VERSION ""

NS_ :

BS_:

BU_: T_Box HUT DMS DVR GW Tester

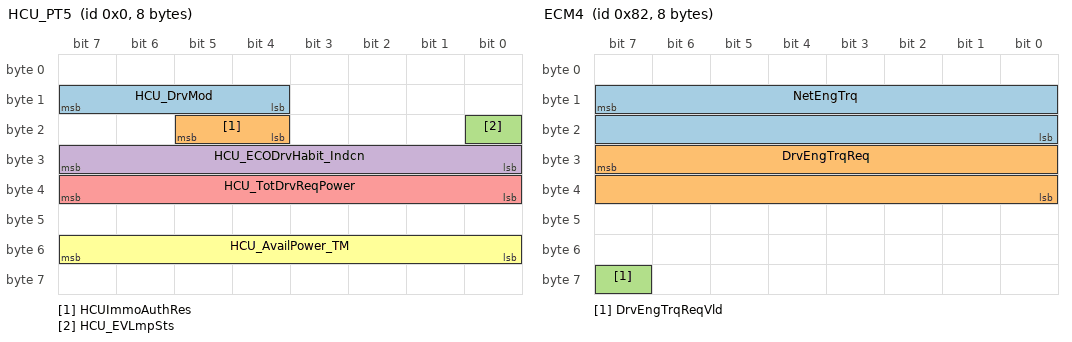
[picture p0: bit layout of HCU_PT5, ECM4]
BO_ 0 HCU_PT5: 8 GW
 SG_ HCU_DrvMod : 15|4@0+ (1,0) [0|15] ""  HUT
 SG_ HCUImmoAuthRes : 21|2@0+ (1,0) [0|3] ""  HUT
 SG_ HCU_EVLmpSts : 16|1@0+ (1,0) [0|1] ""  HUT
 SG_ HCU_ECODrvHabit_Indcn : 31|8@0+ (0.1,-10) [-10|10] ""  HUT
 SG_ HCU_TotDrvReqPower : 39|8@0+ (1,-100) [-100|100] "%"  HUT
 SG_ HCU_AvailPower_TM : 55|8@0+ (0.5,0) [0|50] "%"  HUT

BO_ 51 T_Box_FD1: 16 T_Box
 SG_ T_Box_RemtWinCtrl : 2|3@0+ (1,0) [0|7] ""  GW
 SG_ T_Box_RemtTrunkCtrl : 4|2@0+ (1,0) [0|3] ""  GW
 SG_ T_Box_RemtDoorLockCtrl : 7|3@0+ (1,0) [0|7] ""  GW,HUT
 SG_ T_Box_AudioMuteReq : 9|2@0+ (1,0) [0|3] ""  HUT
 SG_ T_Box_RemtDrvTempSet : 15|6@0+ (0.5,16) [16.5|31.5] "°C"  GW
 SG_ T_Box_RemtAutoCtrl : 17|2@0+ (1,0) [0|3] ""  GW
 SG_ T_Box_RemtPassTempSet : 23|6@0+ (0.5,16) [16.5|31.5] "°C"  GW
 SG_ T_Box_RemtSsCtrl : 27|4@0+ (1,0) [0|15] ""  GW
 SG_ T_Box_RemtSrCtrl : 31|4@0+ (1,0) [0|15] ""  GW
 SG_ T_Box_RemtDrvSeatVentnLvlSet : 34|3@0+ (1,0) [0|7] ""  GW
 SG_ T_Box_RemtPassSeatVentnLvlSet : 37|3@0+ (1,0) [0|7] ""  GW
 SG_ T_Box_RemtAIUReq : 39|2@0+ (1,0) [0|3] ""  GW
 SG_ T_Box_PM25AirQLvl : 43|4@0+ (1,0) [0|15] ""  HUT
 SG_ T_Box_RemtCarSearch : 45|2@0+ (1,0) [0|3] ""  GW
 SG_ T_Box_RemtEngCtrl : 47|2@0+ (1,0) [0|3] ""  GW
 SG_ T_Box_RemtDrvSeatHeatgLvlSet : 52|3@0+ (1,0) [0|7] ""  GW
 SG_ T_Box_RemtPassSeatHeatgLvlSet : 55|3@0+ (1,0) [0|7] ""  GW
 SG_ T_Box_PM25Dens : 49|10@0+ (1,0) [0|1023] "ug/m^3"  HUT
 SG_ FreshnessValue_T_Box_FD1 : 71|16@0+ (1,0) [0|65535] ""  GW,HUT
 SG_ MAC_Check_T_Box_FD1 : 87|48@0+ (1,0) [0|281474976710655] ""  GW,HUT

BO_ 53 PEPS5: 8 GW
 SG_ PEPS_T_BoxAuth1 : 7|64@0+ (1,0) [0|1.84467440737095E+019] ""  T_Box

BO_ 54 T_Box_FD2: 16 T_Box
 SG_ T_Box_PEPSAuth1 : 7|64@0+ (1,0) [0|1.84467440737096E+019] ""  GW

BO_ 70 PEPS11: 8 GW
 SG_ PEPS_T_BoxAuth2 : 7|64@0+ (1,0) [0|1.84467440737096E+019] ""  T_Box

BO_ 72 T_Box7: 16 T_Box
 SG_ T_Box_PEPSAuth2 : 7|64@0+ (1,0) [0|1.84467440737096E+019] ""  GW

BO_ 74 HUT6: 8 HUT
 SG_ AUTODefrost_TC : 6|2@0+ (1,0) [0|3] ""  GW
 SG_ AUTODefrost_VR : 4|2@0+ (1,0) [0|3] ""  GW
 SG_ LaneCalActvtCmd : 42|1@0+ (1,0) [0|1] ""  GW
 SG_ MODChgReq : 62|1@0+ (1,0) [0|1] ""  GW
 SG_ Radar_DispCmd : 40|1@0+ (1,0) [0|1] ""  GW
 SG_ Guid_Ovl_Display_Cmd : 7|1@0+ (1,0) [0|1] ""  GW
 SG_ Sgl_View_Sel : 36|4@0+ (1,0) [0|15] ""  GW
 SG_ SwToFieldCalRstCmd : 58|1@0+ (1,0) [0|1] ""  GW
 SG_ AutoViewChgCmd : 55|1@0+ (1,0) [0|1] ""  GW
 SG_ MdlColrChgCmd : 53|1@0+ (1,0) [0|1] ""  GW
 SG_ CarMdlTrsprcySwtCmd : 49|1@0+ (1,0) [0|1] ""  GW
 SG_ CarMdlDispCmd : 63|1@0+ (1,0) [0|1] ""  GW
 SG_ AutoAVMSwSet_Cmd : 57|1@0+ (1,0) [0|1] ""  GW
 SG_ FPAS_AutoModSwt : 60|1@0+ (1,0) [0|1] ""  GW
 SG_ MEBSwtSet : 61|1@0+ (1,0) [0|1] ""  GW
 SG_ WshSoftSwt : 56|1@0+ (1,0) [0|1] ""  GW
 SG_ View_SoftswitchCmd : 59|1@0+ (1,0) [0|1] ""  GW

BO_ 86 GLO_NASS1: 8 GW
 SG_ E_CALLSts : 2|3@0+ (1,0) [0|5] ""  HUT
 SG_ QuietVoiceReq : 7|1@0+ (1,0) [0|1] ""  HUT

BO_ 96 HCU_FD1: 64 GW
 SG_ HCU_AccelPedalPosn_Diag : 79|8@0+ (0.3937,0) [0|100.395] "%"  HUT
 SG_ HCU_AccelPedalPosn_DiagValid : 85|1@0+ (1,0) [0|1] ""  HUT
 SG_ HCU_RaceLaunchSts : 367|3@0+ (1,0) [0|7] ""  HUT
 SG_ HCU_RaceLaunchAvail : 364|2@0+ (1,0) [0|3] ""  HUT

BO_ 130 ECM4: 8 GW
 SG_ NetEngTrq : 15|16@0+ (0.0030518,-100) [-100|99.9966612] "%"  HUT
 SG_ DrvEngTrqReq : 31|16@0+ (0.0030518,-100) [-100|99.999713] "%"  HUT
 SG_ DrvEngTrqReqVld : 63|1@0+ (1,0) [0|1] ""  HUT

BO_ 132 ECM7: 8 GW
 SG_ EngTrqEstimdActGear : 31|16@0+ (0.0030518,-100) [-100|99.999713] "%"  HUT
 SG_ EngTrqEstimdActGear_Qf : 62|1@0+ (1,0) [0|1] ""  HUT

BO_ 134 ECM8: 8 GW
 SG_ TrqLoss : 47|16@0+ (0.0030518,-100) [-100|99.999713] "%"  HUT

BO_ 147 TMCU6: 8 GW
 SG_ TMCU_ActPosRotSpd : 15|16@0+ (1,0) [0|65534] "rpm"  HUT,T_Box,DMS,DVR

BO_ 161 CSA2: 8 GW
 SG_ SteerWheelAng : 15|15@0+ (0.1,0) [0|780] "deg"  HUT,DMS
 SG_ SteerWheelAngSign : 16|1@0+ (1,0) [0|1] ""  HUT,DMS

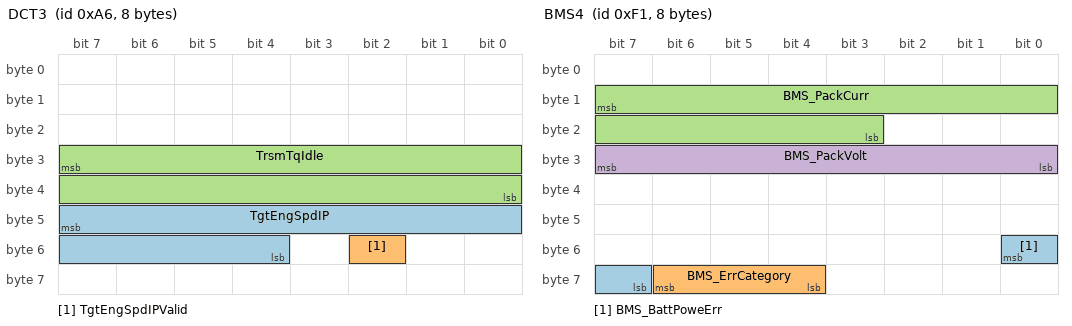
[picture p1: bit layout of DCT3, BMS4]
BO_ 166 DCT3: 8 GW
 SG_ TgtEngSpdIP : 47|12@0+ (2,0) [0|8190] "RPM"  HUT
 SG_ TgtEngSpdIPValid : 50|1@0+ (1,0) [0|1] ""  HUT
 SG_ TrsmTqIdle : 31|16@0+ (0.0030518,-100) [-100|99.9966612] "%"  HUT

BO_ 193 DHT_FD1: 64 GW
 SG_ TCU_ErrCategory : 103|8@0+ (1,0) [0|255] ""  HUT
 SG_ TCU_ParkErrCategory : 111|3@0+ (1,0) [0|7] "" Vector__XXX
 SG_ TCU_ClutchHotWarning : 233|2@0+ (1,0) [0|3] ""  HUT

BO_ 200 ESP11: 8 GW
 SG_ ESP_HMI_WarningOn : 41|2@0+ (1,0) [0|3] ""  HUT

BO_ 216 ESP10: 8 GW
 SG_ TgtRcprtnTrqSts : 47|2@0+ (1,0) [0|3] ""  HUT

BO_ 241 BMS4: 8 GW
 SG_ BMS_BattPoweErr : 48|2@0+ (1,0) [0|3] ""  HUT
 SG_ BMS_ErrCategory : 62|3@0+ (1,0) [0|7] ""  HUT
 SG_ BMS_PackCurr : 15|13@0+ (0.2,-500) [-500|500] "A"  HUT
 SG_ BMS_PackVolt : 31|8@0+ (2,0) [0|490] " V"  HUT

BO_ 258 ECM9: 8 GW
 SG_ AccelPedlPosnDiagc : 39|8@0+ (0.3937,0) [0|100.3935] "%"  HUT

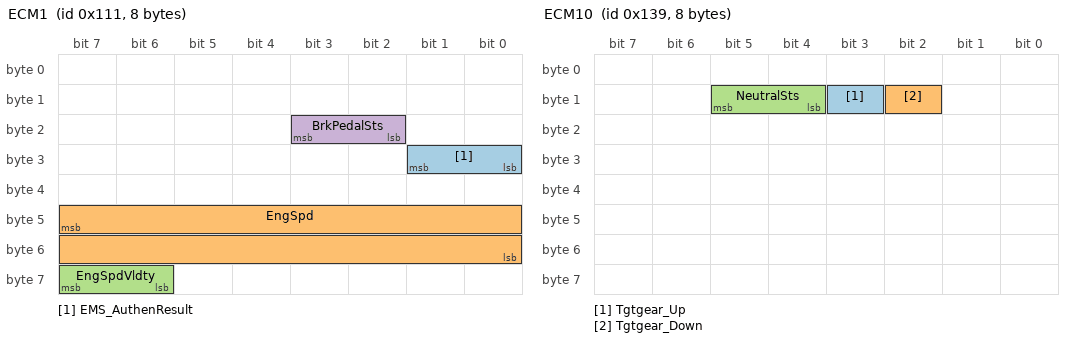
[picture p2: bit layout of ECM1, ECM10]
BO_ 273 ECM1: 8 GW
 SG_ EMS_AuthenResult : 25|2@0+ (1,0) [0|3] ""  HUT
 SG_ EngSpd : 47|16@0+ (0.125,0) [0|8191.875] "rpm"  HUT,T_Box,DMS,DVR
 SG_ EngSpdVldty : 63|2@0+ (1,0) [0|2] ""  HUT,T_Box,DMS,DVR
 SG_ BrkPedalSts : 19|2@0+ (1,0) [0|3] ""  HUT

BO_ 279 ECM_PT7: 8 GW
 SG_ EngState_PHEV : 31|3@0+ (1,0) [0|7] ""  HUT,DMS
 SG_ CruiseCtrlSts_PHEV : 55|4@0+ (1,0) [0|15] ""  HUT

BO_ 282 HCU_HP6: 8 GW
 SG_ HCU_GearSts : 36|4@0+ (1,0) [0|15] ""  T_Box,DMS

BO_ 288 Ibooster_FD2: 64 GW
 SG_ IB_Warn : 46|1@0+ (1,0) [0|1] ""  HUT

BO_ 311 ESP_FD2: 64 GW
 SG_ CheckSum_ESP2 : 71|8@0+ (1,0) [0|255] ""  HUT
 SG_ BrkDskOvrheatd : 75|1@0+ (1,0) [0|1] "" Vector__XXX
 SG_ NoBrkForce : 76|1@0+ (1,0) [0|1] "" Vector__XXX
 SG_ VehStandstill : 78|2@0+ (1,0) [0|3] "" Vector__XXX
 SG_ AEBIBActv : 81|1@0+ (1,0) [0|1] "" Vector__XXX
 SG_ AEBBAActv : 82|1@0+ (1,0) [0|1] "" Vector__XXX
 SG_ AEBAvailable : 83|1@0+ (1,0) [0|1] "" Vector__XXX
 SG_ ABPAvailable : 84|1@0+ (1,0) [0|1] "" Vector__XXX
 SG_ ABPActv : 85|1@0+ (1,0) [0|1] "" Vector__XXX
 SG_ ABAavailable : 86|1@0+ (1,0) [0|1] "" Vector__XXX
 SG_ ABAActv : 87|1@0+ (1,0) [0|1] "" Vector__XXX
 SG_ HDCFault : 89|2@0+ (1,0) [0|3] ""  HUT
 SG_ HDCCtrl : 91|2@0+ (1,0) [0|2] ""  HUT
 SG_ CDDActv : 92|1@0+ (1,0) [0|1] "" Vector__XXX
 SG_ CDDAvailable : 93|1@0+ (1,0) [0|1] "" Vector__XXX
 SG_ AWBAvailable : 94|1@0+ (1,0) [0|1] "" Vector__XXX
 SG_ AWBActv : 95|1@0+ (1,0) [0|1] "" Vector__XXX
 SG_ AVHErrSts : 99|2@0+ (1,0) [0|3] ""  HUT
 SG_ AVHSts : 101|2@0+ (1,0) [0|2] ""  HUT
 SG_ CDPActv : 103|1@0+ (1,0) [0|1] ""  HUT
 SG_ RollingCounter_ESP2 : 123|4@0+ (1,0) [0|15] ""  HUT
 SG_ CheckSum_ESP1 : 135|8@0+ (1,0) [0|255] ""  HUT
 SG_ ESPFuncOffSts : 140|1@0+ (1,0) [0|1] ""  HUT
 SG_ ESPActvInfoLmp : 141|1@0+ (1,0) [0|1] ""  HUT
 SG_ ESPBrkLmpCtrl : 142|1@0+ (1,0) [0|1] "" Vector__XXX
 SG_ ESPFailSts : 143|1@0+ (1,0) [0|1] ""  HUT
 SG_ ESP_MasterCylBrkPressVld : 144|1@0+ (1,0) [0|1] "" Vector__XXX
 SG_ MSRActv : 149|1@0+ (1,0) [0|1] "" Vector__XXX
 SG_ VDCActv : 148|1@0+ (1,0) [0|1] "" Vector__XXX
 SG_ PTCActv : 150|1@0+ (1,0) [0|1] "" Vector__XXX
 SG_ BTCActv : 151|1@0+ (1,0) [0|1] "" Vector__XXX
 SG_ ESP_MasterCylBrkPress : 159|16@0+ (0.03125,-42.5) [-42.5|425] "bar" Vector__XXX
 SG_ RollingCounter_ESP1 : 187|4@0+ (1,0) [0|15] ""  HUT
 SG_ CheckSum_ABS3 : 327|8@0+ (1,0) [0|255] ""  HUT
 SG_ ABSFailSts : 335|1@0+ (1,0) [0|1] ""  HUT
 SG_ EBDFailSts : 334|1@0+ (1,0) [0|1] ""  HUT
 SG_ VehSpdVld : 333|1@0+ (1,0) [0|1] ""  HUT,T_Box,DMS,DVR
 SG_ VehSpd : 332|13@0+ (0.05625,0) [0|299.98125] "kph"  HUT,T_Box,DMS,DVR
 SG_ EBDActv : 351|1@0+ (1,0) [0|1] "" Vector__XXX
 SG_ ABSActv : 347|1@0+ (1,0) [0|1] "" Vector__XXX
 SG_ VehOdoInfoSts : 346|1@0+ (1,0) [0|1] ""  HUT,T_Box
 SG_ VehOdoInfo : 345|10@0+ (1,0) [0|999] "m"  HUT,T_Box
 SG_ RollingCounter_ABS3 : 379|4@0+ (1,0) [0|15] ""  HUT
 SG_ FreshnessValue_ESP_FD2 : 455|16@0+ (1,0) [0|65535] "" Vector__XXX
 SG_ MAC_Check_ESP_FD2 : 471|48@0+ (1,0) [0|281474976710655] "" Vector__XXX

BO_ 313 ECM10: 8 GW
 SG_ Tgtgear_Up : 11|1@0+ (1,0) [0|1] ""  HUT
 SG_ Tgtgear_Down : 10|1@0+ (1,0) [0|1] ""  HUT
 SG_ NeutralSts : 13|2@0+ (1,0) [0|3] ""  T_Box

BO_ 325 ESP2: 16 GW
 SG_ CheckSum_ESP2_ : 7|8@0+ (1,0) [0|255] ""  HUT
 SG_ HDCFault_ : 25|2@0+ (1,0) [0|3] ""  HUT
 SG_ HDCCtrl_ : 27|2@0+ (1,0) [0|2] ""  HUT
 SG_ AVHErrSts_ : 35|2@0+ (1,0) [0|3] ""  HUT
 SG_ AVHSts_ : 37|2@0+ (1,0) [0|2] ""  HUT
 SG_ CDPActv_ : 39|1@0+ (1,0) [0|1] ""  HUT
 SG_ DrivingModDis : 55|5@0+ (1,0) [0|31] ""  HUT
 SG_ DrivingModReq_ESP : 32|5@0+ (1,0) [0|31] ""  HUT
 SG_ TAB_Available : 40|1@0+ (1,0) [0|1] ""  HUT
 SG_ TAB_Sts : 49|2@0+ (1,0) [0|3] ""  HUT
 SG_ RollingCounter_ESP2_ : 59|4@0+ (1,0) [0|15] ""  HUT
 SG_ FreshnessValue_ESP2 : 71|16@0+ (1,0) [0|65535] ""  HUT
 SG_ MAC_Check_ESP2 : 87|48@0+ (1,0) [0|281474976710655] ""  HUT

BO_ 327 EPS_FD1: 64 GW
 SG_ CheckSum_EPS1 : 7|8@0+ (1,0) [0|255] ""  HUT
 SG_ EPS_FailSts : 13|2@0+ (1,0) [0|3] ""  HUT
 SG_ EPS_TrqSnsrSts : 14|1@0+ (1,0) [0|1] "" Vector__XXX
 SG_ EPS_SteerMod : 55|3@0+ (1,0) [0|7] ""  HUT
 SG_ RollingCounter_EPS1 : 59|4@0+ (1,0) [0|15] ""  HUT
 SG_ EPS_LKATorqOvrlDlvd : 111|16@0+ (0.01,-15) [-15|15] "Nm" Vector__XXX
 SG_ EPS_LKATorqOvrlDlvdVld : 127|1@0+ (1,0) [0|1] "" Vector__XXX
 SG_ EPS_LKATrqOvlDlvdSts : 125|2@0+ (1,0) [0|3] "" Vector__XXX

BO_ 329 ESP1: 16 GW
 SG_ CheckSum_ESP1_ : 7|8@0+ (1,0) [0|255] ""  HUT
 SG_ ESPFuncOffSts_ : 12|1@0+ (1,0) [0|1] ""  HUT
 SG_ ESPActvInfoLmp_ : 13|1@0+ (1,0) [0|1] ""  HUT
 SG_ ESPFailSts_ : 15|1@0+ (1,0) [0|1] ""  HUT
 SG_ RollingCounter_ESP1_ : 59|4@0+ (1,0) [0|15] ""  HUT
 SG_ FreshnessValue_ESP1 : 71|16@0+ (1,0) [0|65535] ""  HUT
 SG_ MAC_Check_ESP1 : 87|48@0+ (1,0) [0|281474976710655] ""  HUT

BO_ 338 ELD1: 8 GW
 SG_ RearELDLckSts : 39|4@0+ (1,0) [0|15] ""  HUT

BO_ 347 HAP_FD1: 64 GW
 SG_ APS_PrkgMod : 117|2@0+ (1,0) [0|3] ""  HUT
 SG_ APS_ProcBar : 111|7@0+ (1,0) [0|127] "%"  HUT
 SG_ APS_SwtSts : 104|1@0+ (1,0) [0|1] ""  HUT
 SG_ APS_SlotDisp : 76|3@0+ (1,0) [0|7] ""  HUT
 SG_ APS_SysSoundIndcn : 79|3@0+ (1,0) [0|7] ""  HUT
 SG_ APS_PrkgTyp : 119|2@0+ (1,0) [0|3] ""  HUT
 SG_ APS_TextDisp : 103|8@0+ (1,0) [0|63] ""  HUT
 SG_ APS_WorkSts : 146|3@0+ (1,0) [0|7] ""  HUT,DVR
 SG_ MEB_AVHReq : 168|1@0+ (1,0) [0|1] ""  DVR
 SG_ LParaPrkgOutVald : 283|1@0+ (1,0) [0|1] ""  HUT
 SG_ RParaPrkgOutVald : 282|1@0+ (1,0) [0|1] ""  HUT
 SG_ HeadVertPrkgOutVald : 281|1@0+ (1,0) [0|1] ""  HUT
 SG_ TailVertPrkgOutVald : 280|1@0+ (1,0) [0|1] ""  HUT
 SG_ HAP_SwtDispCtrlCmd : 279|3@0+ (1,0) [0|7] ""  HUT
 SG_ P2P_PahDelSts : 265|2@0+ (1,0) [0|3] ""  HUT
 SG_ P2P_SelfDetErrCode : 276|4@0+ (1,0) [0|15] ""  HUT
 SG_ P2P_SelfDetSts : 287|2@0+ (1,0) [0|3] ""  HUT
 SG_ P2P_Pah1Avail : 272|1@0+ (1,0) [0|1] ""  HUT
 SG_ P2P_Pah2Avail : 285|1@0+ (1,0) [0|1] ""  HUT
 SG_ HAP_PrkgModCurrSts : 269|4@0+ (1,0) [0|15] ""  HUT
 SG_ APS_MovgDirc : 295|2@0+ (1,0) [0|3] ""  HUT

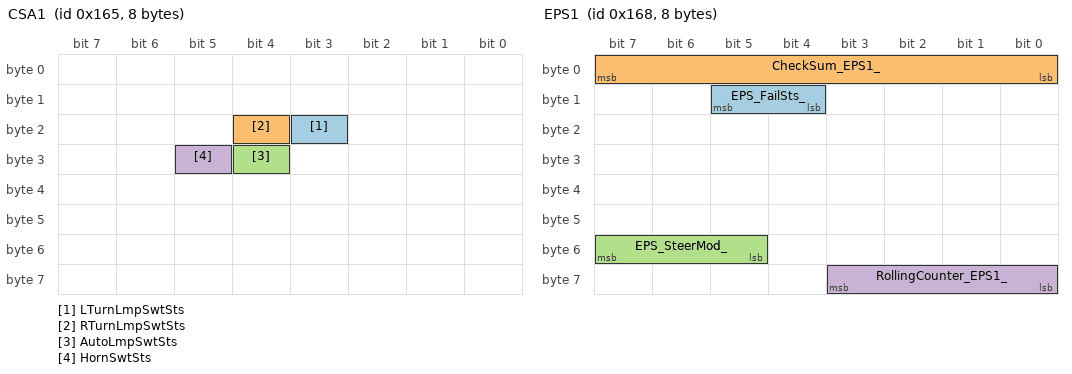
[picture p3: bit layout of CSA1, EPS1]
BO_ 357 CSA1: 8 GW
 SG_ LTurnLmpSwtSts : 19|1@0+ (1,0) [0|1] ""  DMS
 SG_ RTurnLmpSwtSts : 20|1@0+ (1,0) [0|1] ""  DMS
 SG_ AutoLmpSwtSts : 28|1@0+ (1,0) [0|1] ""  HUT
 SG_ HornSwtSts : 29|1@0+ (1,0) [0|1] ""  DVR

BO_ 360 EPS1: 8 GW
 SG_ EPS_FailSts_ : 13|2@0+ (1,0) [0|3] ""  HUT
 SG_ CheckSum_EPS1_ : 7|8@0+ (1,0) [0|255] ""  HUT
 SG_ EPS_SteerMod_ : 55|3@0+ (1,0) [0|7] ""  HUT
 SG_ RollingCounter_EPS1_ : 59|4@0+ (1,0) [0|15] ""  HUT

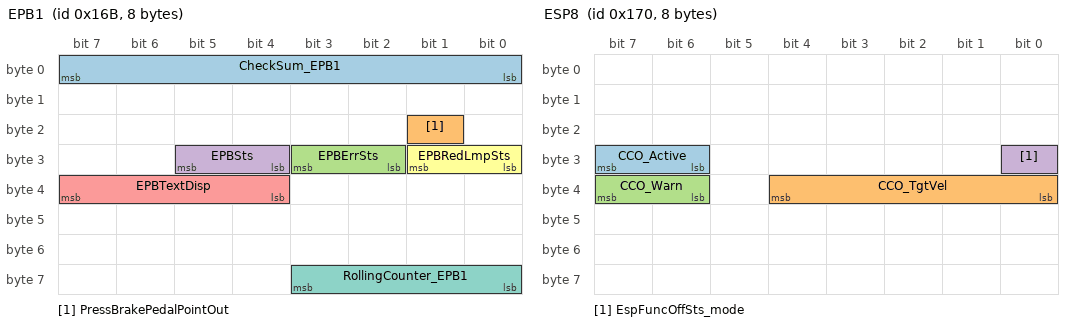
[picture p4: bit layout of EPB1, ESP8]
BO_ 363 EPB1: 8 GW
 SG_ CheckSum_EPB1 : 7|8@0+ (1,0) [0|255] ""  HUT
 SG_ PressBrakePedalPointOut : 17|1@0+ (1,0) [0|1] ""  HUT
 SG_ EPBErrSts : 27|2@0+ (1,0) [0|3] ""  HUT
 SG_ EPBSts : 29|2@0+ (1,0) [0|3] ""  HUT
 SG_ EPBTextDisp : 39|4@0+ (1,0) [0|15] ""  HUT
 SG_ EPBRedLmpSts : 25|2@0+ (1,0) [0|3] ""  HUT
 SG_ RollingCounter_EPB1 : 59|4@0+ (1,0) [0|15] ""  HUT

BO_ 367 RSDS_FD1: 64 GW
 SG_ RSDS_IPSoundReq : 81|2@0+ (1,0) [0|3] ""  HUT
 SG_ RSDS_ErrSts : 119|1@0+ (1,0) [0|1] ""  HUT
 SG_ RSDS_BrkgTrig : 118|1@0+ (1,0) [0|1] ""  HUT
 SG_ RSDS_BliSts : 117|1@0+ (1,0) [0|1] ""  HUT
 SG_ RSDS_TrailerSts : 116|1@0+ (1,0) [0|1] ""  HUT
 SG_ RSDS_LCAResp : 115|1@0+ (1,0) [0|1] ""  HUT
 SG_ RSDS_DOWResp : 114|1@0+ (1,0) [0|1] ""  HUT
 SG_ RSDS_RCWResp : 113|1@0+ (1,0) [0|1] ""  HUT
 SG_ RSDS_RCTAResp : 112|1@0+ (1,0) [0|1] ""  HUT
 SG_ RSDS_RCTABrkResp : 127|1@0+ (1,0) [0|1] ""  HUT
 SG_ RSDS_RCW_Trigger : 105|2@0+ (1,0) [0|3] ""  HUT
 SG_ RSDS_CTA_Actv : 126|1@0+ (1,0) [0|1] ""  HUT

BO_ 368 ESP8: 8 GW
 SG_ CCO_Active : 31|2@0+ (1,0) [0|3] ""  HUT
 SG_ CCO_TgtVel : 36|5@0+ (1,2.6) [2.6|33.6] "kph"  HUT
 SG_ CCO_Warn : 39|2@0+ (1,0) [0|3] ""  HUT
 SG_ EspFuncOffSts_mode : 24|1@0+ (1,0) [0|1] ""  HUT

BO_ 395 AEB_FD1: 64 GW
 SG_ AEB_ObjSty : 111|3@0+ (1,0) [0|7] ""  HUT

BO_ 407 HCU_FD7: 64 GW
 SG_ HCU_IntelEngIdlChrgnSts : 74|3@0+ (1,0) [0|7] ""  T_Box

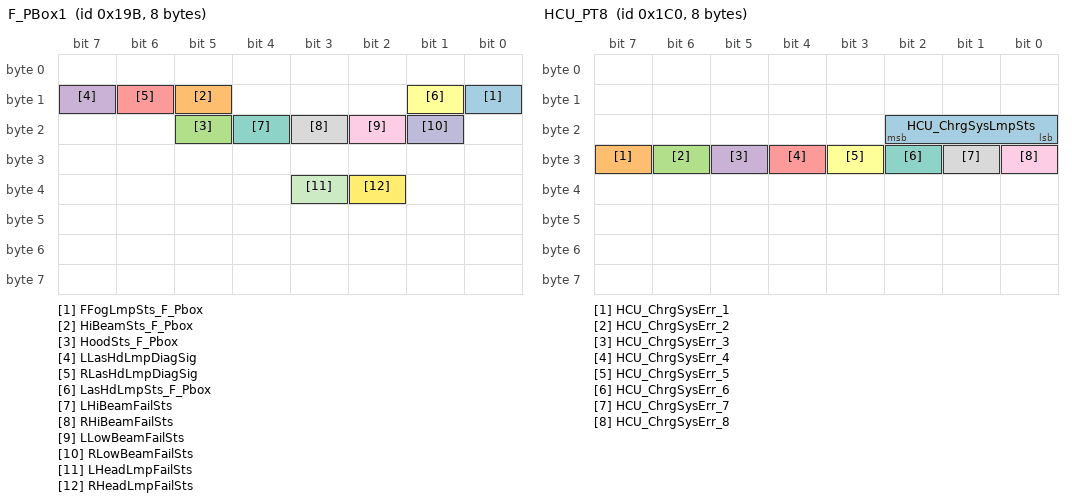
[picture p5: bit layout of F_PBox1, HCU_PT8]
BO_ 411 F_PBox1: 8 GW
 SG_ FFogLmpSts_F_Pbox : 8|1@0+ (1,0) [0|1] ""  HUT
 SG_ HiBeamSts_F_Pbox : 13|1@0+ (1,0) [0|1] ""  HUT
 SG_ HoodSts_F_Pbox : 21|1@0+ (1,0) [0|1] ""  HUT,T_Box
 SG_ LLasHdLmpDiagSig : 15|1@0+ (1,0) [0|1] ""  HUT
 SG_ RLasHdLmpDiagSig : 14|1@0+ (1,0) [0|1] ""  HUT
 SG_ LasHdLmpSts_F_Pbox : 9|1@0+ (1,0) [0|1] ""  HUT
 SG_ LHiBeamFailSts : 20|1@0+ (1,0) [0|1] ""  HUT
 SG_ RHiBeamFailSts : 19|1@0+ (1,0) [0|1] ""  HUT
 SG_ LLowBeamFailSts : 18|1@0+ (1,0) [0|1] ""  HUT
 SG_ RLowBeamFailSts : 17|1@0+ (1,0) [0|1] ""  HUT
 SG_ LHeadLmpFailSts : 35|1@0+ (1,0) [0|1] ""  HUT
 SG_ RHeadLmpFailSts : 34|1@0+ (1,0) [0|1] ""  HUT

BO_ 412 R_PBox1: 16 GW
 SG_ HiPosnBrkLmpFailSts : 15|1@0+ (1,0) [0|1] ""  HUT
 SG_ LicPlateLmpFailSts : 14|1@0+ (1,0) [0|1] ""  HUT
 SG_ LBrkLmpFailSts : 13|1@0+ (1,0) [0|1] ""  HUT
 SG_ RFogLmpFailSts_R_Pbox : 29|1@0+ (1,0) [0|1] ""  HUT
 SG_ RFogLmpSts_R_Pbox : 28|1@0+ (1,0) [0|1] ""  HUT
 SG_ ParkLmpSts_R_Pbox : 26|1@0+ (1,0) [0|1] ""  HUT
 SG_ RBrkLmpFailSts : 12|1@0+ (1,0) [0|1] ""  HUT
 SG_ PosnLmpOutpSts_R_Pbox : 11|1@0+ (1,0) [0|1] ""  HUT
 SG_ RRPosnLmpFailSts : 10|1@0+ (1,0) [0|1] ""  HUT
 SG_ RvsLmpFailSts : 9|1@0+ (1,0) [0|1] ""  HUT
 SG_ LRPosnLmpFailSts : 8|1@0+ (1,0) [0|1] ""  HUT
 SG_ RTurnLmpFailSts : 19|2@0+ (1,0) [0|3] ""  HUT
 SG_ LTurnLmpFailSts : 17|2@0+ (1,0) [0|3] ""  HUT
 SG_ LTurnLmpSts_R_Pbox : 31|1@0+ (1,0) [0|1] ""  HUT,T_Box
 SG_ RTurnLmpSts_R_Pbox : 30|1@0+ (1,0) [0|1] ""  HUT,T_Box
 SG_ RWinHeatgIconRlyCmd : 21|1@0+ (1,0) [0|1] ""  HUT,T_Box
 SG_ RWinHeatgFailSts : 20|1@0+ (1,0) [0|1] ""  HUT
 SG_ FreshnessValue_R_PBox1 : 71|16@0+ (1,0) [0|65535] ""  HUT,T_Box
 SG_ MAC_Check_R_PBox1 : 87|48@0+ (1,0) [0|281474976710655] ""  HUT,T_Box

BO_ 448 HCU_PT8: 8 GW
 SG_ HCU_ChrgSysLmpSts : 18|3@0+ (1,0) [0|7] ""  HUT
 SG_ HCU_ChrgSysErr_1 : 31|1@0+ (1,0) [0|1] ""  HUT
 SG_ HCU_ChrgSysErr_2 : 30|1@0+ (1,0) [0|1] ""  HUT
 SG_ HCU_ChrgSysErr_3 : 29|1@0+ (1,0) [0|1] ""  HUT
 SG_ HCU_ChrgSysErr_4 : 28|1@0+ (1,0) [0|1] ""  HUT
 SG_ HCU_ChrgSysErr_5 : 27|1@0+ (1,0) [0|1] ""  HUT
 SG_ HCU_ChrgSysErr_6 : 26|1@0+ (1,0) [0|1] ""  HUT
 SG_ HCU_ChrgSysErr_7 : 25|1@0+ (1,0) [0|1] ""  HUT
 SG_ HCU_ChrgSysErr_8 : 24|1@0+ (1,0) [0|1] ""  HUT

BO_ 481 T_Box_FD4: 16 T_Box
 SG_ T_Box_BMSReMtPreHeatT : 7|11@0+ (1,0) [0|1440] ""  GW
 SG_ Phone_ChrgnMode : 10|2@0+ (1,0) [0|3] ""  GW
 SG_ T_Box_IntelEngIdlChrgnSwt : 21|2@0+ (1,0) [0|3] ""  GW
 SG_ T_Box_BattKeepTemp : 17|2@0+ (1,0) [0|3] ""  GW
 SG_ T_Box_RemtFrntDefrostCtrl : 19|2@0+ (1,0) [0|3] ""  GW
 SG_ T_Box_RemtRearDefrostCtrl : 39|2@0+ (1,0) [0|3] ""  GW
 SG_ TBOX_RemtVideoMonrEnaReq_APP : 41|2@0+ (1,0) [0|3] ""  DVR
 SG_ T_Box_RemtCockpitClnReq : 53|2@0+ (1,0) [0|3] ""  GW
 SG_ T_Box_RemtSdlMod : 55|2@0+ (1,0) [0|3] ""  GW

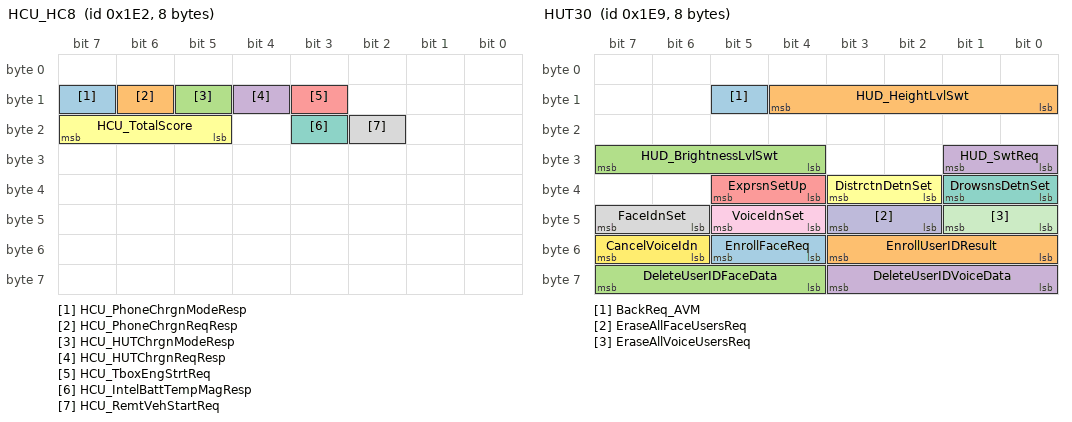
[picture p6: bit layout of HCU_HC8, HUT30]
BO_ 482 HCU_HC8: 8 GW
 SG_ HCU_PhoneChrgnModeResp : 15|1@0+ (1,0) [0|1] ""  T_Box
 SG_ HCU_PhoneChrgnReqResp : 14|1@0+ (1,0) [0|1] ""  T_Box
 SG_ HCU_HUTChrgnModeResp : 13|1@0+ (1,0) [0|1] ""  T_Box
 SG_ HCU_HUTChrgnReqResp : 12|1@0+ (1,0) [0|1] ""  T_Box
 SG_ HCU_TboxEngStrtReq : 11|1@0+ (1,0) [0|1] ""  T_Box
 SG_ HCU_TotalScore : 23|3@0+ (1,0) [0|5] ""  HUT
 SG_ HCU_IntelBattTempMagResp : 19|1@0+ (1,0) [0|1] ""  T_Box
 SG_ HCU_RemtVehStartReq : 18|1@0+ (1,0) [0|1] ""  T_Box

BO_ 483 BMS_FD14: 8 GW
 SG_ BMS_BattKeepTempResp_PHEV : 11|2@0+ (1,0) [0|3] ""  T_Box

BO_ 489 HUT30: 8 HUT
 SG_ BackReq_AVM : 13|1@0+ (1,0) [0|1] ""  GW
 SG_ HUD_HeightLvlSwt : 12|5@0+ (1,0) [0|31] ""  GW
 SG_ HUD_BrightnessLvlSwt : 31|4@0+ (1,0) [0|15] ""  GW
 SG_ HUD_SwtReq : 25|2@0+ (1,0) [0|3] ""  GW
 SG_ ExprsnSetUp : 37|2@0+ (1,0) [0|3] ""  DMS
 SG_ DistrctnDetnSet : 35|2@0+ (1,0) [0|3] ""  DMS
 SG_ DrowsnsDetnSet : 33|2@0+ (1,0) [0|3] ""  DMS
 SG_ FaceIdnSet : 47|2@0+ (1,0) [0|3] ""  DMS
 SG_ VoiceIdnSet : 45|2@0+ (1,0) [0|3] ""  DMS
 SG_ EraseAllFaceUsersReq : 43|2@0+ (1,0) [0|3] ""  DMS
 SG_ EraseAllVoiceUsersReq : 41|2@0+ (1,0) [0|3] ""  DMS
 SG_ CancelVoiceIdn : 55|2@0+ (1,0) [0|3] ""  DMS
 SG_ EnrollFaceReq : 53|2@0+ (1,0) [0|3] ""  DMS
 SG_ EnrollUserIDResult : 51|4@0+ (1,0) [0|15] ""  DMS
 SG_ DeleteUserIDFaceData : 63|4@0+ (1,0) [0|15] ""  DMS
 SG_ DeleteUserIDVoiceData : 59|4@0+ (1,0) [0|15] ""  DMS

BO_ 493 HUT33: 8 HUT
 SG_ MbrMonrEnReq_TC : 1|2@0+ (1,0) [0|3] ""  GW
 SG_ ApproachLampSet : 7|2@0+ (1,0) [0|3] ""  GW
 SG_ FlaoutUnlockSet : 5|2@0+ (1,0) [0|3] ""  GW
 SG_ SuperLockSet : 3|2@0+ (1,0) [0|3] ""  GW
 SG_ PrkInDirChoice : 12|2@0+ (1,0) [0|3] ""  GW
 SG_ PathLrngFinshCmd : 17|1@0+ (1,0) [0|1] ""  GW
 SG_ PathLrngStartCmd : 18|1@0+ (1,0) [0|1] ""  GW
 SG_ SelPrkOutDirReq : 23|3@0+ (1,0) [0|7] ""  GW
 SG_ ParkMdlCmd : 19|1@0+ (1,0) [0|1] ""  GW
 SG_ BackReq_APS : 20|1@0+ (1,0) [0|1] ""  GW
 SG_ StartPrkgPath2Cmd : 25|1@0+ (1,0) [0|1] ""  GW
 SG_ DeletePath2Cmd : 26|1@0+ (1,0) [0|1] ""  GW
 SG_ StartPrkgPath1Cmd : 27|1@0+ (1,0) [0|1] ""  GW
 SG_ DeletePath1Cmd : 28|1@0+ (1,0) [0|1] ""  GW
 SG_ SelPrkgFctnCmd : 31|3@0+ (1,0) [0|7] ""  GW
 SG_ RLWinSwtReq_VR : 34|3@0+ (1,0) [0|7] ""  GW
 SG_ RRWinSwtReq_VR : 55|3@0+ (1,0) [0|7] ""  GW
 SG_ DrvWinSwtReq_VR : 15|3@0+ (1,0) [0|7] ""  GW
 SG_ PassWinSwtReq_VR : 37|3@0+ (1,0) [0|7] ""  GW

BO_ 494 HUT15: 16 HUT
 SG_ ACOperMod_TC : 7|2@0+ (1,0) [0|3] ""  GW
 SG_ ACOperMod_VR : 5|2@0+ (1,0) [0|3] ""  GW
 SG_ SteerWheelHeatSwtReq : 3|2@0+ (1,0) [0|3] ""  GW
 SG_ ACDrvSetTempSteplsReq_TC : 23|6@0+ (0.5,15.5) [16|32] ""  GW
 SG_ ACPassSetTempSteplsReq_TC : 31|6@0+ (0.5,15.5) [16|32] ""  GW
 SG_ SDWSwtSet : 39|1@0+ (1,0) [0|1] ""  GW
 SG_ APSSwtReq_VR : 55|2@0+ (1,0) [0|3] ""  GW
 SG_ PASExitSpdSwt : 53|2@0+ (1,0) [0|3] ""  GW
 SG_ APSPrkgTypSeln : 34|2@0+ (1,0) [0|3] ""  GW
 SG_ SunShadeSwtReq_VR : 43|4@0+ (1,0) [0|15] ""  GW
 SG_ SunRoofSwtReq_VR : 47|4@0+ (1,0) [0|15] ""  GW
 SG_ SportModLightSet : 1|2@0+ (1,0) [0|3] ""  GW
 SG_ ABSLmpSet : 14|1@0+ (1,0) [0|1] ""  GW
 SG_ AutoWshWipSet : 12|2@0+ (1,0) [0|3] ""  GW
 SG_ SeekVehSet : 10|2@0+ (1,0) [0|3] ""  GW
 SG_ SpdAutoLockModSet : 25|2@0+ (1,0) [0|3] ""  GW
 SG_ ParkLmpSet : 8|1@0+ (1,0) [0|1] ""  GW
 SG_ DoorUnlockModSet : 15|1@0+ (1,0) [0|1] ""  GW
 SG_ ACEAHReq_TC : 32|1@0+ (1,0) [0|1] "" Vector__XXX
 SG_ ACEAHReq_VR : 38|2@0+ (1,0) [0|3] "" Vector__XXX
 SG_ FreshnessValue_HUT15 : 71|16@0+ (1,0) [0|65535] ""  GW
 SG_ MAC_Check_HUT15 : 87|48@0+ (1,0) [0|281474976710655] ""  GW

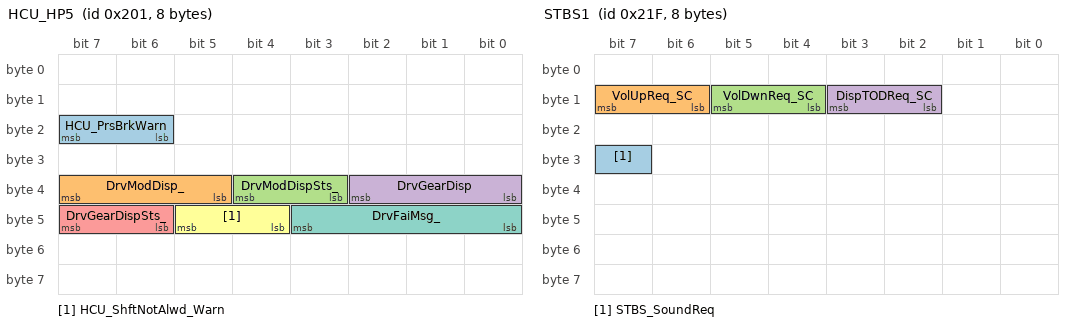
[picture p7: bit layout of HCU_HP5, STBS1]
BO_ 513 HCU_HP5: 8 GW
 SG_ HCU_PrsBrkWarn : 23|2@0+ (1,0) [0|3] ""  HUT
 SG_ DrvModDisp_ : 39|3@0+ (1,0) [0|7] ""  HUT
 SG_ DrvModDispSts_ : 36|2@0+ (1,0) [0|3] ""  HUT
 SG_ DrvGearDisp : 34|3@0+ (1,0) [0|7] ""  HUT
 SG_ DrvGearDispSts_ : 47|2@0+ (1,0) [0|3] ""  HUT
 SG_ HCU_ShftNotAlwd_Warn : 45|2@0+ (1,0) [0|3] ""  HUT
 SG_ DrvFaiMsg_ : 43|4@0+ (1,0) [0|15] ""  HUT

BO_ 543 STBS1: 8 GW
 SG_ STBS_SoundReq : 31|1@0+ (1,0) [0|1] ""  HUT
 SG_ VolUpReq_SC : 15|2@0+ (1,0) [0|3] ""  HUT
 SG_ VolDwnReq_SC : 13|2@0+ (1,0) [0|3] ""  HUT
 SG_ DispTODReq_SC : 11|2@0+ (1,0) [0|3] ""  HUT

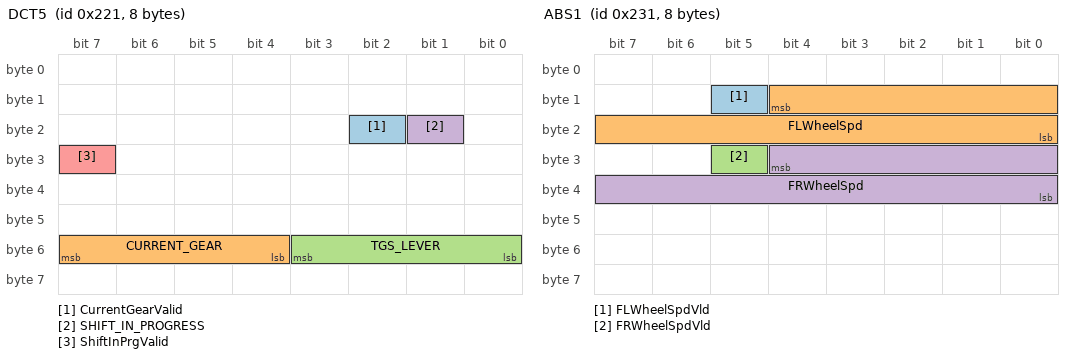
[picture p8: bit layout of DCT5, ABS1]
BO_ 545 DCT5: 8 GW
 SG_ CurrentGearValid : 18|1@0+ (1,0) [0|1] ""  HUT,DMS
 SG_ CURRENT_GEAR : 55|4@0+ (1,0) [0|15] ""  HUT,T_Box,DMS
 SG_ TGS_LEVER : 51|4@0+ (1,0) [0|15] ""  HUT,T_Box
 SG_ SHIFT_IN_PROGRESS : 17|1@0+ (1,0) [0|1] ""  HUT
 SG_ ShiftInPrgValid : 31|1@0+ (1,0) [0|1] ""  HUT

BO_ 551 AEB_FD2: 64 GW
 SG_ Checksum_AEB2 : 71|8@0+ (1,0) [0|255] ""  HUT
 SG_ AEB_PedResp : 79|1@0+ (1,0) [0|1] ""  HUT
 SG_ AEB_VehResp : 78|1@0+ (1,0) [0|1] ""  HUT
 SG_ FCW_Snvty : 77|2@0+ (1,0) [0|3] ""  HUT
 SG_ AEB_JA_Resp : 75|1@0+ (1,0) [0|1] ""  HUT
 SG_ RollingCounter_AEB2 : 123|4@0+ (1,0) [0|15] ""  HUT
 SG_ Checksum_AEB3 : 135|8@0+ (1,0) [0|255] ""  HUT
 SG_ AEB_VehTrig : 143|1@0+ (1,0) [0|1] ""  HUT
 SG_ AEB_PedTrig : 142|1@0+ (1,0) [0|1] ""  HUT
 SG_ FCW_AEB_VehFctSts : 138|2@0+ (1,0) [0|3] ""  HUT
 SG_ FCW_AEB_PedFctSts : 151|2@0+ (1,0) [0|3] ""  HUT
 SG_ FCW_Warn : 149|2@0+ (1,0) [0|3] ""  HUT
 SG_ AEB_JAFuncSts : 147|2@0+ (1,0) [0|3] ""  HUT
 SG_ AEB_JA_Warn : 145|2@0+ (1,0) [0|3] ""  HUT
 SG_ AEB_JABrkTrig : 159|2@0+ (1,0) [0|3] ""  HUT
 SG_ RollingCounter_AEB3 : 187|4@0+ (1,0) [0|15] ""  HUT
 SG_ FreshnessValue_AEB_FD2 : 455|16@0+ (1,0) [0|65535] ""  HUT
 SG_ MAC_Check_AEB_FD2 : 471|48@0+ (1,0) [0|281474976710655] ""  HUT

BO_ 561 ABS1: 8 GW
 SG_ FLWheelSpdVld : 13|1@0+ (1,0) [0|1] ""  HUT
 SG_ FLWheelSpd : 12|13@0+ (0.05625,0) [0|299.98125] "km/h"  HUT
 SG_ FRWheelSpdVld : 29|1@0+ (1,0) [0|1] ""  HUT
 SG_ FRWheelSpd : 28|13@0+ (0.05625,0) [0|299.98125] "km/h"  HUT

BO_ 565 DCT7: 16 GW
 SG_ CheckSum_DCT7 : 7|8@0+ (1,0) [0|255] ""  HUT
 SG_ DCT_RaceModeSts : 10|3@0+ (1,0) [0|7] ""  HUT
 SG_ DCT_PrsBrk_Warn : 31|2@0+ (1,0) [0|3] ""  HUT
 SG_ DCT_ShftNotAlwd_Warn : 29|2@0+ (1,0) [0|3] ""  HUT
 SG_ DCT_ShftRecom_M : 27|2@0+ (1,0) [0|3] ""  HUT
 SG_ DrvWarnMsg : 39|3@0+ (1,0) [0|7] ""  HUT
 SG_ DrvFaiMsg : 36|4@0+ (1,0) [0|15] ""  HUT
 SG_ DrvModDisp : 47|3@0+ (1,0) [0|7] ""  HUT
 SG_ DrvModDispSts : 44|2@0+ (1,0) [0|3] ""  HUT
 SG_ DrvAutoGearDisp : 63|4@0+ (1,0) [0|15] ""  HUT
 SG_ DrvGearDispSts : 55|2@0+ (1,0) [0|3] ""  HUT
 SG_ RollingCounter_DCT7 : 59|4@0+ (1,0) [0|15] ""  HUT
 SG_ FreshnessValue_DCT7 : 71|16@0+ (1,0) [0|65535] ""  HUT
 SG_ MAC_Check_DCT7 : 87|48@0+ (1,0) [0|281474976710655] ""  HUT

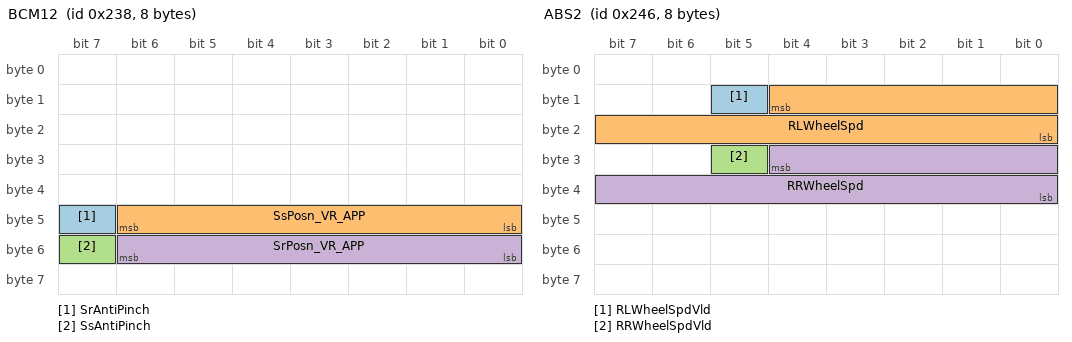
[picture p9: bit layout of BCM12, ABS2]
BO_ 568 BCM12: 8 GW
 SG_ SrAntiPinch : 47|1@0+ (1,0) [0|1] ""  HUT,T_Box
 SG_ SsPosn_VR_APP : 46|7@0+ (1,0) [0|127] ""  HUT,T_Box
 SG_ SsAntiPinch : 55|1@0+ (1,0) [0|1] ""  HUT,T_Box
 SG_ SrPosn_VR_APP : 54|7@0+ (1,0) [0|127] ""  HUT,T_Box

BO_ 573 IFC_FD2: 64 GW
 SG_ Checksum_IFC3 : 71|8@0+ (1,0) [0|255] ""  HUT
 SG_ LDWResp : 79|1@0+ (1,0) [0|1] ""  HUT
 SG_ LKAResp : 78|1@0+ (1,0) [0|1] ""  HUT
 SG_ LCKResp : 77|1@0+ (1,0) [0|1] ""  HUT
 SG_ ELKResp : 76|1@0+ (1,0) [0|1] ""  HUT
 SG_ LDW_LKA_Snvty : 74|2@0+ (1,0) [0|3] ""  HUT
 SG_ IFCHUTInterface : 72|1@0+ (1,0) [0|1] ""  HUT
 SG_ LSSWarnFormResp : 85|2@0+ (1,0) [0|3] ""  HUT
 SG_ LSSResp : 83|1@0+ (1,0) [0|1] ""  HUT
 SG_ IntelligentEvaResp : 82|1@0+ (1,0) [0|1] ""  HUT
 SG_ ESS_Pedresp : 87|1@0+ (1,0) [0|1] ""  HUT
 SG_ ESS_Vehresp : 86|1@0+ (1,0) [0|1] ""  HUT
 SG_ RollingCounter_IFC3 : 123|4@0+ (1,0) [0|15] ""  HUT
 SG_ Checksum_IFC4 : 135|8@0+ (1,0) [0|255] ""  HUT
 SG_ IFCCalibrationSts : 154|2@0+ (1,0) [0|3] ""  HUT
 SG_ CameraBlockageSts : 152|1@0+ (1,0) [0|1] ""  HUT
 SG_ LDW_LKAWarn : 143|2@0+ (1,0) [0|3] ""  HUT
 SG_ LSSIntervention : 141|3@0+ (1,0) [0|7] ""  HUT
 SG_ LSSFuncSts : 138|3@0+ (1,0) [0|7] ""  HUT
 SG_ ELKMainState : 151|3@0+ (1,0) [0|7] ""  HUT
 SG_ LaneAvailability : 148|2@0+ (1,0) [0|3] ""  HUT
 SG_ TJA_FollowSts : 146|2@0+ (1,0) [0|3] ""  HUT
 SG_ LSSErrSts : 144|3@0+ (1,0) [0|7] ""  HUT
 SG_ IFC_Handsoffwarn : 157|3@0+ (1,0) [0|7] ""  HUT
 SG_ RollingCounter_IFC4 : 187|4@0+ (1,0) [0|15] ""  HUT
 SG_ Checksum_IFC5 : 199|8@0+ (1,0) [0|255] ""  HUT
 SG_ IFC_LaneCurve : 207|12@0+ (1.5E-005,-0.030705) [-0.030705|0.030705] ""  HUT
 SG_ IFC_LeLaneTyp : 211|3@0+ (1,0) [0|7] ""  HUT
 SG_ IFC_RiLaneTyp : 208|3@0+ (1,0) [0|7] ""  HUT
 SG_ IFC_NextLeLaneTyp : 221|3@0+ (1,0) [0|7] ""  HUT
 SG_ IFC_NextRiLaneTyp : 218|3@0+ (1,0) [0|7] ""  HUT
 SG_ IFC_LeLane_dy : 231|12@0+ (0.00390625,-8) [-8|7.9921875] ""  HUT
 SG_ IFC_RiLane_dy : 235|12@0+ (0.00390625,-8) [-8|7.9921875] ""  HUT
 SG_ RollingCounter_IFC5 : 251|4@0+ (1,0) [0|15] ""  HUT
 SG_ Checksum_IFC6 : 263|8@0+ (1,0) [0|255] ""  HUT
 SG_ IFC_NextLeLane_dy : 271|12@0+ (0.00390625,-8) [-8|7.9921875] ""  HUT
 SG_ IFC_NextRiLane_dy : 275|12@0+ (0.00390625,-8) [-8|7.9921875] ""  HUT
 SG_ RollingCounter_IFC6 : 315|4@0+ (1,0) [0|15] ""  HUT
 SG_ FreshnessValue_IFC_FD2 : 455|16@0+ (1,0) [0|65535] ""  HUT
 SG_ MAC_Check_IFC_FD2 : 471|48@0+ (1,0) [0|281474976710655] ""  HUT

BO_ 580 CSA3: 8 GW
 SG_ MenuReturnSwtSts : 49|2@0+ (1,0) [0|3] ""  HUT
 SG_ HomeSwtSts : 51|2@0+ (1,0) [0|3] ""  HUT
 SG_ MuteSwtSts : 53|2@0+ (1,0) [0|3] ""  HUT
 SG_ CustomSwtSts : 55|2@0+ (1,0) [0|3] ""  HUT
 SG_ SteerWheelHeatdSts : 40|1@0+ (1,0) [0|1] ""  HUT
 SG_ PageUpSwtSts : 15|2@0+ (1,0) [0|3] ""  HUT
 SG_ PageDwnSwtSts : 13|2@0+ (1,0) [0|3] ""  HUT
 SG_ PageLSwtSts : 11|2@0+ (1,0) [0|3] ""  HUT
 SG_ PageRSwtSts : 9|2@0+ (1,0) [0|3] ""  HUT
 SG_ SeekUpSwtSts : 63|2@0+ (1,0) [0|3] ""  HUT
 SG_ SeekDwnSwtSts : 61|2@0+ (1,0) [0|3] ""  HUT
 SG_ AdjVolUpSwtSts : 23|2@0+ (1,0) [0|3] ""  HUT
 SG_ AdjVolDwnSwtSts : 21|2@0+ (1,0) [0|3] ""  HUT
 SG_ VRSwtSts : 19|2@0+ (1,0) [0|3] ""  HUT
 SG_ PhoneSwtSts : 29|2@0+ (1,0) [0|3] ""  HUT
 SG_ SoundSourceModSwtSts : 17|2@0+ (1,0) [0|3] ""  HUT
 SG_ EnterSwtSts : 31|2@0+ (1,0) [0|3] ""  HUT
 SG_ EnterSwtSts_Mmed : 27|2@0+ (1,0) [0|3] ""  HUT
 SG_ CustomSwtSts_Mmed : 39|2@0+ (1,0) [0|3] ""  HUT

BO_ 581 ABM2: 8 GW
 SG_ VehLgtAccel : 15|16@0+ (0.00098,-21.592) [-21.592|21.592] "m/s^2"  HUT

BO_ 582 ABS2: 8 GW
 SG_ RLWheelSpdVld : 13|1@0+ (1,0) [0|1] ""  HUT
 SG_ RLWheelSpd : 12|13@0+ (0.05625,0) [0|299.98125] "km/h"  HUT
 SG_ RRWheelSpdVld : 29|1@0+ (1,0) [0|1] ""  HUT
 SG_ RRWheelSpd : 28|13@0+ (0.05625,0) [0|299.98125] "km/h"  HUT

BO_ 584 HCU_PT7: 8 GW
 SG_ HCU_HybSysErr_1 : 15|1@0+ (1,0) [0|1] ""  HUT
 SG_ HCU_HybSysErr_2 : 14|1@0+ (1,0) [0|1] ""  HUT
 SG_ HCU_HybSysErr_3 : 13|1@0+ (1,0) [0|1] ""  HUT
 SG_ HCU_HybSysErr_4 : 12|1@0+ (1,0) [0|1] ""  HUT
 SG_ HCU_HybSysErr_5 : 11|1@0+ (1,0) [0|1] ""  HUT
 SG_ HCU_HybSysErr_6 : 10|1@0+ (1,0) [0|1] ""  HUT
 SG_ HCU_HybSysErr_7 : 9|1@0+ (1,0) [0|1] ""  HUT
 SG_ HCU_12VSysErrLmpSts : 8|1@0+ (1,0) [0|1] ""  HUT
 SG_ HCU_HybSysErrLmpSts : 27|2@0+ (1,0) [0|3] ""  HUT
 SG_ HCU_PowerRedWarnLmpCmd : 25|1@0+ (1,0) [0|1] ""  HUT
 SG_ HCU_12VSysErr_1 : 24|1@0+ (1,0) [0|1] ""  HUT
 SG_ HCU_12VSysErr_2 : 39|1@0+ (1,0) [0|1] ""  HUT
 SG_ HCU_RdyLmpSts : 37|1@0+ (1,0) [0|1] ""  HUT
 SG_ HCU_ModSwtFail : 63|4@0+ (1,0) [0|15] ""  HUT
 SG_ HCU_EnrgFlowInd : 55|5@0+ (1,0) [0|31] ""  HUT
 SG_ HCU_OPDSts : 43|3@0+ (1,0) [0|7] ""  HUT
 SG_ HCU_OPDLmpSts : 36|1@0+ (1,0) [0|1] ""  HUT

BO_ 589 DMS_FD1: 64 DMS
 SG_ DrowsnsLvl : 13|3@0+ (1,0) [0|7] ""  HUT
 SG_ DrowsnsLvlQlty : 10|7@0+ (1,0) [0|100] "%"  HUT
 SG_ DMSProc : 19|3@0+ (1,0) [0|7] ""  HUT
 SG_ DMSProcResult : 16|4@0+ (1,0) [0|15] ""  HUT
 SG_ DMSProcSts : 28|4@0+ (1,0) [0|15] ""  HUT
 SG_ DMSIdnResult : 24|4@0+ (1,0) [0|15] ""  HUT
 SG_ GenderSts : 36|2@0+ (1,0) [0|3] ""  HUT
 SG_ ExprsnSts : 34|3@0+ (1,0) [0|7] ""  HUT
 SG_ GenderStsQlty : 47|7@0+ (1,0) [0|100] "%"  HUT
 SG_ ExprsnStsQlty : 55|7@0+ (1,0) [0|100] "%"  HUT
 SG_ DistrctnLvl_ACC : 95|3@0+ (1,0) [0|7] ""  GW
 SG_ DistrctnLvlQlty_ACC : 79|7@0+ (1,0) [0|100] "%"  GW
 SG_ DrowsnsLvl_ACC : 92|3@0+ (1,0) [0|7] ""  GW
 SG_ DrowsnsLvlQlty_ACC : 87|7@0+ (1,0) [0|100] "%"  GW
 SG_ DistrctnLvl : 103|3@0+ (1,0) [0|7] ""  HUT
 SG_ DistrctnLvlQlty : 111|7@0+ (1,0) [0|100] "%"  HUT
 SG_ HeadPosnX : 143|11@0+ (1,-500) [-500|1000] "mm"  GW
 SG_ HeadPosnY : 148|11@0+ (1,-500) [-500|500] "mm"  GW
 SG_ HeadPosnZ : 153|11@0+ (1,-500) [-500|500] "mm"  GW
 SG_ HeadPosQlty : 174|7@0+ (1,0) [0|100] "%"  GW
 SG_ GazePosnX : 207|11@0+ (1,-500) [-500|1000] "mm"  GW
 SG_ GazePosnY : 212|11@0+ (1,-500) [-500|500] "mm"  GW
 SG_ GazePosnZ : 217|11@0+ (1,-500) [-500|500] "mm"  GW
 SG_ DMSSts : 303|3@0+ (1,0) [0|7] ""  GW
 SG_ HeadDetn : 288|1@0+ (1,0) [0|1] ""  GW
 SG_ HeadYawAng : 271|8@0+ (1,-75) [-75|75] "degree"  GW
 SG_ HeadPitchAng : 279|8@0+ (1,-25) [-25|45] "degree"  GW
 SG_ HeadRollAng : 287|8@0+ (1,-45) [-45|45] "degree"  GW
 SG_ HeadRotAngQlty : 295|7@0+ (1,0) [0|100] "%"  GW
 SG_ LEyeOpenSts : 375|2@0+ (1,0) [0|3] ""  GW
 SG_ LEyeOpenStsQlty : 351|7@0+ (1,0) [0|100] "%"  GW
 SG_ REyeOpenSts : 373|2@0+ (1,0) [0|3] ""  GW
 SG_ REyeOpenStsQlty : 359|7@0+ (1,0) [0|100] "%"  GW
 SG_ RobustGazeYawAng : 335|8@0+ (1,-90) [-90|90] "degree"  GW
 SG_ RobustGazePitchAng : 343|8@0+ (1,-90) [-90|90] "degree"  GW
 SG_ RobustGazeAngQlty : 367|7@0+ (1,0) [0|100] "%"  GW

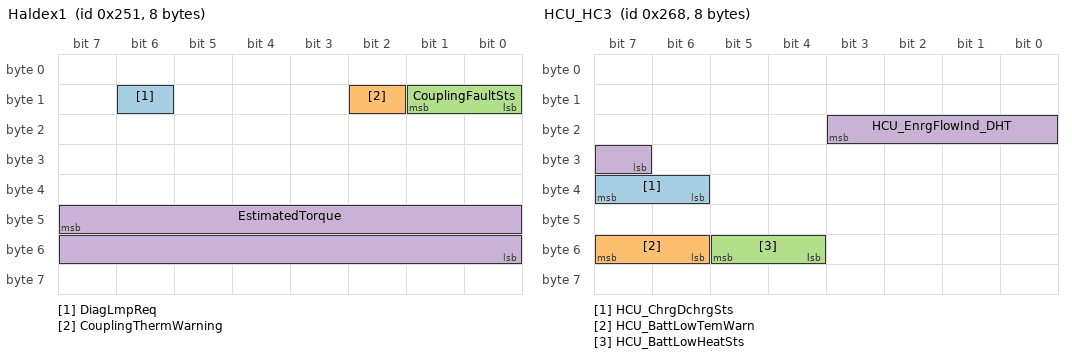
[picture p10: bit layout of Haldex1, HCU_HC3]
BO_ 593 Haldex1: 8 GW
 SG_ DiagLmpReq : 14|1@0+ (1,0) [0|1] ""  HUT
 SG_ CouplingThermWarning : 10|1@0+ (1,0) [0|1] ""  HUT
 SG_ CouplingFaultSts : 9|2@0+ (1,0) [0|3] ""  HUT
 SG_ EstimatedTorque : 47|16@0+ (0.25,0) [0|3000] "Nm"  HUT

BO_ 613 ABS3: 16 GW
 SG_ CheckSum_ABS3_ : 7|8@0+ (1,0) [0|255] ""  HUT
 SG_ ABSFailSts_ : 15|1@0+ (1,0) [0|1] ""  HUT
 SG_ EBDFailSts_ : 14|1@0+ (1,0) [0|1] ""  HUT
 SG_ VehSpdVld_ : 13|1@0+ (1,0) [0|1] ""  HUT,T_Box,DMS,DVR
 SG_ VehSpd_ : 12|13@0+ (0.05625,0) [0|299.98125] "kph"  HUT,T_Box,DMS,DVR
 SG_ VehOdoInfoSts_ : 26|1@0+ (1,0) [0|1] ""  HUT,T_Box
 SG_ VehOdoInfo_ : 25|10@0+ (1,0) [0|999] "m"  HUT
 SG_ ABSActv_ : 27|1@0+ (1,0) [0|1] ""  DVR
 SG_ RollingCounter_ABS3_ : 59|4@0+ (1,0) [0|15] ""  HUT

BO_ 616 HCU_HC3: 8 GW
 SG_ HCU_ChrgDchrgSts : 39|2@0+ (1,0) [0|3] ""  T_Box
 SG_ HCU_BattLowTemWarn : 55|2@0+ (1,0) [0|2] ""  HUT
 SG_ HCU_BattLowHeatSts : 53|2@0+ (1,0) [0|2] ""  HUT
 SG_ HCU_EnrgFlowInd_DHT : 19|5@0+ (1,0) [0|31] ""  HUT

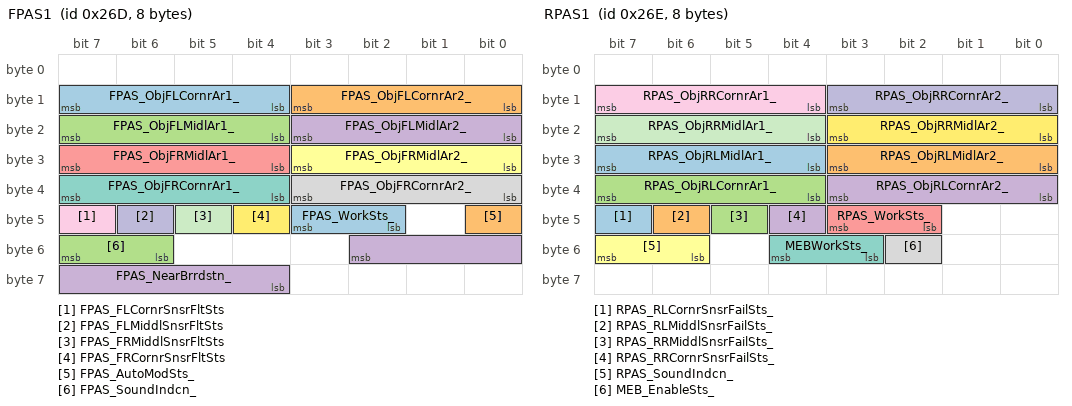
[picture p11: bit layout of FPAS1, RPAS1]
BO_ 621 FPAS1: 8 GW
 SG_ FPAS_ObjFLCornrAr1_ : 15|4@0+ (1,0) [0|15] ""  HUT
 SG_ FPAS_ObjFLCornrAr2_ : 11|4@0+ (1,0) [0|15] ""  HUT
 SG_ FPAS_ObjFLMidlAr1_ : 23|4@0+ (1,0) [0|15] ""  HUT
 SG_ FPAS_ObjFLMidlAr2_ : 19|4@0+ (1,0) [0|15] ""  HUT
 SG_ FPAS_ObjFRMidlAr1_ : 31|4@0+ (1,0) [0|15] ""  HUT
 SG_ FPAS_ObjFRMidlAr2_ : 27|4@0+ (1,0) [0|15] ""  HUT
 SG_ FPAS_ObjFRCornrAr1_ : 39|4@0+ (1,0) [0|15] ""  HUT
 SG_ FPAS_ObjFRCornrAr2_ : 35|4@0+ (1,0) [0|15] ""  HUT
 SG_ FPAS_FLCornrSnsrFltSts : 47|1@0+ (1,0) [0|1] ""  HUT
 SG_ FPAS_FLMiddlSnsrFltSts : 46|1@0+ (1,0) [0|1] ""  HUT
 SG_ FPAS_FRMiddlSnsrFltSts : 45|1@0+ (1,0) [0|1] ""  HUT
 SG_ FPAS_FRCornrSnsrFltSts : 44|1@0+ (1,0) [0|1] ""  HUT
 SG_ FPAS_WorkSts_ : 43|2@0+ (1,0) [0|3] ""  HUT
 SG_ FPAS_AutoModSts_ : 40|1@0+ (1,0) [0|1] ""  HUT
 SG_ FPAS_SoundIndcn_ : 55|2@0+ (1,0) [0|3] ""  HUT
 SG_ FPAS_NearBrrdstn_ : 50|7@0+ (1,0) [0|100] ""  HUT

BO_ 622 RPAS1: 8 GW
 SG_ RPAS_RLCornrSnsrFailSts_ : 47|1@0+ (1,0) [0|1] ""  HUT
 SG_ RPAS_RLMiddlSnsrFailSts_ : 46|1@0+ (1,0) [0|1] ""  HUT
 SG_ RPAS_RRMiddlSnsrFailSts_ : 45|1@0+ (1,0) [0|1] ""  HUT
 SG_ RPAS_RRCornrSnsrFailSts_ : 44|1@0+ (1,0) [0|1] ""  HUT
 SG_ RPAS_WorkSts_ : 43|2@0+ (1,0) [0|3] ""  HUT
 SG_ RPAS_SoundIndcn_ : 55|2@0+ (1,0) [0|3] ""  HUT
 SG_ MEBWorkSts_ : 52|2@0+ (1,0) [0|3] ""  HUT
 SG_ MEB_EnableSts_ : 50|1@0+ (1,0) [0|1] ""  HUT
 SG_ RPAS_ObjRRCornrAr1_ : 15|4@0+ (1,0) [0|15] ""  HUT
 SG_ RPAS_ObjRRCornrAr2_ : 11|4@0+ (1,0) [0|15] ""  HUT
 SG_ RPAS_ObjRRMidlAr1_ : 23|4@0+ (1,0) [0|15] ""  HUT
 SG_ RPAS_ObjRRMidlAr2_ : 19|4@0+ (1,0) [0|15] ""  HUT
 SG_ RPAS_ObjRLMidlAr1_ : 31|4@0+ (1,0) [0|15] ""  HUT
 SG_ RPAS_ObjRLMidlAr2_ : 27|4@0+ (1,0) [0|15] ""  HUT
 SG_ RPAS_ObjRLCornrAr1_ : 39|4@0+ (1,0) [0|15] ""  HUT
 SG_ RPAS_ObjRLCornrAr2_ : 35|4@0+ (1,0) [0|15] ""  HUT

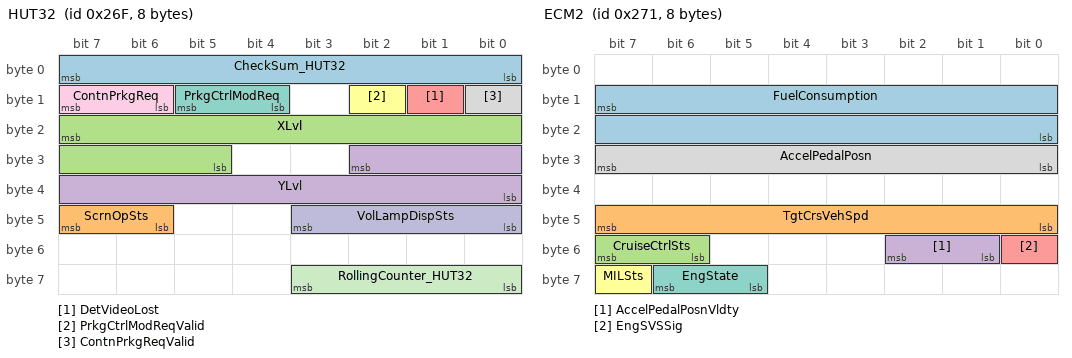
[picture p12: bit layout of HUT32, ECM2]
BO_ 623 HUT32: 8 HUT
 SG_ CheckSum_HUT32 : 7|8@0+ (1,0) [0|255] ""  GW
 SG_ ScrnOpSts : 47|2@0+ (1,0) [0|3] ""  GW
 SG_ XLvl : 23|11@0+ (1,0) [0|2047] ""  GW
 SG_ YLvl : 26|11@0+ (1,0) [0|2047] ""  GW
 SG_ DetVideoLost : 9|1@0+ (1,0) [0|1] ""  GW
 SG_ PrkgCtrlModReqValid : 10|1@0+ (1,0) [0|1] ""  GW
 SG_ PrkgCtrlModReq : 13|2@0+ (1,0) [0|3] ""  GW
 SG_ ContnPrkgReqValid : 8|1@0+ (1,0) [0|1] ""  GW
 SG_ ContnPrkgReq : 15|2@0+ (1,0) [0|3] ""  GW
 SG_ VolLampDispSts : 43|4@0+ (1,0) [0|15] ""  GW
 SG_ RollingCounter_HUT32 : 59|4@0+ (1,0) [0|15] ""  GW

BO_ 625 ECM2: 8 GW
 SG_ FuelConsumption : 15|16@0+ (2,0) [0|131070] "μl"  HUT
 SG_ TgtCrsVehSpd : 47|8@0+ (1,0) [0|255] "kph/mph"  HUT
 SG_ CruiseCtrlSts : 55|2@0+ (1,0) [0|2] ""  HUT
 SG_ AccelPedalPosnVldty : 50|2@0+ (1,0) [0|2] ""  HUT
 SG_ EngSVSSig : 48|1@0+ (1,0) [0|1] ""  HUT
 SG_ MILSts : 63|1@0+ (1,0) [0|1] ""  HUT
 SG_ EngState : 62|2@0+ (1,0) [0|3] ""  HUT,T_Box
 SG_ AccelPedalPosn : 31|8@0+ (0.3937,0) [0|100.3935] "%"  HUT

BO_ 627 Trailer1: 8 GW
 SG_ TrailerSts : 7|1@0+ (1,0) [0|1] ""  HUT

BO_ 628 HAP_FD2: 64 GW
 SG_ AutoAVMSwtSet_Sts : 83|1@0+ (1,0) [0|1] ""  HUT
 SG_ AVM_CurrSts : 79|2@0+ (1,0) [0|3] ""  HUT
 SG_ GuidOvlSts : 95|2@0+ (1,0) [0|3] ""  HUT
 SG_ FrntCamInpFailSts : 108|1@0+ (1,0) [0|1] ""  HUT
 SG_ RearCamInpFailSts : 109|1@0+ (1,0) [0|1] ""  HUT
 SG_ LeCamInpFailSts : 110|1@0+ (1,0) [0|1] ""  HUT
 SG_ RiCamInpFailSts : 111|1@0+ (1,0) [0|1] ""  HUT
 SG_ EolNotCmpltd : 107|1@0+ (1,0) [0|1] ""  HUT
 SG_ OvlOpFailSts : 105|1@0+ (1,0) [0|1] ""  HUT
 SG_ LaneCalSts : 101|2@0+ (1,0) [0|3] ""  HUT
 SG_ RadarDispSts : 93|2@0+ (1,0) [0|3] ""  HUT
 SG_ LaneCalFltSts : 99|3@0+ (1,0) [0|7] ""  HUT
 SG_ AutoViewChgFuncSts : 84|1@0+ (1,0) [0|1] ""  HUT
 SG_ CarMdlTrsprcySts : 103|2@0+ (1,0) [0|3] ""  HUT
 SG_ CarMdlDispSts : 85|1@0+ (1,0) [0|1] ""  HUT
 SG_ CurrCalResultSts : 96|1@0+ (1,0) [0|1] ""  HUT
 SG_ MdlColrSts : 91|4@0+ (1,0) [0|15] ""  HUT
 SG_ SigViewIndcn : 77|6@0+ (1,0) [0|63] ""  HUT
 SG_ HAP_DispCmd : 127|1@0+ (1,0) [0|1] ""  HUT
 SG_ AVM_3DAngSts : 104|9@0+ (1,0) [0|360] "deg"  HUT
 SG_ MOD_WorkSts : 87|1@0+ (1,0) [0|1] ""  HUT
 SG_ HAP_Hmi_Index : 82|3@0+ (1,0) [0|7] ""  HUT
 SG_ DVRWorkSts : 126|2@0+ (1,0) [0|3] ""  DVR
 SG_ MOD_AlarmSts : 86|1@0+ (1,0) [0|1] ""  HUT

BO_ 639 HUT_IP2: 16 HUT
 SG_ CheckSum_IP2 : 7|8@0+ (1,0) [0|255] ""  GW
 SG_ IP_DrvSeatBeltWarnLmpFailSts : 51|2@0+ (1,0) [0|3] ""  GW
 SG_ IP_PassSeatBeltWarnLmpFailSts : 49|2@0+ (1,0) [0|3] ""  GW
 SG_ IP_VehTotDistance : 15|24@0+ (0.1,0) [0|999999.9] "Km"  GW,T_Box,DMS,DVR
 SG_ IP_FuelLvlInfo : 39|8@0+ (1,0) [0|200] "L"  GW,T_Box
 SG_ IP_FuelLvlLowLmpSts : 45|2@0+ (1,0) [0|3] ""  T_Box
 SG_ IP_BattChrgLmpSts : 43|2@0+ (1,0) [0|3] "" Vector__XXX
 SG_ IP_EngOilPressLowLmpSts : 41|2@0+ (1,0) [0|3] "" Vector__XXX
 SG_ IP_ABMWarnLmpFailrSts : 55|2@0+ (1,0) [0|3] ""  GW
 SG_ IP_Err : 52|1@0+ (1,0) [0|1] ""  GW
 SG_ IP_ACCErr : 47|1@0+ (1,0) [0|1] ""  GW
 SG_ IP_VehTotDistanceValid : 46|1@0+ (1,0) [0|1] ""  GW,T_Box,DMS,DVR
 SG_ IP_VehSpdUnit : 53|1@0+ (1,0) [0|1] ""  GW
 SG_ IP_VINcompr : 63|1@0+ (1,0) [0|1] ""  GW
 SG_ RollingCounter_IP2 : 59|4@0+ (1,0) [0|15] ""  GW
 SG_ FreshnessValue_HUT_IP2 : 71|16@0+ (1,0) [0|65535] ""  GW
 SG_ MAC_Check_HUT_IP2 : 87|48@0+ (1,0) [0|281474976710655] ""  GW

BO_ 645 BMS8: 8 GW
 SG_ BMS_BattHeatRunaway : 61|2@0+ (1,0) [0|3] ""  HUT,T_Box

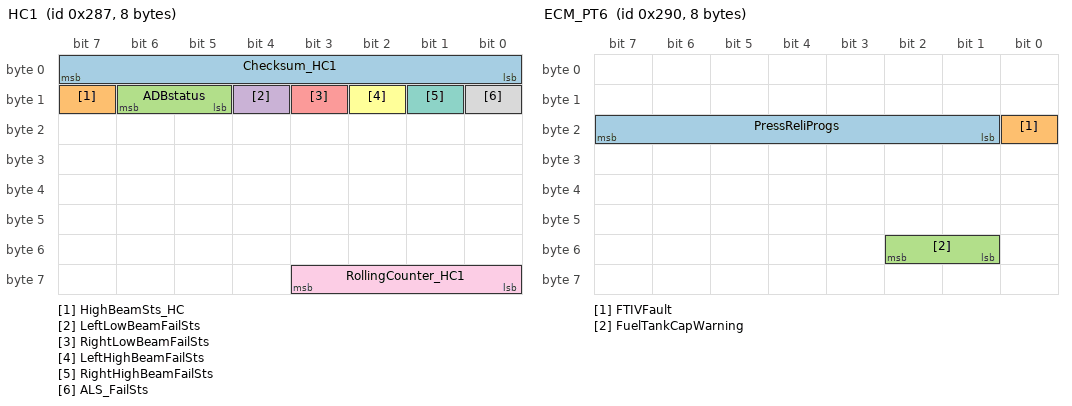
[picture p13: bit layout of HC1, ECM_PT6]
BO_ 647 HC1: 8 GW
 SG_ Checksum_HC1 : 7|8@0+ (1,0) [0|255] ""  HUT
 SG_ HighBeamSts_HC : 15|1@0+ (1,0) [0|1] ""  HUT,T_Box
 SG_ ADBstatus : 14|2@0+ (1,0) [0|3] ""  HUT
 SG_ LeftLowBeamFailSts : 12|1@0+ (1,0) [0|1] ""  HUT
 SG_ RightLowBeamFailSts : 11|1@0+ (1,0) [0|1] ""  HUT
 SG_ LeftHighBeamFailSts : 10|1@0+ (1,0) [0|1] ""  HUT
 SG_ RightHighBeamFailSts : 9|1@0+ (1,0) [0|1] ""  HUT
 SG_ ALS_FailSts : 8|1@0+ (1,0) [0|1] ""  HUT
 SG_ RollingCounter_HC1 : 59|4@0+ (1,0) [0|15] ""  HUT

BO_ 652 BCM6: 8 GW
 SG_ VolSwtReq : 16|1@0+ (1,0) [0|1] ""  HUT
 SG_ VolSwtErrSts : 46|1@0+ (1,0) [0|1] ""  HUT

BO_ 656 ECM_PT6: 8 GW
 SG_ PressReliProgs : 23|7@0+ (1,0) [0|100] "%"  HUT
 SG_ FTIVFault : 16|1@0+ (1,0) [0|1] ""  HUT
 SG_ FuelTankCapWarning : 50|2@0+ (1,0) [0|3] ""  HUT

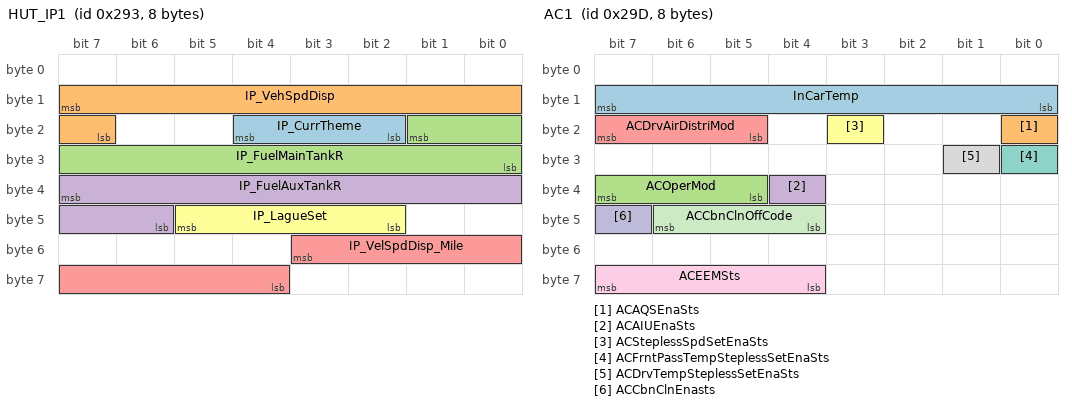
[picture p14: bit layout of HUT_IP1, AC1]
BO_ 659 HUT_IP1: 8 HUT
 SG_ IP_CurrTheme : 20|3@0+ (1,0) [0|7] ""  T_Box
 SG_ IP_VehSpdDisp : 15|9@0+ (0.5,0) [0|255] "km/h" Vector__XXX
 SG_ IP_FuelMainTankR : 17|10@0+ (1,0) [10|1000] "Ohm"  GW
 SG_ IP_FuelAuxTankR : 39|10@0+ (1,0) [10|1000] "Ohm"  GW
 SG_ IP_VelSpdDisp_Mile : 51|8@0+ (1,0) [0|255] "Mile per hour" Vector__XXX
 SG_ IP_LagueSet : 45|4@0+ (1,0) [0|15] "" Vector__XXX

BO_ 661 PEPS2: 8 GW
 SG_ SysPowerMod : 15|2@0+ (1,0) [0|3] ""  HUT,T_Box,DMS,DVR
 SG_ SysPowerModVld : 13|1@0+ (1,0) [0|1] ""  HUT,T_Box,DMS,DVR

BO_ 664 HAP_FD3: 64 GW
 SG_ RPAS_NearBrrdstn_ : 15|8@0+ (1,0) [0|150] ""  HUT,DVR
 SG_ APS_ObjRiSideAr1 : 79|4@0+ (1,0) [0|15] ""  HUT
 SG_ APS_ObjRiSideAr2 : 75|4@0+ (1,0) [0|15] ""  HUT
 SG_ APS_ObjRiSideAr3 : 87|4@0+ (1,0) [0|15] ""  HUT
 SG_ APS_ObjRiSideAr4 : 83|4@0+ (1,0) [0|15] ""  HUT
 SG_ APS_ObjRiSideAr5 : 95|4@0+ (1,0) [0|15] ""  HUT
 SG_ APS_ObjLeSideAr1 : 91|4@0+ (1,0) [0|15] ""  HUT
 SG_ APS_ObjLeSideAr2 : 103|4@0+ (1,0) [0|15] ""  HUT
 SG_ APS_ObjLeSideAr3 : 99|4@0+ (1,0) [0|15] ""  HUT
 SG_ APS_ObjLeSideAr4 : 111|4@0+ (1,0) [0|15] ""  HUT
 SG_ APS_ObjLeSideAr5 : 107|4@0+ (1,0) [0|15] ""  HUT
 SG_ APS_FRSideSnsrFailSts : 119|1@0+ (1,0) [0|1] ""  HUT
 SG_ APS_FLSideSnsrFailSts : 118|1@0+ (1,0) [0|1] ""  HUT
 SG_ APS_RRSideSnsrFailSts : 117|1@0+ (1,0) [0|1] ""  HUT
 SG_ APS_RLSideSnsrFailSts : 116|1@0+ (1,0) [0|1] ""  HUT
 SG_ SDW_SoundIndcn : 115|2@0+ (1,0) [0|3] ""  HUT
 SG_ SDWActiveSts : 112|1@0+ (1,0) [0|1] ""  HUT
 SG_ RPAS_ObjRRCornrAr1 : 143|4@0+ (1,0) [0|15] ""  HUT
 SG_ RPAS_ObjRRCornrAr2 : 139|4@0+ (1,0) [0|15] ""  HUT
 SG_ RPAS_ObjRRMidlAr1 : 151|4@0+ (1,0) [0|15] ""  HUT
 SG_ RPAS_ObjRRMidlAr2 : 147|4@0+ (1,0) [0|15] ""  HUT
 SG_ RPAS_ObjRLMidlAr1 : 159|4@0+ (1,0) [0|15] ""  HUT
 SG_ RPAS_ObjRLMidlAr2 : 155|4@0+ (1,0) [0|15] ""  HUT
 SG_ RPAS_ObjRLCornrAr1 : 167|4@0+ (1,0) [0|15] ""  HUT
 SG_ RPAS_ObjRLCornrAr2 : 163|4@0+ (1,0) [0|15] ""  HUT
 SG_ RPAS_RLCornrSnsrFailSts : 175|1@0+ (1,0) [0|1] ""  HUT
 SG_ RPAS_RLMiddlSnsrFailSts : 174|1@0+ (1,0) [0|1] ""  HUT
 SG_ RPAS_RRMiddlSnsrFailSts : 173|1@0+ (1,0) [0|1] ""  HUT
 SG_ RPAS_RRCornrSnsrFailSts : 172|1@0+ (1,0) [0|1] ""  HUT
 SG_ RPAS_WorkSts : 171|2@0+ (1,0) [0|3] ""  HUT
 SG_ RPAS_SoundIndcn : 183|2@0+ (1,0) [0|3] ""  HUT
 SG_ MEBWorkSts : 180|2@0+ (1,0) [0|3] ""  HUT
 SG_ MEB_EnableSts : 178|1@0+ (1,0) [0|1] ""  HUT
 SG_ FPAS_ObjFLCornrAr1 : 207|4@0+ (1,0) [0|15] ""  HUT
 SG_ FPAS_ObjFLCornrAr2 : 203|4@0+ (1,0) [0|15] ""  HUT
 SG_ FPAS_ObjFLMidlAr1 : 215|4@0+ (1,0) [0|15] ""  HUT
 SG_ FPAS_ObjFLMidlAr2 : 211|4@0+ (1,0) [0|15] ""  HUT
 SG_ FPAS_ObjFRMidlAr1 : 223|4@0+ (1,0) [0|15] ""  HUT
 SG_ FPAS_ObjFRMidlAr2 : 219|4@0+ (1,0) [0|15] ""  HUT
 SG_ FPAS_ObjFRCornrAr1 : 231|4@0+ (1,0) [0|15] ""  HUT
 SG_ FPAS_ObjFRCornrAr2 : 227|4@0+ (1,0) [0|15] ""  HUT
 SG_ FPAS_FLCornrSnsrFailSts : 239|1@0+ (1,0) [0|1] ""  HUT
 SG_ FPAS_FLMiddlSnsrFailSts : 238|1@0+ (1,0) [0|1] ""  HUT
 SG_ FPAS_FRMiddlSnsrFailSts : 237|1@0+ (1,0) [0|1] ""  HUT
 SG_ FPAS_FRCornrSnsrFailSts : 236|1@0+ (1,0) [0|1] ""  HUT
 SG_ FPAS_WorkSts : 235|2@0+ (1,0) [0|3] ""  HUT
 SG_ FPAS_AutoModSts : 232|1@0+ (1,0) [0|1] ""  HUT
 SG_ FPAS_SoundIndcn : 247|2@0+ (1,0) [0|3] ""  HUT
 SG_ FPAS_NearBrrdstn : 242|7@0+ (1,0) [0|100] ""  HUT,DVR
 SG_ APA_MenuDispCtrlCmd : 279|4@0+ (1,0) [0|15] ""  HUT
 SG_ APA_FuncSts : 271|2@0+ (1,0) [0|3] ""  HUT
 SG_ P2P_FuncSts : 269|2@0+ (1,0) [0|3] ""  HUT
 SG_ RADS_FuncSts : 267|2@0+ (1,0) [0|3] ""  HUT
 SG_ FADS_FuncSts : 265|2@0+ (1,0) [0|3] ""  HUT
 SG_ HAP_TextIconDispCtrl : 275|2@0+ (1,0) [0|3] ""  HUT

BO_ 669 AC1: 8 GW
 SG_ InCarTemp : 15|8@0+ (0.5,-40) [-40|86.5] "°C"  T_Box
 SG_ ACAQSEnaSts : 16|1@0+ (1,0) [0|1] ""  HUT
 SG_ ACOperMod : 39|3@0+ (1,0) [0|7] ""  HUT
 SG_ ACAIUEnaSts : 36|1@0+ (1,0) [0|1] ""  HUT,T_Box
 SG_ ACDrvAirDistriMod : 23|3@0+ (1,0) [0|7] ""  HUT
 SG_ ACSteplessSpdSetEnaSts : 19|1@0+ (1,0) [0|1] ""  HUT
 SG_ ACFrntPassTempSteplessSetEnaSts : 24|1@0+ (1,0) [0|1] ""  HUT
 SG_ ACDrvTempSteplessSetEnaSts : 25|1@0+ (1,0) [0|1] ""  HUT
 SG_ ACEEMSts : 63|4@0+ (1,0) [0|15] ""  HUT
 SG_ ACCbnClnEnasts : 47|1@0+ (1,0) [0|1] ""  T_Box
 SG_ ACCbnClnOffCode : 46|3@0+ (1,0) [0|7] ""  T_Box

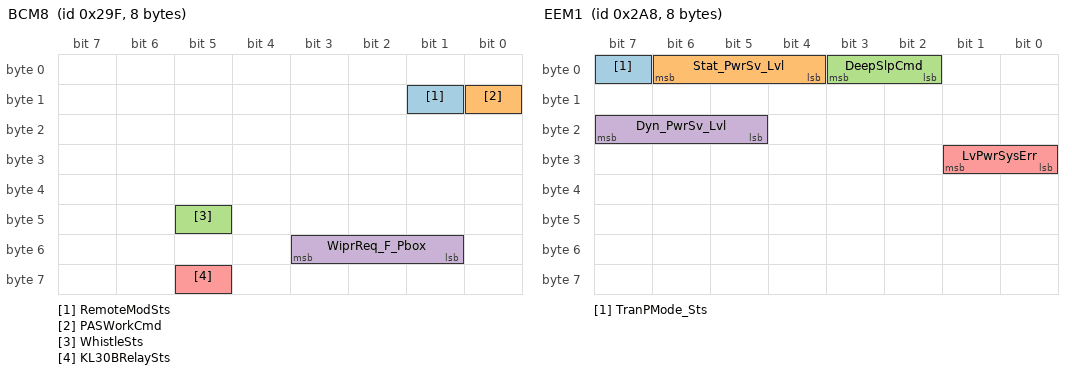
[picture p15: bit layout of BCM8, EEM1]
BO_ 671 BCM8: 8 GW
 SG_ RemoteModSts : 9|1@0+ (1,0) [0|1] "1"  HUT,T_Box
 SG_ PASWorkCmd : 8|1@0+ (1,0) [0|1] ""  HUT
 SG_ WhistleSts : 45|1@0+ (1,0) [0|1] ""  T_Box
 SG_ WiprReq_F_Pbox : 51|3@0+ (1,0) [0|7] ""  HUT
 SG_ KL30BRelaySts : 61|1@0+ (1,0) [0|1] ""  HUT

BO_ 680 EEM1: 8 GW
 SG_ TranPMode_Sts : 7|1@0+ (1,0) [0|1] ""  HUT,T_Box,DMS,DVR
 SG_ Stat_PwrSv_Lvl : 6|3@0+ (1,0) [0|7] ""  HUT
 SG_ DeepSlpCmd : 3|2@0+ (1,0) [0|3] ""  T_Box
 SG_ Dyn_PwrSv_Lvl : 23|3@0+ (1,0) [0|7] ""  HUT
 SG_ LvPwrSysErr : 25|2@0+ (1,0) [0|3] ""  HUT

BO_ 683 ACC_FD2: 64 GW
 SG_ Checksum_ACC3 : 71|8@0+ (1,0) [0|255] ""  HUT
 SG_ ISL_Resp : 79|1@0+ (1,0) [0|1] ""  HUT
 SG_ ICA_HandsOffResp : 78|1@0+ (1,0) [0|1] ""  HUT
 SG_ RollingCounter_ACC3 : 123|4@0+ (1,0) [0|15] ""  HUT
 SG_ Checksum_ACC4 : 135|8@0+ (1,0) [0|255] ""  HUT
 SG_ ACC_ObjDetecte : 143|1@0+ (1,0) [0|1] ""  HUT
 SG_ ACC_TakeOverReq : 142|1@0+ (1,0) [0|1] ""  HUT
 SG_ ACC_InterSysInfoDisp : 141|5@0+ (1,0) [0|31] ""  HUT
 SG_ ACC_ModDisp : 151|5@0+ (1,0) [0|31] ""  HUT
 SG_ ACC_FctSts : 146|2@0+ (1,0) [0|3] ""  HUT
 SG_ ACC_TgtObjBarDisp : 159|3@0+ (1,0) [0|7] ""  HUT
 SG_ ACC_TimeGapSet : 170|3@0+ (1,0) [0|7] ""  HUT
 SG_ ACC_SpdSetValue : 183|8@0+ (1,0) [0|254] "kph/mph"  HUT
 SG_ TJA_ACC_SelSts : 154|3@0+ (1,0) [0|7] ""  HUT
 SG_ ISL_InterSysInfoDisp : 172|2@0+ (1,0) [0|3] ""  HUT
 SG_ TJA_ICA_ModDisp : 175|3@0+ (1,0) [0|7] ""  HUT
 SG_ TJA_ICA_InterSysInfoDisp : 163|3@0+ (1,0) [0|7] ""  HUT
 SG_ RollingCounter_ACC4 : 187|4@0+ (1,0) [0|15] ""  HUT
 SG_ Checksum_ACC6 : 263|8@0+ (1,0) [0|255] ""  HUT
 SG_ ACC_PotentialTgtDy : 271|8@0+ (0.1,-8) [-8|8] "m"  HUT
 SG_ ACC_PotentialTgtDx : 279|9@0+ (0.5,0) [0|150] "m"  HUT
 SG_ ACC_RlvTgtDetn : 286|2@0+ (1,0) [0|3] ""  HUT
 SG_ ACC_EgoStatus : 284|2@0+ (1,0) [0|3] ""  HUT
 SG_ ACC_RlvTgtDy : 295|8@0+ (0.1,-8) [-8|8] "m"  HUT
 SG_ ACC_RlvTgtDx : 303|9@0+ (0.5,0) [0|150] "m"  HUT
 SG_ ACC_PotentialTgtDetn : 309|2@0+ (1,0) [0|3] ""  HUT
 SG_ ACC_PotentialTgtTyp : 307|3@0+ (1,0) [0|7] ""  HUT
 SG_ ACC_RlvTgtTyp : 282|3@0+ (1,0) [0|7] ""  HUT
 SG_ Request_driveoff : 318|1@0+ (1,0) [0|1] ""  HUT
 SG_ RollingCounter_ACC6 : 315|4@0+ (1,0) [0|15] ""  HUT
 SG_ Checksum_ACC7 : 327|8@0+ (1,0) [0|255] ""  HUT
 SG_ ACC_LeTgtDy : 335|8@0+ (0.1,-8) [-8|8] "m"  HUT
 SG_ ACC_LeTgtDx : 343|9@0+ (0.5,0) [0|150] "m"  HUT
 SG_ ACC_LeTgtTyp : 350|3@0+ (1,0) [0|7] ""  HUT
 SG_ ACC_LeTargrtDection : 347|2@0+ (1,0) [0|3] ""  HUT
 SG_ ACC_RiTargrtDetn : 345|2@0+ (1,0) [0|3] ""  HUT
 SG_ ACC_RiTgtDy : 359|8@0+ (0.1,-8) [-8|8] "m"  HUT
 SG_ ACC_RiTgtDx : 367|9@0+ (0.5,0) [0|150] "m"  HUT
 SG_ ACC_RiTgtTyp : 374|3@0+ (1,0) [0|7] ""  HUT
 SG_ RollingCounter_ACC7 : 379|4@0+ (1,0) [0|15] ""  HUT
 SG_ FreshnessValue_ACC_FD2 : 455|16@0+ (1,0) [0|65535] ""  HUT
 SG_ MAC_Check_ACC_FD2 : 471|48@0+ (1,0) [0|281474976710655] ""  HUT

CM_ SG_ 616 HCU_BattLowTemWarn " ";
BA_DEF_  "Manufacturer" STRING ;
BA_DEF_  "DBName" STRING ;
BA_DEF_  "BusType" STRING ;
BA_DEF_  "GenEnvVarEndingDsp" STRING ;
BA_DEF_  "GenEnvVarEndingSnd" STRING ;
BA_DEF_  "GenEnvVarPrefix" STRING ;
BA_DEF_  "GenNWMApBusSleep" STRING ;
BA_DEF_  "GenNWMApCanNormal" STRING ;
BA_DEF_  "GenNWMApCanOff" STRING ;
BA_DEF_  "GenNWMApCanOn" STRING ;
BA_DEF_  "GenNWMApCanSleep" STRING ;
BA_DEF_  "GenNWMApCanWakeUp" STRING ;
BA_DEF_  "GenNWMGotoMode_Awake" STRING ;
BA_DEF_  "GenNWMGotoMode_BusSleep" STRING ;
BA_DEF_  "GenNWMTalkNM" STRING ;
BA_DEF_  "NmBaseAddress" HEX 1152 1279;
BA_DEF_ BU_  "NodeLayerModules" STRING ;
BA_DEF_ BU_  "NmCAN" INT 0 2;
BA_DEF_ BU_  "ILUsed" ENUM  "No","Yes";
BA_DEF_ BO_  "DiagState" ENUM  "No","Yes";
BA_DEF_ BO_  "NmMessage" ENUM  "no","yes";
BA_DEF_ BO_  "GenMsgILSupport" ENUM  "No","Yes";
BA_DEF_ BO_  "GenMsgCycleTime" INT 0 65535;
BA_DEF_ BO_  "GenMsgMinAcceptLength" INT 0 8;
BA_DEF_ BO_  "GenMsgSendType" ENUM  "Cyclic","CyclicAndSpontanX","Event";
BA_DEF_ BO_  "CANFD_BRS" ENUM  "0","1";
BA_DEF_ BO_  "VFrameFormat" ENUM  "StandardCAN","ExtendedCAN","reserved","reserved","reserved","reserved","reserved","reserved","reserved","reserved","reserved","reserved","reserved","reserved","StandardCAN_FD","ExtendedCAN_FD";
BA_DEF_ SG_  "GenSigEnvVarType" ENUM  "undef","int","float";
BA_DEF_ SG_  "GenSigSendType" ENUM  "Cyclic","OnWrite","OnWriteWithRepetition","OnChange","OnChangeWithRepetition","IfActive","IfActiveWithRepetition","NoSigSendType","NotUsed","NotUsed","NotUsed","NotUsed","NotUsed";
BA_DEF_ SG_  "GenSigStartValue" FLOAT 0 1215752192;
BA_DEF_DEF_  "Manufacturer" "GWM";
BA_DEF_DEF_  "DBName" "B30_for_SC_CAN_V3_2";
BA_DEF_DEF_  "BusType" "";
BA_DEF_DEF_  "GenEnvVarEndingDsp" "_d";
BA_DEF_DEF_  "GenEnvVarEndingSnd" "_s";
BA_DEF_DEF_  "GenEnvVarPrefix" "c";
BA_DEF_DEF_  "GenNWMApBusSleep" "apBusSleep()";
BA_DEF_DEF_  "GenNWMApCanNormal" "apCanNormal()";
BA_DEF_DEF_  "GenNWMApCanOff" "apCanOff()";
BA_DEF_DEF_  "GenNWMApCanOn" "apCanOn()";
BA_DEF_DEF_  "GenNWMApCanSleep" "apCanSleep()";
BA_DEF_DEF_  "GenNWMApCanWakeUp" "apCanWakeUp()";
BA_DEF_DEF_  "GenNWMGotoMode_Awake" "GotoMode_Awake()";
BA_DEF_DEF_  "GenNWMGotoMode_BusSleep" "GotoMode_BusSleep()";
BA_DEF_DEF_  "GenNWMTalkNM" "TalkNM()";
BA_DEF_DEF_  "NmBaseAddress" 1152;
BA_DEF_DEF_  "NodeLayerModules" "CANoeILNLVector.dll";
BA_DEF_DEF_  "NmCAN" 1;
BA_DEF_DEF_  "ILUsed" "Yes";
BA_DEF_DEF_  "DiagState" "No";
BA_DEF_DEF_  "NmMessage" "no";
BA_DEF_DEF_  "GenMsgILSupport" "Yes";
BA_DEF_DEF_  "GenMsgCycleTime" 10;
BA_DEF_DEF_  "GenMsgMinAcceptLength" 8;
BA_DEF_DEF_  "GenMsgSendType" "Cyclic";
BA_DEF_DEF_  "CANFD_BRS" "1";
BA_DEF_DEF_  "VFrameFormat" "StandardCAN";
BA_DEF_DEF_  "GenSigEnvVarType" "undef";
BA_DEF_DEF_  "GenSigSendType" "Cyclic";
BA_DEF_DEF_  "GenSigStartValue" 0;
BA_ "BusType" "CANFD";
BA_ "GenMsgSendType" BO_ 51 2;
BA_ "GenMsgCycleTime" BO_ 51 0;
BA_ "VFrameFormat" BO_ 51 14;
BA_ "GenMsgSendType" BO_ 53 2;
BA_ "GenMsgCycleTime" BO_ 53 0;
BA_ "VFrameFormat" BO_ 53 14;
BA_ "GenMsgSendType" BO_ 54 2;
BA_ "GenMsgCycleTime" BO_ 54 0;
BA_ "VFrameFormat" BO_ 54 14;
BA_ "GenMsgSendType" BO_ 70 2;
BA_ "GenMsgCycleTime" BO_ 70 0;
BA_ "VFrameFormat" BO_ 70 14;
BA_ "GenMsgSendType" BO_ 72 2;
BA_ "GenMsgCycleTime" BO_ 72 0;
BA_ "VFrameFormat" BO_ 72 14;
BA_ "GenMsgSendType" BO_ 74 2;
BA_ "GenMsgCycleTime" BO_ 74 0;
BA_ "VFrameFormat" BO_ 74 14;
BA_ "GenMsgSendType" BO_ 86 2;
BA_ "GenMsgCycleTime" BO_ 86 0;
BA_ "VFrameFormat" BO_ 86 14;
BA_ "VFrameFormat" BO_ 96 14;
BA_ "VFrameFormat" BO_ 130 14;
BA_ "VFrameFormat" BO_ 132 14;
BA_ "VFrameFormat" BO_ 134 14;
BA_ "VFrameFormat" BO_ 147 14;
BA_ "VFrameFormat" BO_ 161 14;
BA_ "VFrameFormat" BO_ 166 14;
BA_ "VFrameFormat" BO_ 193 14;
BA_ "VFrameFormat" BO_ 200 14;
BA_ "VFrameFormat" BO_ 216 14;
BA_ "VFrameFormat" BO_ 241 14;
BA_ "GenMsgCycleTime" BO_ 258 20;
BA_ "VFrameFormat" BO_ 258 14;
BA_ "VFrameFormat" BO_ 273 14;
BA_ "GenMsgCycleTime" BO_ 279 20;
BA_ "VFrameFormat" BO_ 279 14;
BA_ "GenMsgCycleTime" BO_ 282 20;
BA_ "VFrameFormat" BO_ 282 14;
BA_ "GenMsgCycleTime" BO_ 288 20;
BA_ "VFrameFormat" BO_ 288 14;
BA_ "GenMsgCycleTime" BO_ 311 20;
BA_ "VFrameFormat" BO_ 311 14;
BA_ "GenMsgCycleTime" BO_ 313 20;
BA_ "VFrameFormat" BO_ 313 14;
BA_ "GenMsgCycleTime" BO_ 325 20;
BA_ "VFrameFormat" BO_ 325 14;
BA_ "GenMsgCycleTime" BO_ 327 20;
BA_ "VFrameFormat" BO_ 327 14;
BA_ "GenMsgCycleTime" BO_ 329 20;
BA_ "VFrameFormat" BO_ 329 14;
BA_ "GenMsgCycleTime" BO_ 338 20;
BA_ "VFrameFormat" BO_ 338 14;
BA_ "GenMsgCycleTime" BO_ 347 20;
BA_ "VFrameFormat" BO_ 347 14;
BA_ "GenMsgCycleTime" BO_ 357 20;
BA_ "VFrameFormat" BO_ 357 14;
BA_ "GenMsgCycleTime" BO_ 360 20;
BA_ "VFrameFormat" BO_ 360 14;
BA_ "GenMsgCycleTime" BO_ 363 20;
BA_ "VFrameFormat" BO_ 363 14;
BA_ "GenMsgCycleTime" BO_ 367 20;
BA_ "VFrameFormat" BO_ 367 14;
BA_ "GenMsgCycleTime" BO_ 368 20;
BA_ "VFrameFormat" BO_ 368 14;
BA_ "GenMsgCycleTime" BO_ 395 20;
BA_ "VFrameFormat" BO_ 395 14;
BA_ "GenMsgCycleTime" BO_ 407 50;
BA_ "VFrameFormat" BO_ 407 14;
BA_ "GenMsgCycleTime" BO_ 411 50;
BA_ "VFrameFormat" BO_ 411 14;
BA_ "GenMsgCycleTime" BO_ 412 50;
BA_ "VFrameFormat" BO_ 412 14;
BA_ "GenMsgCycleTime" BO_ 448 50;
BA_ "VFrameFormat" BO_ 448 14;
BA_ "GenMsgSendType" BO_ 481 2;
BA_ "GenMsgCycleTime" BO_ 481 0;
BA_ "VFrameFormat" BO_ 481 14;
BA_ "GenMsgSendType" BO_ 482 2;
BA_ "GenMsgCycleTime" BO_ 482 0;
BA_ "VFrameFormat" BO_ 482 14;
BA_ "GenMsgSendType" BO_ 483 2;
BA_ "GenMsgCycleTime" BO_ 483 0;
BA_ "VFrameFormat" BO_ 483 14;
BA_ "GenMsgSendType" BO_ 489 2;
BA_ "GenMsgCycleTime" BO_ 489 0;
BA_ "VFrameFormat" BO_ 489 14;
BA_ "GenMsgSendType" BO_ 493 2;
BA_ "GenMsgCycleTime" BO_ 493 0;
BA_ "VFrameFormat" BO_ 493 14;
BA_ "GenMsgSendType" BO_ 494 2;
BA_ "GenMsgCycleTime" BO_ 494 0;
BA_ "VFrameFormat" BO_ 494 14;
BA_ "GenMsgCycleTime" BO_ 513 50;
BA_ "VFrameFormat" BO_ 513 14;
BA_ "GenMsgCycleTime" BO_ 543 50;
BA_ "VFrameFormat" BO_ 543 14;
BA_ "GenMsgCycleTime" BO_ 545 20;
BA_ "VFrameFormat" BO_ 545 14;
BA_ "GenMsgCycleTime" BO_ 551 50;
BA_ "VFrameFormat" BO_ 551 14;
BA_ "GenMsgCycleTime" BO_ 561 20;
BA_ "VFrameFormat" BO_ 561 14;
BA_ "GenMsgCycleTime" BO_ 565 50;
BA_ "VFrameFormat" BO_ 565 14;
BA_ "GenMsgCycleTime" BO_ 568 50;
BA_ "VFrameFormat" BO_ 568 14;
BA_ "GenMsgCycleTime" BO_ 573 50;
BA_ "VFrameFormat" BO_ 573 14;
BA_ "GenMsgCycleTime" BO_ 580 50;
BA_ "VFrameFormat" BO_ 580 14;
BA_ "GenMsgCycleTime" BO_ 581 20;
BA_ "VFrameFormat" BO_ 581 14;
BA_ "GenMsgCycleTime" BO_ 582 20;
BA_ "VFrameFormat" BO_ 582 14;
BA_ "GenMsgCycleTime" BO_ 584 50;
BA_ "VFrameFormat" BO_ 584 14;
BA_ "GenMsgCycleTime" BO_ 589 50;
BA_ "VFrameFormat" BO_ 589 14;
BA_ "GenMsgCycleTime" BO_ 593 20;
BA_ "VFrameFormat" BO_ 593 14;
BA_ "GenMsgCycleTime" BO_ 613 20;
BA_ "VFrameFormat" BO_ 613 14;
BA_ "GenMsgCycleTime" BO_ 616 50;
BA_ "VFrameFormat" BO_ 616 14;
BA_ "GenMsgCycleTime" BO_ 621 100;
BA_ "VFrameFormat" BO_ 621 14;
BA_ "GenMsgCycleTime" BO_ 622 100;
BA_ "VFrameFormat" BO_ 622 14;
BA_ "GenMsgCycleTime" BO_ 623 50;
BA_ "VFrameFormat" BO_ 623 14;
BA_ "GenMsgCycleTime" BO_ 625 20;
BA_ "VFrameFormat" BO_ 625 14;
BA_ "GenMsgCycleTime" BO_ 627 50;
BA_ "VFrameFormat" BO_ 627 14;
BA_ "GenMsgCycleTime" BO_ 628 50;
BA_ "VFrameFormat" BO_ 628 14;
BA_ "GenMsgCycleTime" BO_ 639 50;
BA_ "VFrameFormat" BO_ 639 14;
BA_ "GenMsgCycleTime" BO_ 645 100;
BA_ "VFrameFormat" BO_ 645 14;
BA_ "GenMsgCycleTime" BO_ 647 100;
BA_ "VFrameFormat" BO_ 647 14;
BA_ "GenMsgCycleTime" BO_ 652 100;
BA_ "VFrameFormat" BO_ 652 14;
BA_ "GenMsgCycleTime" BO_ 656 100;
BA_ "VFrameFormat" BO_ 656 14;
BA_ "GenMsgCycleTime" BO_ 659 100;
BA_ "VFrameFormat" BO_ 659 14;
BA_ "GenMsgCycleTime" BO_ 661 50;
BA_ "VFrameFormat" BO_ 661 14;
BA_ "GenMsgCycleTime" BO_ 664 100;
BA_ "VFrameFormat" BO_ 664 14;
BA_ "GenMsgCycleTime" BO_ 669 100;
BA_ "VFrameFormat" BO_ 669 14;
BA_ "GenMsgCycleTime" BO_ 671 100;
BA_ "VFrameFormat" BO_ 671 14;
BA_ "GenMsgCycleTime" BO_ 680 100;
BA_ "VFrameFormat" BO_ 680 14;
BA_ "GenMsgCycleTime" BO_ 683 100;
BA_ "VFrameFormat" BO_ 683 14;
BA_ "GenSigStartValue" SG_ 0 HCU_ECODrvHabit_Indcn 100;
BA_ "GenSigStartValue" SG_ 0 HCU_TotDrvReqPower 100;
BA_ "GenSigSendType" SG_ 51 T_Box_RemtWinCtrl 10;
BA_ "GenSigSendType" SG_ 51 T_Box_RemtTrunkCtrl 10;
BA_ "GenSigSendType" SG_ 51 T_Box_RemtDoorLockCtrl 10;
BA_ "GenSigSendType" SG_ 51 T_Box_AudioMuteReq 10;
BA_ "GenSigSendType" SG_ 51 T_Box_RemtDrvTempSet 10;
BA_ "GenSigSendType" SG_ 51 T_Box_RemtAutoCtrl 10;
BA_ "GenSigSendType" SG_ 51 T_Box_RemtPassTempSet 10;
BA_ "GenSigSendType" SG_ 51 T_Box_RemtSsCtrl 10;
BA_ "GenSigSendType" SG_ 51 T_Box_RemtSrCtrl 10;
BA_ "GenSigSendType" SG_ 51 T_Box_RemtDrvSeatVentnLvlSet 10;
BA_ "GenSigSendType" SG_ 51 T_Box_RemtPassSeatVentnLvlSet 10;
BA_ "GenSigSendType" SG_ 51 T_Box_RemtAIUReq 10;
BA_ "GenSigSendType" SG_ 51 T_Box_PM25AirQLvl 10;
BA_ "GenSigStartValue" SG_ 51 T_Box_PM25AirQLvl 7;
BA_ "GenSigSendType" SG_ 51 T_Box_RemtCarSearch 10;
BA_ "GenSigSendType" SG_ 51 T_Box_RemtEngCtrl 10;
BA_ "GenSigSendType" SG_ 51 T_Box_RemtDrvSeatHeatgLvlSet 10;
BA_ "GenSigSendType" SG_ 51 T_Box_RemtPassSeatHeatgLvlSet 10;
BA_ "GenSigSendType" SG_ 51 T_Box_PM25Dens 10;
BA_ "GenSigStartValue" SG_ 51 T_Box_PM25Dens 1023;
BA_ "GenSigSendType" SG_ 51 FreshnessValue_T_Box_FD1 10;
BA_ "GenSigSendType" SG_ 51 MAC_Check_T_Box_FD1 10;
BA_ "GenSigSendType" SG_ 53 PEPS_T_BoxAuth1 10;
BA_ "GenSigSendType" SG_ 54 T_Box_PEPSAuth1 10;
BA_ "GenSigSendType" SG_ 70 PEPS_T_BoxAuth2 10;
BA_ "GenSigSendType" SG_ 72 T_Box_PEPSAuth2 10;
BA_ "GenSigSendType" SG_ 74 AUTODefrost_TC 10;
BA_ "GenSigSendType" SG_ 74 AUTODefrost_VR 10;
BA_ "GenSigSendType" SG_ 74 LaneCalActvtCmd 10;
BA_ "GenSigSendType" SG_ 74 MODChgReq 10;
BA_ "GenSigSendType" SG_ 74 Radar_DispCmd 10;
BA_ "GenSigSendType" SG_ 74 Guid_Ovl_Display_Cmd 10;
BA_ "GenSigSendType" SG_ 74 Sgl_View_Sel 10;
BA_ "GenSigSendType" SG_ 74 SwToFieldCalRstCmd 10;
BA_ "GenSigSendType" SG_ 74 AutoViewChgCmd 10;
BA_ "GenSigSendType" SG_ 74 MdlColrChgCmd 10;
BA_ "GenSigSendType" SG_ 74 CarMdlTrsprcySwtCmd 10;
BA_ "GenSigSendType" SG_ 74 CarMdlDispCmd 10;
BA_ "GenSigSendType" SG_ 74 AutoAVMSwSet_Cmd 10;
BA_ "GenSigSendType" SG_ 74 FPAS_AutoModSwt 10;
BA_ "GenSigSendType" SG_ 74 MEBSwtSet 10;
BA_ "GenSigSendType" SG_ 74 WshSoftSwt 10;
BA_ "GenSigSendType" SG_ 74 View_SoftswitchCmd 10;
BA_ "GenSigSendType" SG_ 86 E_CALLSts 10;
BA_ "GenSigSendType" SG_ 86 QuietVoiceReq 10;
BA_ "GenSigStartValue" SG_ 96 HCU_AccelPedalPosn_DiagValid 1;
BA_ "GenSigStartValue" SG_ 130 NetEngTrq 32767;
BA_ "GenSigStartValue" SG_ 130 DrvEngTrqReq 32767;
BA_ "GenSigStartValue" SG_ 130 DrvEngTrqReqVld 1;
BA_ "GenSigStartValue" SG_ 132 EngTrqEstimdActGear 32767;
BA_ "GenSigStartValue" SG_ 132 EngTrqEstimdActGear_Qf 1;
BA_ "GenSigStartValue" SG_ 134 TrqLoss 32767;
BA_ "GenSigStartValue" SG_ 241 BMS_PackVolt 178;
BA_ "GenSigStartValue" SG_ 273 EngSpdVldty 2;
BA_ "GenSigStartValue" SG_ 282 HCU_GearSts 14;
BA_ "GenSigStartValue" SG_ 311 ESP_MasterCylBrkPressVld 1;
BA_ "GenSigStartValue" SG_ 311 ABSFailSts 1;
BA_ "GenSigStartValue" SG_ 311 VehOdoInfoSts 1;
BA_ "GenSigStartValue" SG_ 325 DrivingModReq_ESP 1;
BA_ "GenSigStartValue" SG_ 327 EPS_TrqSnsrSts 1;
BA_ "GenSigStartValue" SG_ 347 APS_ProcBar 127;
BA_ "GenSigSendType" SG_ 481 T_Box_BMSReMtPreHeatT 10;
BA_ "GenSigSendType" SG_ 481 Phone_ChrgnMode 10;
BA_ "GenSigSendType" SG_ 481 T_Box_IntelEngIdlChrgnSwt 10;
BA_ "GenSigSendType" SG_ 481 T_Box_BattKeepTemp 10;
BA_ "GenSigSendType" SG_ 481 T_Box_RemtFrntDefrostCtrl 10;
BA_ "GenSigSendType" SG_ 481 T_Box_RemtRearDefrostCtrl 10;
BA_ "GenSigSendType" SG_ 481 TBOX_RemtVideoMonrEnaReq_APP 10;
BA_ "GenSigSendType" SG_ 481 T_Box_RemtCockpitClnReq 10;
BA_ "GenSigSendType" SG_ 481 T_Box_RemtSdlMod 10;
BA_ "GenSigStartValue" SG_ 481 T_Box_RemtSdlMod 3;
BA_ "GenSigSendType" SG_ 482 HCU_PhoneChrgnModeResp 10;
BA_ "GenSigSendType" SG_ 482 HCU_PhoneChrgnReqResp 10;
BA_ "GenSigSendType" SG_ 482 HCU_HUTChrgnModeResp 10;
BA_ "GenSigSendType" SG_ 482 HCU_HUTChrgnReqResp 10;
BA_ "GenSigSendType" SG_ 482 HCU_TboxEngStrtReq 10;
BA_ "GenSigSendType" SG_ 482 HCU_TotalScore 10;
BA_ "GenSigSendType" SG_ 482 HCU_IntelBattTempMagResp 10;
BA_ "GenSigSendType" SG_ 482 HCU_RemtVehStartReq 10;
BA_ "GenSigSendType" SG_ 483 BMS_BattKeepTempResp_PHEV 10;
BA_ "GenSigSendType" SG_ 489 BackReq_AVM 10;
BA_ "GenSigSendType" SG_ 489 HUD_HeightLvlSwt 10;
BA_ "GenSigSendType" SG_ 489 HUD_BrightnessLvlSwt 10;
BA_ "GenSigSendType" SG_ 489 HUD_SwtReq 10;
BA_ "GenSigSendType" SG_ 489 ExprsnSetUp 10;
BA_ "GenSigStartValue" SG_ 489 ExprsnSetUp 1;
BA_ "GenSigSendType" SG_ 489 DistrctnDetnSet 10;
BA_ "GenSigStartValue" SG_ 489 DistrctnDetnSet 1;
BA_ "GenSigSendType" SG_ 489 DrowsnsDetnSet 10;
BA_ "GenSigStartValue" SG_ 489 DrowsnsDetnSet 1;
BA_ "GenSigSendType" SG_ 489 FaceIdnSet 10;
BA_ "GenSigStartValue" SG_ 489 FaceIdnSet 1;
BA_ "GenSigSendType" SG_ 489 VoiceIdnSet 10;
BA_ "GenSigStartValue" SG_ 489 VoiceIdnSet 1;
BA_ "GenSigSendType" SG_ 489 EraseAllFaceUsersReq 10;
BA_ "GenSigStartValue" SG_ 489 EraseAllFaceUsersReq 1;
BA_ "GenSigSendType" SG_ 489 EraseAllVoiceUsersReq 10;
BA_ "GenSigStartValue" SG_ 489 EraseAllVoiceUsersReq 1;
BA_ "GenSigSendType" SG_ 489 CancelVoiceIdn 10;
BA_ "GenSigStartValue" SG_ 489 CancelVoiceIdn 1;
BA_ "GenSigSendType" SG_ 489 EnrollFaceReq 10;
BA_ "GenSigStartValue" SG_ 489 EnrollFaceReq 2;
BA_ "GenSigSendType" SG_ 489 EnrollUserIDResult 10;
BA_ "GenSigStartValue" SG_ 489 EnrollUserIDResult 15;
BA_ "GenSigSendType" SG_ 489 DeleteUserIDFaceData 10;
BA_ "GenSigStartValue" SG_ 489 DeleteUserIDFaceData 15;
BA_ "GenSigSendType" SG_ 489 DeleteUserIDVoiceData 10;
BA_ "GenSigStartValue" SG_ 489 DeleteUserIDVoiceData 15;
BA_ "GenSigSendType" SG_ 493 MbrMonrEnReq_TC 10;
BA_ "GenSigSendType" SG_ 493 ApproachLampSet 10;
BA_ "GenSigStartValue" SG_ 493 ApproachLampSet 2;
BA_ "GenSigSendType" SG_ 493 FlaoutUnlockSet 10;
BA_ "GenSigStartValue" SG_ 493 FlaoutUnlockSet 2;
BA_ "GenSigSendType" SG_ 493 SuperLockSet 10;
BA_ "GenSigStartValue" SG_ 493 SuperLockSet 2;
BA_ "GenSigSendType" SG_ 493 PrkInDirChoice 10;
BA_ "GenSigSendType" SG_ 493 PathLrngFinshCmd 10;
BA_ "GenSigSendType" SG_ 493 PathLrngStartCmd 10;
BA_ "GenSigSendType" SG_ 493 SelPrkOutDirReq 10;
BA_ "GenSigSendType" SG_ 493 ParkMdlCmd 10;
BA_ "GenSigSendType" SG_ 493 BackReq_APS 10;
BA_ "GenSigSendType" SG_ 493 StartPrkgPath2Cmd 10;
BA_ "GenSigSendType" SG_ 493 DeletePath2Cmd 10;
BA_ "GenSigSendType" SG_ 493 StartPrkgPath1Cmd 10;
BA_ "GenSigSendType" SG_ 493 DeletePath1Cmd 10;
BA_ "GenSigSendType" SG_ 493 SelPrkgFctnCmd 10;
BA_ "GenSigSendType" SG_ 493 RLWinSwtReq_VR 10;
BA_ "GenSigSendType" SG_ 493 RRWinSwtReq_VR 10;
BA_ "GenSigSendType" SG_ 493 DrvWinSwtReq_VR 10;
BA_ "GenSigSendType" SG_ 493 PassWinSwtReq_VR 10;
BA_ "GenSigSendType" SG_ 494 ACOperMod_TC 10;
BA_ "GenSigSendType" SG_ 494 ACOperMod_VR 10;
BA_ "GenSigSendType" SG_ 494 SteerWheelHeatSwtReq 10;
BA_ "GenSigStartValue" SG_ 494 SteerWheelHeatSwtReq 1;
BA_ "GenSigSendType" SG_ 494 ACDrvSetTempSteplsReq_TC 10;
BA_ "GenSigSendType" SG_ 494 ACPassSetTempSteplsReq_TC 10;
BA_ "GenSigSendType" SG_ 494 SDWSwtSet 10;
BA_ "GenSigSendType" SG_ 494 APSSwtReq_VR 10;
BA_ "GenSigSendType" SG_ 494 PASExitSpdSwt 10;
BA_ "GenSigSendType" SG_ 494 APSPrkgTypSeln 10;
BA_ "GenSigSendType" SG_ 494 SunShadeSwtReq_VR 10;
BA_ "GenSigSendType" SG_ 494 SunRoofSwtReq_VR 10;
BA_ "GenSigSendType" SG_ 494 SportModLightSet 10;
BA_ "GenSigStartValue" SG_ 494 SportModLightSet 1;
BA_ "GenSigSendType" SG_ 494 ABSLmpSet 10;
BA_ "GenSigStartValue" SG_ 494 ABSLmpSet 1;
BA_ "GenSigSendType" SG_ 494 AutoWshWipSet 10;
BA_ "GenSigStartValue" SG_ 494 AutoWshWipSet 2;
BA_ "GenSigSendType" SG_ 494 SeekVehSet 10;
BA_ "GenSigSendType" SG_ 494 SpdAutoLockModSet 10;
BA_ "GenSigStartValue" SG_ 494 SpdAutoLockModSet 2;
BA_ "GenSigSendType" SG_ 494 ParkLmpSet 10;
BA_ "GenSigStartValue" SG_ 494 ParkLmpSet 1;
BA_ "GenSigSendType" SG_ 494 DoorUnlockModSet 10;
BA_ "GenSigSendType" SG_ 494 ACEAHReq_TC 10;
BA_ "GenSigSendType" SG_ 494 ACEAHReq_VR 10;
BA_ "GenSigSendType" SG_ 494 FreshnessValue_HUT15 10;
BA_ "GenSigSendType" SG_ 494 MAC_Check_HUT15 10;
BA_ "GenSigStartValue" SG_ 545 TGS_LEVER 14;
BA_ "GenSigStartValue" SG_ 551 AEB_PedResp 1;
BA_ "GenSigStartValue" SG_ 551 AEB_VehResp 1;
BA_ "GenSigStartValue" SG_ 551 AEB_JA_Resp 1;
BA_ "GenSigStartValue" SG_ 568 SsPosn_VR_APP 127;
BA_ "GenSigStartValue" SG_ 568 SrPosn_VR_APP 127;
BA_ "GenSigStartValue" SG_ 573 IFC_LaneCurve 2047;
BA_ "GenSigStartValue" SG_ 573 IFC_LeLane_dy 2496;
BA_ "GenSigStartValue" SG_ 573 IFC_RiLane_dy 2496;
BA_ "GenSigStartValue" SG_ 573 IFC_NextLeLane_dy 2496;
BA_ "GenSigStartValue" SG_ 573 IFC_NextRiLane_dy 2496;
BA_ "GenSigStartValue" SG_ 581 VehLgtAccel 22033;
BA_ "GenSigStartValue" SG_ 589 DrowsnsLvl 7;
BA_ "GenSigStartValue" SG_ 589 DrowsnsLvlQlty 127;
BA_ "GenSigStartValue" SG_ 589 DMSProc 7;
BA_ "GenSigStartValue" SG_ 589 DMSProcResult 15;
BA_ "GenSigStartValue" SG_ 589 DMSProcSts 15;
BA_ "GenSigStartValue" SG_ 589 DMSIdnResult 15;
BA_ "GenSigStartValue" SG_ 589 GenderSts 3;
BA_ "GenSigStartValue" SG_ 589 ExprsnSts 7;
BA_ "GenSigStartValue" SG_ 589 GenderStsQlty 127;
BA_ "GenSigStartValue" SG_ 589 ExprsnStsQlty 127;
BA_ "GenSigStartValue" SG_ 589 DistrctnLvl_ACC 7;
BA_ "GenSigStartValue" SG_ 589 DistrctnLvlQlty_ACC 127;
BA_ "GenSigStartValue" SG_ 589 DrowsnsLvl_ACC 7;
BA_ "GenSigStartValue" SG_ 589 DrowsnsLvlQlty_ACC 127;
BA_ "GenSigStartValue" SG_ 589 DistrctnLvl 7;
BA_ "GenSigStartValue" SG_ 589 DistrctnLvlQlty 127;
BA_ "GenSigStartValue" SG_ 589 HeadPosnX 2047;
BA_ "GenSigStartValue" SG_ 589 HeadPosnY 2047;
BA_ "GenSigStartValue" SG_ 589 HeadPosnZ 2047;
BA_ "GenSigStartValue" SG_ 589 HeadPosQlty 127;
BA_ "GenSigStartValue" SG_ 589 GazePosnX 2047;
BA_ "GenSigStartValue" SG_ 589 GazePosnY 2047;
BA_ "GenSigStartValue" SG_ 589 GazePosnZ 2047;
BA_ "GenSigStartValue" SG_ 589 DMSSts 7;
BA_ "GenSigStartValue" SG_ 589 HeadYawAng 255;
BA_ "GenSigStartValue" SG_ 589 HeadPitchAng 255;
BA_ "GenSigStartValue" SG_ 589 HeadRollAng 255;
BA_ "GenSigStartValue" SG_ 589 HeadRotAngQlty 127;
BA_ "GenSigStartValue" SG_ 589 LEyeOpenSts 2;
BA_ "GenSigStartValue" SG_ 589 LEyeOpenStsQlty 100;
BA_ "GenSigStartValue" SG_ 589 REyeOpenSts 2;
BA_ "GenSigStartValue" SG_ 589 REyeOpenStsQlty 100;
BA_ "GenSigStartValue" SG_ 589 RobustGazeYawAng 255;
BA_ "GenSigStartValue" SG_ 589 RobustGazePitchAng 255;
BA_ "GenSigStartValue" SG_ 589 RobustGazeAngQlty 127;
BA_ "GenSigStartValue" SG_ 613 ABSFailSts_ 1;
BA_ "GenSigStartValue" SG_ 613 VehOdoInfoSts_ 1;
BA_ "GenSigStartValue" SG_ 616 HCU_ChrgDchrgSts 2;
BA_ "GenSigStartValue" SG_ 621 FPAS_NearBrrdstn_ 127;
BA_ "GenSigStartValue" SG_ 623 XLvl 2047;
BA_ "GenSigStartValue" SG_ 623 YLvl 2047;
BA_ "GenSigStartValue" SG_ 625 AccelPedalPosnVldty 2;
BA_ "GenSigStartValue" SG_ 659 IP_CurrTheme 4;
BA_ "GenSigStartValue" SG_ 659 IP_FuelMainTankR 10;
BA_ "GenSigStartValue" SG_ 659 IP_FuelAuxTankR 10;
BA_ "GenSigStartValue" SG_ 659 IP_LagueSet 15;
BA_ "GenSigStartValue" SG_ 664 RPAS_NearBrrdstn_ 255;
BA_ "GenSigStartValue" SG_ 664 FPAS_NearBrrdstn 127;
BA_ "GenSigStartValue" SG_ 669 InCarTemp 254;
BA_ "GenSigStartValue" SG_ 669 ACDrvAirDistriMod 7;
BA_ "GenSigStartValue" SG_ 683 ACC_SpdSetValue 255;
VAL_ 0 HCU_DrvMod 0 " Auto/Normal Mode started " 1 " EV Mode started " 2 " Save Mode started " 3 " SPORT Mode started " 4 " AWD Normal Mode started " 5 " Snow Mode started " 6 " Muddy Mode started " 7 " Sand Mode started " 8 " ECO " 9 " SPORT Plus Mode started " 10 " Reserved " ;
VAL_ 0 HCUImmoAuthRes 0 " Idle " 1 " Passed " 2 " Failed " 3 " Invalid value " ;
VAL_ 0 HCU_EVLmpSts 0 " Not active " 1 " Active " ;
VAL_ 0 HCU_ECODrvHabit_Indcn 0 " Valid values " 201 " Reversed " ;
VAL_ 0 HCU_TotDrvReqPower 0 " Valid values-Power percentage Value（-100-0-100） " 201 " invalid values " ;
VAL_ 0 HCU_AvailPower_TM 0 " Valid values " 101 " invalid values " ;
VAL_ 51 T_Box_RemtWinCtrl 0 " No Action " 1 " Close " 2 " Open(reserved) " 3 " Half_Open(reserved) " 4 " reserved " ;
VAL_ 51 T_Box_RemtTrunkCtrl 0 " No action " 1 " Open " 2 " Close " 3 " Reserved " ;
VAL_ 51 T_Box_RemtDoorLockCtrl 0 " No Action " 1 " Driver door unlock  " 2 " All doors unlock " 3 " Lock " 4 " Invalid " 5 " reserved " ;
VAL_ 51 T_Box_AudioMuteReq 0 " No action " 1 " Request mute " 2 " Request unmute " 3 " Reserved " ;
VAL_ 51 T_Box_RemtDrvTempSet 0 " No action " 1 " Valid Value(Phys = 0.5 * raw + 16)           " 32 " Reserved " ;
VAL_ 51 T_Box_RemtAutoCtrl 0 " No action " 1 " Off " 2 " On " 3 " Reserved " ;
VAL_ 51 T_Box_RemtPassTempSet 0 " No action " 1 " Valid Value(Phys = 0.5 * raw + 16)           " 32 " Reserved " ;
VAL_ 51 T_Box_RemtSsCtrl 0 " No action " 1 " Full closed " 2 " 10% " 3 " 20% " 4 " 30% " 5 " 40% " 6 " 50% " 7 " 60% " 8 " 70% " 9 " 80% " 10 " 90% " 11 " Full open " 12 " Stop " 13 " Reserved " ;
VAL_ 51 T_Box_RemtSrCtrl 0 " No action " 1 " Full closed " 2 " Tile Up " 3 " 10% " 4 " 20% " 5 " 30% " 6 " 40% " 7 " 50% " 8 " 60% " 9 " 70% " 10 " 80% " 11 " 90% " 12 " Full open " 13 " Stop " 14 " Reserved " ;
VAL_ 51 T_Box_RemtDrvSeatVentnLvlSet 0 " No Action " 1 " OFF " 2 " Level1（低） " 3 " Level2（中） " 4 " Level3（高） " 5 " Reserved " ;
VAL_ 51 T_Box_RemtPassSeatVentnLvlSet 0 " No Action " 1 " OFF " 2 " Level1_low " 3 " Level2_Middle " 4 " Level3_high " 5 " Reserved " ;
VAL_ 51 T_Box_RemtAIUReq 0 " no action " 1 " inactive " 2 " active " 3 " reserved " ;
VAL_ 51 T_Box_PM25AirQLvl 0 " Level 1 " 1 " Level 2 " 2 " Level 3 " 3 " Level 4 " 4 " Level 5 " 5 " Level 6 " 6 " Reserved " 7 " TSP return error " 8 " Current city no information " 9 " No network signal " 10 " Reserved " ;
VAL_ 51 T_Box_RemtCarSearch 0 " No action " 1 " Whistle " 2 " Light " 3 " Light+Whistle " ;
VAL_ 51 T_Box_RemtEngCtrl 0 " No Action  " 1 " Start  " 2 " Stop " 3 " InValid " ;
VAL_ 51 T_Box_RemtDrvSeatHeatgLvlSet 0 " No Action " 1 " OFF " 2 " Level1（低） " 3 " Level2（中） " 4 " Level3（高） " 5 " Reserved " ;
VAL_ 51 T_Box_RemtPassSeatHeatgLvlSet 0 " No Action " 1 " OFF " 2 " Level1_low " 3 " Level2（中） " 4 " Level3（高） " 5 " Reserved " ;
VAL_ 51 T_Box_PM25Dens 0 " PM2.5 density  " 1000 " Current city no information " 1001 " No network signal " 1002 " Reserved " 1023 " Invalid " ;
VAL_ 53 PEPS_T_BoxAuth1 0 " Valid Value " ;
VAL_ 74 AUTODefrost_TC 0 " No action " 1 " Pressed " 2 " Reserved " 3 " Reserved " ;
VAL_ 74 AUTODefrost_VR 0 " No action " 1 " Not active " 2 " Active " 3 " Reserved " ;
VAL_ 74 LaneCalActvtCmd 0 " Off " 1 " On " ;
VAL_ 74 MODChgReq 0 " No request " 1 " Request " ;
VAL_ 74 Radar_DispCmd 0 " No Request " 1 " Request  " ;
VAL_ 74 Guid_Ovl_Display_Cmd 0 " No Request " 1 " Request  " ;
VAL_ 74 Sgl_View_Sel 0 " No Commands " 1 " Touch 2D Front Button " 2 " Touch 2D Rear Button " 3 " Touch 2D Left Button  " 4 " Touch 2D Right Button " 5 " Touch 2D Left Front  Button " 6 " Touch 2D Right Front Button " 7 " Touch 2D Left Back Button " 8 " Touch 2D Right Back Button " 9 " Touch return Button " 10 " Touch Engine Room Button " 11 " Reserved " ;
VAL_ 74 SwToFieldCalRstCmd 0 " Off " 1 " On " ;
VAL_ 74 AutoViewChgCmd 0 " No Request " 1 " Request  " ;
VAL_ 74 MdlColrChgCmd 0 " No Request " 1 " Request  " ;
VAL_ 74 CarMdlTrsprcySwtCmd 0 " No Request " 1 " Request  " ;
VAL_ 74 CarMdlDispCmd 0 " No Request " 1 " Request  " ;
VAL_ 74 AutoAVMSwSet_Cmd 0 " No Request " 1 " Request  " ;
VAL_ 74 FPAS_AutoModSwt 0 " No Request " 1 " Request  " ;
VAL_ 74 MEBSwtSet 0 " No Request " 1 " Request  " ;
VAL_ 74 WshSoftSwt 0 " No request " 1 " Request " ;
VAL_ 74 View_SoftswitchCmd 0 " No request " 1 " Request " ;
VAL_ 86 E_CALLSts 0 " No Action " 1 " Dialing in " 2 " Dialing out " 3 " On call " 4 " Hang up " 5 " Build failed " ;
VAL_ 86 QuietVoiceReq 0 " OFF " 1 " ON " ;
VAL_ 96 HCU_AccelPedalPosn_Diag 0 " Vaild value " ;
VAL_ 96 HCU_AccelPedalPosn_DiagValid 0 " Invaild " 1 " Vaild " ;
VAL_ 96 HCU_RaceLaunchSts 0 " Not active " 1 " Active " 2 " Timeout protection " 3 " Reserved " ;
VAL_ 96 HCU_RaceLaunchAvail 0 " Race Launch is available  " 1 " Race Launch is not available due to ESP is not OFF  " 2 " Race Launch is not available due to temporary hybrid system limitations  " 3 " Reserved  " ;
VAL_ 130 NetEngTrq 0 " Valid values  " 65535 " Invalid " ;
VAL_ 130 DrvEngTrqReq 0 " Valid values  " ;
VAL_ 130 DrvEngTrqReqVld 0 " Invalid " 1 " Valid " ;
VAL_ 132 EngTrqEstimdActGear 0 " Valid values  " ;
VAL_ 132 EngTrqEstimdActGear_Qf 0 " Invalid " 1 " Valid " ;
VAL_ 134 TrqLoss 0 " Valid values  " ;
VAL_ 147 TMCU_ActPosRotSpd 0 " Valid " 65535 " Invalid " ;
VAL_ 161 SteerWheelAng 0 " Valid value " 7801 " Reserved " 32767 " Invalid " ;
VAL_ 161 SteerWheelAngSign 0 " Left (Positive) " 1 " Right (Negative) " ;
VAL_ 166 TgtEngSpdIP 0 " Valid values " ;
VAL_ 166 TgtEngSpdIPValid 0 " Invalid " 1 " valid " ;
VAL_ 166 TrsmTqIdle 0 " Valid values " 65535 " Invalid " ;
VAL_ 193 TCU_ErrCategory 6 " Warning " 5 " Partial function-external " 4 " Partial function-internal " 3 " Disable-NP " 2 " Diable " 1 " Reservde " 0 " EOL not finish " ;
VAL_ 193 TCU_ParkErrCategory 2 " Warning " 1 " Parking failed " 11 " Warning " ;
VAL_ 193 TCU_ClutchHotWarning 0 " Normal " 1 " Warnining " 2 " Degrading " 3 " ClutchOpen " ;
VAL_ 200 ESP_HMI_WarningOn 0 " No warning lamp " 1 " Yellow Lamp " 2 " Red Lamp " 3 " reserved " ;
VAL_ 216 TgtRcprtnTrqSts 0 " Not Initialized " 1 " Normal " 2 " Faulty " 3 " Reserved " ;
VAL_ 241 BMS_BattPoweErr 0 " No Error " 1 " TM power unavailable " 2 " P2M power unavailable " 3 " OBC power unavailable " ;
VAL_ 241 BMS_ErrCategory 0 " No Error " 1 " Warning " 2 " Derating  " 3 " Instrument Display（Yellow） " 4 " Range Limited（Yellow） " 5 " Pre-charge Locked（Red） " 6 " Delayed Open（Red） " 7 " Emergency Open(Red) " ;
VAL_ 241 BMS_PackCurr 0 " Valid value " 5001 " Reserved " 8191 " Invalid " ;
VAL_ 241 BMS_PackVolt 0 " Valid value " 246 " Reserved " 255 " Invalid " ;
VAL_ 258 AccelPedlPosnDiagc 0 " Valid values  " ;
VAL_ 273 EMS_AuthenResult 0 " Nothing " 1 " Authentication failure " 2 " Authentication success " 3 " Reserved " ;
VAL_ 273 EngSpd 0 " Valid values  " ;
VAL_ 273 EngSpdVldty 0 " Invalid " 1 " Valid " 2 " Initial value " 3 " Reserved " ;
VAL_ 273 BrkPedalSts 0 " Not pressed " 1 " Pressed " 2 " Reserved " 3 " Error " ;
VAL_ 279 EngState_PHEV 0 " Stand by " 1 " Ready " 2 " Cranking " 3 " Running " 4 " Stopping " 5 " Finish " 6 " Autostopping " 7 " Reserved " ;
VAL_ 279 CruiseCtrlSts_PHEV 0 " OFF " 1 " Stand by " 2 " Cruise " 3 " Acceleration  " 4 " Deceleration " 5 " Tip up " 6 " Tip dwon " 7 " Resume from above vehicle speed " 8 " Resume from below vehicle speed " 9 " Error " 10 " Reserved " ;
VAL_ 282 HCU_GearSts 0 " Select lever in position -P- " 1 " Reserved " 2 " Reserved " 3 " Reserved " 4 " Reserved " 5 " Select lever in position -D- " 6 " Select lever in position -N- " 7 " Select lever in position -R- " 8 " Reserved " 14 " Intermediate position " 15 " Invalid  " ;
VAL_ 288 IB_Warn 0 " Warning lamp off " 1 " Warning lamp on " ;
VAL_ 311 CheckSum_ESP2 0 " Valid values " ;
VAL_ 311 BrkDskOvrheatd 0 " Not high " 1 " Temp too high " ;
VAL_ 311 NoBrkForce 0 " Exist brake force " 1 " No brake force " ;
VAL_ 311 VehStandstill 0 " Not standstill " 1 " Standstill " 2 " InValid values (short unavailability, max 3s) " 3 " Reserved " ;
VAL_ 311 AEBIBActv 0 " Not active " 1 " Active " ;
VAL_ 311 AEBBAActv 0 " Not active " 1 " Active " ;
VAL_ 311 AEBAvailable 0 " Unusable " 1 " Usable " ;
VAL_ 311 ABPAvailable 0 " Unusable " 1 " Usable " ;
VAL_ 311 ABPActv 0 " Not active " 1 " Active " ;
VAL_ 311 ABAavailable 0 " Unusable " 1 " Usable " ;
VAL_ 311 ABAActv 0 " Not active " 1 " Active " ;
VAL_ 311 HDCFault 0 " No failure " 1 " Failure when HDC is on need " 2 " Failure when is not on need " 3 " Reserved " ;
VAL_ 311 HDCCtrl 0 " OFF " 1 " On active braking " 2 " On not active braking " ;
VAL_ 311 CDDActv 0 " Not active " 1 " Active " ;
VAL_ 311 CDDAvailable 0 " Not available " 1 " Available " ;
VAL_ 311 AWBAvailable 0 " Unusable " 1 " Usable " ;
VAL_ 311 AWBActv 0 " Not active " 1 " Active " ;
VAL_ 311 AVHErrSts 0 " No failure " 1 " Failure when AVH is on need " 2 " Failure when is not on need " 3 " Reserved " ;
VAL_ 311 AVHSts 0 " Off " 1 " Standby  " 2 " active " ;
VAL_ 311 CDPActv 0 " Not active " 1 " Active " ;
VAL_ 311 RollingCounter_ESP2 0 " Valid value " 15 " Invalid value " ;
VAL_ 311 CheckSum_ESP1 0 " Valid values " ;
VAL_ 311 ESPFuncOffSts 0 " Available/On " 1 " Unavailable/Off " ;
VAL_ 311 ESPActvInfoLmp 0 " Not active " 1 " Active " ;
VAL_ 311 ESPBrkLmpCtrl 0 " Brake light off " 1 " Brake light on " ;
VAL_ 311 ESPFailSts 0 " No failure " 1 " Failure " ;
VAL_ 311 ESP_MasterCylBrkPressVld 0 " Invalid " 1 " Valid " ;
VAL_ 311 MSRActv 0 " Not active " 1 " Active " ;
VAL_ 311 VDCActv 0 " Not active " 1 " Active " ;
VAL_ 311 PTCActv 0 " Not active " 1 " Active " ;
VAL_ 311 BTCActv 0 " Not active " 1 " Active " ;
VAL_ 311 ESP_MasterCylBrkPress 0 " Valid values " 14961 " Reserved " ;
VAL_ 311 RollingCounter_ESP1 0 " Valid value " 15 " Invalid value " ;
VAL_ 311 CheckSum_ABS3 0 " Valid values " ;
VAL_ 311 ABSFailSts 0 " No failure " 1 " Failure " ;
VAL_ 311 EBDFailSts 0 " No failure " 1 " Failure " ;
VAL_ 311 VehSpdVld 0 " Invalid values " 1 " Valid values " ;
VAL_ 311 VehSpd 0 " Valid values " 5334 " Reserved " ;
VAL_ 311 EBDActv 0 " Not active " 1 " Active " ;
VAL_ 311 ABSActv 0 " Not active " 1 " Active " ;
VAL_ 311 VehOdoInfoSts 0 " Invalid value " 1 " Valid value " ;
VAL_ 311 VehOdoInfo 0 " Valid values " 1000 " Reserved " ;
VAL_ 311 RollingCounter_ABS3 0 " Valid value " 15 " Invalid value " ;
VAL_ 313 Tgtgear_Up 0 " Gear shiftup display off  " 1 " Gear shiftup display on " ;
VAL_ 313 Tgtgear_Down 0 " Gear shiftdown display off  " 1 " Gear shiftdown display on " ;
VAL_ 313 NeutralSts 0 " Gear not in neutral " 1 " Gear in neutral " 2 " Not Available " 3 " Reserved " ;
VAL_ 325 CheckSum_ESP2_ 0 " Valid values " ;
VAL_ 325 HDCFault_ 0 " No failure " 1 " Failure when HDC is on need " 2 " Failure when is not on need " 3 " Reserved " ;
VAL_ 325 HDCCtrl_ 0 " OFF " 1 " On active braking " 2 " On not active braking " 3 " Reserved " ;
VAL_ 325 AVHErrSts_ 0 " No failure " 1 " Failure when AVH is on need " 2 " Failure when is not on need " 3 " Reserved " ;
VAL_ 325 AVHSts_ 0 " Off " 1 " Standby  " 2 " active " 3 " Reserved " ;
VAL_ 325 CDPActv_ 0 " Not active " 1 " Active " ;
VAL_ 325 DrivingModDis 0 " Standard " 1 " Sport " 2 " Snow " 3 " Mud " 4 " Sand " 5 " 4L(reserved) " 6 " Economic " 7 " Mode Unkown " 8 " Reserved " 9 " Sport+ " 10 " Off road " 11 " Standard_2H(reserved) " 12 " Reserved " 13 " Standard_4H（reserved） " 14 " Failed " 15 " Invalid Value " 16 " Snow_4H(reserved) " 17 " Normal_4L(reserved) " 18 " Rock_4L(reserved) " 19 " Pothle_4L(reserved) " 20 " Mud/Sand_4L(reserved) " 21 " Mountain_4L(reserved) " 22 " reserved " ;
VAL_ 325 DrivingModReq_ESP 0 " No Terrain Control " 1 " Standard " 2 " Sport " 3 " Snow_Nex " 4 " Reserved " 5 " Deep Mud " 6 " Reserved " 7 " Soft sand " 8 " Reserved " 9 " 4L（reserved） " 10 " Economic " 11 " Reserved " 12 " Snow_TOD（reserved) " 13 " Off road " 14 " Sport+(reserved) " 15 " nvalid Value " 16 " Standard_2H(reserved) " 17 " Reserved " 18 " Standard_4H(reserved) " 19 " Snow_4H(reserved) " 20 " Normal_4L(reserved) " 21 " Rock_4L(reserved) " 22 " Pothole_4L(reserved) " 23 " Mud/Sand_4L(reserved) " 24 " Mountain_4L(reserved) " 25 " Reserved " ;
VAL_ 325 TAB_Available 0 " TAB not available " 1 " TAB available " ;
VAL_ 325 TAB_Sts 0 " Function OFF " 1 " Standby " 2 " Active " 3 " Failure " ;
VAL_ 325 RollingCounter_ESP2_ 0 " Valid value " 15 " Invalid value " ;
VAL_ 327 CheckSum_EPS1 0 " Valid values " ;
VAL_ 327 EPS_FailSts 0 " No fault " 1 " Permanent Error Detected " 2 " Intermittent Error Detected " 3 " Reserved " ;
VAL_ 327 EPS_TrqSnsrSts 0 " Normal " 1 " Abnormal " ;
VAL_ 327 EPS_SteerMod 0 " Comfort Mode " 1 " sport mode  " 2 " Handiness Mode " 3 " Reserved " ;
VAL_ 327 RollingCounter_EPS1 0 " Valid value " 15 " Invalid value " ;
VAL_ 327 EPS_LKATorqOvrlDlvd 0 " Valid value " 3001 " Reserved " ;
VAL_ 327 EPS_LKATorqOvrlDlvdVld 0 " Invalid " 1 " Valid " ;
VAL_ 327 EPS_LKATrqOvlDlvdSts 0 " Not active " 1 " Active " 2 " Temporary inhibit " 3 " Permanently failed " ;
VAL_ 329 CheckSum_ESP1_ 0 " Valid values " ;
VAL_ 329 ESPFuncOffSts_ 0 " Available/On " 1 " Unavailable/Off " ;
VAL_ 329 ESPActvInfoLmp_ 0 " Not active " 1 " Active " ;
VAL_ 329 ESPFailSts_ 0 " No failure " 1 " Failure " ;
VAL_ 329 RollingCounter_ESP1_ 0 " Valid value " 15 " Invalid value " ;
VAL_ 338 RearELDLckSts 0 " UnLocked " 1 " Locked " 2 " Over-Speed Warning " 3 " Driving Mode Select Error " 4 " Lock Request Deny " 5 " Reserved " 14 " Fault " 15 " Invalid " ;
VAL_ 347 APS_PrkgMod 0 " None " 1 " Parking in " 2 " Parking out " 3 " Reserved " ;
VAL_ 347 APS_ProcBar 0 " 0-100 " 101 " Reserved " 127 " No Display " ;
VAL_ 347 APS_SwtSts 0 " no press " 1 " press " ;
VAL_ 347 APS_SlotDisp 0 " No parking slot " 1 " Left parallel parking slot " 2 " Left vertical parking slot " 3 " Left T-shape parking slot " 4 " Right parallel parking slot " 5 " Right vertical parking slot " 6 " Right T-shape parking slot " 7 " Reserved " ;
VAL_ 347 APS_SysSoundIndcn 0 " Tone 0 - No Warning " 1 " Tone 1 - APS failed tone " 2 " Tone 2 - APS successful tone " 3 " Tone 3 - APS warning tone " 4 " Tone 4 - APS request tone " 5 " Reserved " ;
VAL_ 347 APS_PrkgTyp 0 " None " 1 " Parallel parking " 2 " Vertical parking " 3 " Reserved " ;
VAL_ 347 APS_TextDisp 0 " No Request " 1 " Wrong gear position to start parking " 2 " Turn D to search for slot " 3 " Please close the trunk " 4 " Please close the door " 5 " Please fasten the seat belt " 6 " Please unfold the Mirror " 7 " Speed is too high, need <23km/h " 8 " System error Parking sys exits " 9 " control unit error parking sys exits " 10 " Please brake " 11 " please select parking mode " 12 " please select internal parking " 13 " please select Slot and parking mode " 14 " please select Slot and internal parking " 15 " Please keep braking " 16 " Hands off the steering wheel " 17 " Release the brake, parking start " 18 " Auto parking, be ready to brake " 19 " parking suspended,close trunk " 20 " parking suspended, close door  " 21 " parking suspended, fasten seat belt " 22 " Obstacles Detected " 23 " brake recovered, confirm to continue " 24 " Parking quited " 25 " parking   finished " 26 " interfered by driver parking quited " 27 " too many parking times parking sys exits " 28 " Parking time too long Parking sys exits " 29 " Too Small Slot Parking sys exits " 30 " Please Clean the Camera " 31 " Select the parking mode(APA3) " 32 " Searching the right slot " 33 " Searching the left slot " 34 " Please turn D to search for parking slot " 35 " Speed is too high, need <30km/h " 36 " Speed is too high,sys exits " 37 " Select parking type " 38 " Long press switch 2s to enter auto parking " 39 " Parking suspended, Please release the gas pedal " 40 " Please brake, And long press switch 2s to continue auto parking " 41 " Parking is not available " 42 " Please select the parking direction by turning the turn switch " 43 " Please brake， And long press switch 2s to enter_POC_left " 44 " Parking sys exits " 45 " Parking suspended, fold the Mirror " 46 " Too Small Slot Please select another direction " 47 " Driving Mode not supported " 48 " Path is smooth " 49 " Please select park out " 50 " Please select park out direction " 51 " Please get off the car with keys to start remote parking " 52 " Please confirm to start parking " 53 " Remote Parking in exit " 54 " Parking suspended,Remote connection error " 55 " System error, Parking sys can not start " 56 " Control unit error, Parking sys can not start " 57 " Please Turn P and Apply EPB Remote parking sys not Running " 58 " Select Remote parking out type " 59 " Please brake,And long press switch 2s to enter_POC_Right " 60 " Please release switch to en-ter guidance " 61 " Slope over ,system exits " 62 " Reserved " 64 " Path study begin please drive the car " 65 " Path studying " 66 " Confirm study finished " 67 " Path studying failed caused by Path too long " 68 " Path studying failed caused by Speed too high " 69 " Path studying failed caused by communication error " 70 " Path studying failed caused by Path error " 71 " Path studying failed caused by learn time too long " 72 " Path studying failed caused by internal error " 73 " Reserved " 80 " Path saving " 81 " Path saving Succeed " 82 " Path saving failed caused by Path too short " 83 " Path saving failed caused by communication error " 84 " Path saving failed caused by Path error " 85 " Path saving failed caused by Path error limit storage room " 86 " Path saving failed caused by internal error " 87 " Reserved " 96 " Please drive to path start point " 97 " Path matche please stop " 98 " Please select play back mode " 99 " Path match failed caused by communication error " 100 " Path match failed caused by path error " 101 " Path match failed caused by long time no action " 102 " Path match failed caused by internal error " 103 " Reserved " 112 " No save distance，RADS sys esits " 113 " RADS running, be ready to brake " 114 " Near the bourn " 115 " Arrive at the bourn " 116 " Release the brake " 117 " Trunk open, RADS sys exits " 118 " Door open, RADS sys exits " 119 " Seat belt drop, RADS sys exits " 120 " Mirror fold, RADS sys exits " 121 " Obstacles Detected, RADS sys exits " 122 " No continue driving Parking quited " 123 " Please turn to R " 124 " Release the brake, Driving assistance start " 125 " Please turn to D " 126 " Reserved for RADS " 128 " Reserved " ;
VAL_ 347 APS_WorkSts 0 " Disable " 1 " Standby " 2 " Searching " 3 " Guidance " 4 " Failed " 5 " Wait for Engine restart " 6 " Reserved " ;
VAL_ 347 MEB_AVHReq 0 " No Request " 1 " Request " ;
VAL_ 347 LParaPrkgOutVald 0 " valid " 1 " Invalid " ;
VAL_ 347 RParaPrkgOutVald 0 " valid " 1 " Invalid " ;
VAL_ 347 HeadVertPrkgOutVald 0 " valid " 1 " Invalid " ;
VAL_ 347 TailVertPrkgOutVald 0 " valid " 1 " Invalid " ;
VAL_ 347 HAP_SwtDispCtrlCmd 0 " no display " 1 " park out direction Select menu " 2 " continue park menu " 3 " Study finish button " 4 " RDAS distance arrow " 5 " RDAS active distance arrow steering " 6 " Reserved " ;
VAL_ 347 P2P_PahDelSts 0 " No Action " 1 " deleting " 2 " successed " 3 " failed " ;
VAL_ 347 P2P_SelfDetErrCode 0 " No Error " 1 " HAP Error " 2 " tyre pressure error " 3 " door open  " 4 " trunk open " 5 " vehicle moving " 6 " environment error " 7 " Camera is smudgy " 8 " Seat belt not fastened " 9 " Mirror is folded " 10 " reserved " ;
VAL_ 347 P2P_SelfDetSts 0 " No Action " 1 " Detecting " 2 " Successed " 3 " Failed " ;
VAL_ 347 P2P_Pah1Avail 0 " Not avalible " 1 " Avalible " ;
VAL_ 347 P2P_Pah2Avail 0 " Not avalible " 1 " Avalible " ;
VAL_ 347 HAP_PrkgModCurrSts 0 " No display " 1 " Left parallel park in " 2 " Right parallel park in " 3 " Left vert park in " 4 " Right vert park in " 5 " Left Tshape park in " 6 " Right Tshape park in " 7 " Left parallel park out " 8 " Right parallel park out " 9 " Front vert park out " 10 " Rear vert park out " 11 " reserved " ;
VAL_ 347 APS_MovgDirc 0 " No Display " 1 " Moving forward " 2 " Moving backward " 3 " Reserved  " ;
VAL_ 357 LTurnLmpSwtSts 0 " OFF " 1 " ON " ;
VAL_ 357 RTurnLmpSwtSts 0 " OFF " 1 " ON " ;
VAL_ 357 AutoLmpSwtSts 0 " Non-Auto " 1 " Auto " ;
VAL_ 357 HornSwtSts 0 " OFF " 1 " ON " ;
VAL_ 360 EPS_FailSts_ 0 " No fault " 1 " Permanent Error Detected " 2 " Intermittent Error Detected " 3 " Reserved " ;
VAL_ 360 CheckSum_EPS1_ 0 " Valid values " ;
VAL_ 360 EPS_SteerMod_ 0 " Comfort Mode " 1 " sport mode  " 2 " Handiness Mode " 3 " Reserved " ;
VAL_ 360 RollingCounter_EPS1_ 0 " Valid value " 15 " Invalid value " ;
VAL_ 363 CheckSum_EPB1 0 " Valid values " ;
VAL_ 363 PressBrakePedalPointOut 0 " No reminder " 1 " Pedal needs to be applied " ;
VAL_ 363 EPBErrSts 0 " Undefined " 1 " No Error " 2 " Error " 3 " Diagnosis " ;
VAL_ 363 EPBSts 0 " Released " 1 " Closed " 2 " In progress " 3 " unknown " ;
VAL_ 363 EPBTextDisp 0 " No display " 1 " Gradient too high " 2 " Park brake force not enough " 3 " Park brake system overheated " 4 " Remind driver to apply safety belt " 5 " Park brake maintenance mode " 6 " Roller bench mode " 7 " Please Release EPB " 8 " Please Release Rear ELD " 9 " Reserved " ;
VAL_ 363 EPBRedLmpSts 0 " Lamp off " 1 " Lamp on " 2 " Lamp flash " 3 " Reserved " ;
VAL_ 363 RollingCounter_EPB1 0 " Valid value " 15 " Invalid value " ;
VAL_ 367 RSDS_IPSoundReq 0 " No warning " 1 " Warning level 1（2Hz声音） " 2 " Warning level 2（4Hz声音） " 3 " Warning level 3（常响） " ;
VAL_ 367 RSDS_ErrSts 0 " No Error " 1 " Error " ;
VAL_ 367 RSDS_BrkgTrig 0 " Not tirggered " 1 " Triggered " ;
VAL_ 367 RSDS_BliSts 0 " No Blindness " 1 " Blindness " ;
VAL_ 367 RSDS_TrailerSts 0 " None " 1 " Trailer " ;
VAL_ 367 RSDS_LCAResp 0 " OFF " 1 " ON " ;
VAL_ 367 RSDS_DOWResp 0 " OFF " 1 " ON " ;
VAL_ 367 RSDS_RCWResp 0 " OFF " 1 " ON " ;
VAL_ 367 RSDS_RCTAResp 0 " OFF " 1 " ON " ;
VAL_ 367 RSDS_RCTABrkResp 0 " OFF " 1 " ON " ;
VAL_ 367 RSDS_RCW_Trigger 0 " No warning " 1 " RCW level 1 " 2 " RCW level 2 " 3 " Reserved " ;
VAL_ 367 RSDS_CTA_Actv 0 " Not active " 1 " Active " ;
VAL_ 368 CCO_Active 0 " Not Active " 1 " Active " 2 " Stand by " 3 " Failed " ;
VAL_ 368 CCO_TgtVel 0 " Valid values " ;
VAL_ 368 CCO_Warn 0 " No Warn " 1 " Please Release EPB " 2 " Please  slow down " 3 " Reserved " ;
VAL_ 368 EspFuncOffSts_mode 0 " Available/On " 1 " Cross-country expert mode " ;
VAL_ 395 AEB_ObjSty 0 " No Object " 1 " Vehicle " 2 " Pedestrian " 3 " Cyclist " 4 " Unknown " 5 " Resvered " ;
VAL_ 407 HCU_IntelEngIdlChrgnSts 0 " Default " 1 " Idle charging " 2 " Fail to Idle charging " 3 " Idle charging shut off " 4 " Idle charging is complete " 5 " Reserved " ;
VAL_ 411 FFogLmpSts_F_Pbox 0 " Off " 1 " On " ;
VAL_ 411 HiBeamSts_F_Pbox 0 " Off " 1 " On " ;
VAL_ 411 HoodSts_F_Pbox 0 " Closed " 1 " Open " ;
VAL_ 411 LLasHdLmpDiagSig 0 " No failure " 1 " failure " ;
VAL_ 411 RLasHdLmpDiagSig 0 " No failure " 1 " failure " ;
VAL_ 411 LasHdLmpSts_F_Pbox 0 " Off " 1 " On " ;
VAL_ 411 LHiBeamFailSts 0 " No failure " 1 " failure " ;
VAL_ 411 RHiBeamFailSts 0 " No failure " 1 " failure " ;
VAL_ 411 LLowBeamFailSts 0 " No failure " 1 " failure " ;
VAL_ 411 RLowBeamFailSts 0 " No failure " 1 " failure " ;
VAL_ 411 LHeadLmpFailSts 0 " No failure " 1 " failure " ;
VAL_ 411 RHeadLmpFailSts 0 " No failure " 1 " failure " ;
VAL_ 412 HiPosnBrkLmpFailSts 0 " No failure " 1 " failure " ;
VAL_ 412 LicPlateLmpFailSts 0 " No failure " 1 " failure " ;
VAL_ 412 LBrkLmpFailSts 0 " No failure " 1 " failure " ;
VAL_ 412 RFogLmpFailSts_R_Pbox 0 " No failure " 1 " failure " ;
VAL_ 412 RFogLmpSts_R_Pbox 0 " Off " 1 " On " ;
VAL_ 412 ParkLmpSts_R_Pbox 0 " Off " 1 " On " ;
VAL_ 412 RBrkLmpFailSts 0 " No failure " 1 " failure " ;
VAL_ 412 PosnLmpOutpSts_R_Pbox 0 " OFF " 1 " ON " ;
VAL_ 412 RRPosnLmpFailSts 0 " No failure " 1 " failure " ;
VAL_ 412 RvsLmpFailSts 0 " No failure " 1 " failure " ;
VAL_ 412 LRPosnLmpFailSts 0 " No failure " 1 " failure " ;
VAL_ 412 RTurnLmpFailSts 0 " No failure " 1 " Short circuit " 2 " Open circuit " 3 " Reserved " ;
VAL_ 412 LTurnLmpFailSts 0 " No failure " 1 " Short circuit " 2 " Open circuit " 3 " Reserved " ;
VAL_ 412 LTurnLmpSts_R_Pbox 0 " Off " 1 " On " ;
VAL_ 412 RTurnLmpSts_R_Pbox 0 " Off " 1 " On " ;
VAL_ 412 RWinHeatgIconRlyCmd 0 " Not active " 1 " Active " ;
VAL_ 412 RWinHeatgFailSts 0 " No Failure " 1 " Failure " ;
VAL_ 448 HCU_ChrgSysLmpSts 0 " OFF " 1 " Green Light ON " 2 " Red Light ON " 3 " Yellow Light with slanting line " 4 " Red Light with slanting line " 5 " Reserved " ;
VAL_ 448 HCU_ChrgSysErr_1 0 " Not indicate " 1 " Indicate " ;
VAL_ 448 HCU_ChrgSysErr_2 0 " Not indicate " 1 " Indicate " ;
VAL_ 448 HCU_ChrgSysErr_3 0 " Not indicate " 1 " Indicate " ;
VAL_ 448 HCU_ChrgSysErr_4 0 " Not indicate " 1 " Indicate " ;
VAL_ 448 HCU_ChrgSysErr_5 0 " Not indicate " 1 " Indicate " ;
VAL_ 448 HCU_ChrgSysErr_6 0 " Not indicate " 1 " Indicate " ;
VAL_ 448 HCU_ChrgSysErr_7 0 " Not indicate " 1 " Indicate " ;
VAL_ 448 HCU_ChrgSysErr_8 0 " Not indicate " 1 " Indicate " ;
VAL_ 481 T_Box_BMSReMtPreHeatT 0 " Default " 1 " Valid values " 1441 " Reserved " ;
VAL_ 481 Phone_ChrgnMode 0 " Immediate Charging " 1 " Delay Charging " 2 " Invalid " 3 " No action " ;
VAL_ 481 T_Box_IntelEngIdlChrgnSwt 0 " Default " 1 " ON " 2 " Off " 3 " Reserved " ;
VAL_ 481 T_Box_BattKeepTemp 0 " Default " 1 " ON " 2 " Off " 3 " Reserved " ;
VAL_ 481 T_Box_RemtFrntDefrostCtrl 0 " No action " 1 " Off " 2 " On " 3 " Reserved " ;
VAL_ 481 T_Box_RemtRearDefrostCtrl 0 " No action " 1 " Off " 2 " On " 3 " Reserved " ;
VAL_ 481 TBOX_RemtVideoMonrEnaReq_APP 0 " No action " 1 " Disable " 2 " Enable " 3 " Reserved " ;
VAL_ 481 T_Box_RemtCockpitClnReq 0 " no action " 1 " open " 2 " close " 3 " reserved " ;
VAL_ 481 T_Box_RemtSdlMod 0 " Charging " 1 " AC ON " 2 " Intelligent Engine Idle Charging start " 3 " No action " ;
VAL_ 482 HCU_PhoneChrgnModeResp 0 " inactive " 1 " active " ;
VAL_ 482 HCU_PhoneChrgnReqResp 0 " inactive " 1 " active " ;
VAL_ 482 HCU_HUTChrgnModeResp 0 " inactive " 1 " active " ;
VAL_ 482 HCU_HUTChrgnReqResp 0 " inactive " 1 " active " ;
VAL_ 482 HCU_TboxEngStrtReq 0 " NO Request " 1 " Request " ;
VAL_ 482 HCU_TotalScore 0 " Valid value " 6 " Reserved " ;
VAL_ 482 HCU_IntelBattTempMagResp 0 " inactive " 1 " active " ;
VAL_ 482 HCU_RemtVehStartReq 0 " No Request " 1 " Request " ;
VAL_ 483 BMS_BattKeepTempResp_PHEV 0 " Immediate Charging " 1 " Delay Charging " 2 " Invalid " 3 " No action " ;
VAL_ 489 BackReq_AVM 0 " No request " 1 " Request " ;
VAL_ 489 HUD_HeightLvlSwt 0 " No action " 1 " Level 1_Low " 2 " Level 2 " 3 " Level 3 " 4 " Level 4 " 5 " Level 5  " 6 " Level 6 " 7 " Level 7 " 8 " Level 8  " 9 " Level 9 " 10 " Level 10 " 11 " Level 11_Middle " 12 " Level 12 " 13 " Level 13 " 14 " Level 14 " 15 " Level 15 " 16 " Level 16 " 17 " Level 17 " 18 " Level 18 " 19 " Level 19 " 20 " Level 20 " 21 " Level 21_High " 22 " Reserved " ;
VAL_ 489 HUD_BrightnessLvlSwt 0 " No action " 1 " Level 1_Low " 2 " Level 2 " 3 " Level 3 " 4 " Level 4 " 5 " Level 5_Middle " 6 " Level 6 " 7 " Level 7 " 8 " Level 8 " 9 " Level 9_High " 10 " Reserved " ;
VAL_ 489 HUD_SwtReq 0 " No action " 1 " OFF  " 2 " ON " 3 " Reserved   " ;
VAL_ 489 ExprsnSetUp 0 " No action " 1 " Disable " 2 " Enable " 3 " Reserved " ;
VAL_ 489 DistrctnDetnSet 0 " No action " 1 " Disable " 2 " Enable " 3 " Reserved " ;
VAL_ 489 DrowsnsDetnSet 0 " No action " 1 " Disable " 2 " Enable " 3 " Reserved " ;
VAL_ 489 FaceIdnSet 0 " No action " 1 " Disable " 2 " Enable " 3 " Reserved " ;
VAL_ 489 VoiceIdnSet 0 " No action " 1 " Disable " 2 " Enable " 3 " Reserved " ;
VAL_ 489 EraseAllFaceUsersReq 0 " No action " 1 " Disable " 2 " Enable " 3 " Reserved " ;
VAL_ 489 EraseAllVoiceUsersReq 0 " No action " 1 " Disable " 2 " Enable " 3 " Reserved " ;
VAL_ 489 CancelVoiceIdn 0 " No action " 1 " No " 2 " Yes " 3 " Reserved " ;
VAL_ 489 EnrollFaceReq 0 " No action " 1 " Request enrolling face " 2 " Request cancel enrolling face " 3 " Reserved " ;
VAL_ 489 EnrollUserIDResult 0 " Reserved " 1 " Enroll user ID face sucessflly " 7 " Reserved " 15 " Invalid " ;
VAL_ 489 DeleteUserIDFaceData 0 " Reserved " 1 " User ID " 7 " Reserved " 15 " Invalid " ;
VAL_ 489 DeleteUserIDVoiceData 0 " Reserved " 1 " User ID " 7 " Reserved " 15 " Invalid " ;
VAL_ 493 MbrMonrEnReq_TC 0 " No action " 1 " Disable " 2 " Enable " 3 " Reserved " ;
VAL_ 493 ApproachLampSet 0 " No action " 1 " OFF " 2 " ON " 3 " Reserved " ;
VAL_ 493 FlaoutUnlockSet 0 " No action " 1 " OFF " 2 " ON " 3 " Reserved " ;
VAL_ 493 SuperLockSet 0 " No action " 1 " OFF " 2 " ON " 3 " Reserved " ;
VAL_ 493 PrkInDirChoice 0 " None " 1 " Tail in " 2 " Head in  " 3 " Reserved " ;
VAL_ 493 PathLrngFinshCmd 0 " No request " 1 " Request " ;
VAL_ 493 PathLrngStartCmd 0 " No request " 1 " Request " ;
VAL_ 493 SelPrkOutDirReq 0 " No selection " 1 " Park out front/vertical head out " 2 " Park out rear/vertical tail out " 3 " Park out left/parallel left out  " 4 " Park out right/parallel right out " 5 " Reserved " ;
VAL_ 493 ParkMdlCmd 0 " No request " 1 " Request " ;
VAL_ 493 BackReq_APS 0 " No request " 1 " Request " ;
VAL_ 493 StartPrkgPath2Cmd 0 " No request " 1 " Request " ;
VAL_ 493 DeletePath2Cmd 0 " No request " 1 " Request " ;
VAL_ 493 StartPrkgPath1Cmd 0 " No request " 1 " Request " ;
VAL_ 493 DeletePath1Cmd 0 " No request " 1 " Request " ;
VAL_ 493 SelPrkgFctnCmd 0 " No selection " 1 " Select APA parking " 2 " Select P2P parking " 3 " Select Explore Forward " 4 " Select drive back " 5 " Reserved " ;
VAL_ 493 RLWinSwtReq_VR 0 " No action " 1 " Close " 2 " Open " 3 " Half_Open " 4 " 5%_Up " 5 " 5%_Down " 6 " 1/3_Open " 7 " Reserved " ;
VAL_ 493 RRWinSwtReq_VR 0 " No action " 1 " Close " 2 " Open " 3 " Half_Open " 4 " 5%_Up " 5 " 5%_Down " 6 " 1/3_Open " 7 " Reserved " ;
VAL_ 493 DrvWinSwtReq_VR 0 " No action " 1 " Close " 2 " Open " 3 " Half_Open " 4 " 5%_Up " 5 " 5%_Down " 6 " 1/3_Open " 7 " Reserved " ;
VAL_ 493 PassWinSwtReq_VR 0 " No action " 1 " Close " 2 " Open " 3 " Half_Open " 4 " 5%_Up " 5 " 5%_Down " 6 " 1/3_Open " 7 " Reserved " ;
VAL_ 494 ACOperMod_TC 0 " No action " 1 " Standard Mode " 2 " Comfort Mode " 3 " Strong Mode " ;
VAL_ 494 ACOperMod_VR 0 " No action " 1 " Standard Mode " 2 " Comfort Mode " 3 " Strong Mode " ;
VAL_ 494 SteerWheelHeatSwtReq 0 " No action " 1 " No request " 2 " Request " 3 " Reserved " ;
VAL_ 494 ACDrvSetTempSteplsReq_TC 0 " No action " 1 " Low " 2 " Valid value " 33 " High " 34 " Reserved " ;
VAL_ 494 ACPassSetTempSteplsReq_TC 0 " No action " 1 " Low " 2 " Valid value " 33 " High " 34 " Reserved " ;
VAL_ 494 SDWSwtSet 0 " No Request " 1 " Request " ;
VAL_ 494 APSSwtReq_VR 0 " No action " 1 " off " 2 " on " 3 " Reserved " ;
VAL_ 494 PASExitSpdSwt 0 " No command " 1 " 15km/h " 2 " 30km/h " 3 " Reserved " ;
VAL_ 494 APSPrkgTypSeln 0 " No Select " 1 " Select parallel parking " 2 " Select vertical parking " 3 " Reserved " ;
VAL_ 494 SunShadeSwtReq_VR 0 " No action " 1 " Full closed " 2 " 10% " 3 " 20% " 4 " 30% " 5 " 40% " 6 " 50% " 7 " 60% " 8 " 70% " 9 " 80% " 10 " 90% " 11 " full open " 12 " stop " 13 " reserved " ;
VAL_ 494 SunRoofSwtReq_VR 0 " No action " 1 " Full closed " 2 " Tilt Up " 3 " 10% " 4 " 20% " 5 " 30% " 6 " 40% " 7 " 50% " 8 " 60% " 9 " 70% " 10 " 80% " 11 " 90% " 12 " full open " 13 " stop " 14 " reserved " ;
VAL_ 494 SportModLightSet 0 " OFF " 1 " Flashing&Light " 2 " Reserved " 3 " Reserved " ;
VAL_ 494 ABSLmpSet 0 " OFF " 1 " ON " ;
VAL_ 494 AutoWshWipSet 0 " short time 300ms " 1 " middle time 500ms " 2 " long time 800ms " 3 " Reserved " ;
VAL_ 494 SeekVehSet 0 " Horn&Light " 1 " HornOnly " 2 " LightOnly " 3 " Reserved " ;
VAL_ 494 SpdAutoLockModSet 0 " OFF " 1 " 8km/h " 2 " 15km/h " 3 " Reserved " ;
VAL_ 494 ParkLmpSet 0 " OFF " 1 " ON " ;
VAL_ 494 DoorUnlockModSet 0 " All Door " 1 " Driver Door " ;
VAL_ 494 ACEAHReq_TC 0 " No action " 1 " Pressed " ;
VAL_ 494 ACEAHReq_VR 0 " No action " 1 " Not active " 2 " Active " 3 " Reserved " ;
VAL_ 513 HCU_PrsBrkWarn 0 " No warning " 1 " Press brake and Unlock-button to shift " 2 " Press Unlock-button to shift " 3 " Press brake to shift " ;
VAL_ 513 DrvModDisp_ 0 " P                           " 1 " R                                    " 2 " N                                                 " 3 " D                                             " 4 " M                                        " 5 " Reserved  " ;
VAL_ 513 DrvModDispSts_ 0 " Blank/No Display                            " 1 " On                               " 2 " Flashing                                         " 3 " Reserved(treat as Blank/No Display) " ;
VAL_ 513 DrvGearDisp 0 " Neutral " 1 " 1st Gear " 2 " 2nd Gear " 3 " Reserved " ;
VAL_ 513 DrvGearDispSts_ 0 " Blank / No display " 1 " On " 2 " Flashing " 3 " Reserved (treat as Blank/No display) " ;
VAL_ 513 HCU_ShftNotAlwd_Warn 0 " No warning " 1 " Vehicle speed too high, shift not allowed " 2 " Engage P not allowed due to high vehicle speed " 3 " reserved " ;
VAL_ 513 DrvFaiMsg_ 0 " No Message    " 1 " Transmission Malfunction " 2 " Transmission P engagement fault " 3 " Transmission P disengagement fault " 4 " Reserved  " 15 " Transmission limit function " ;
VAL_ 543 STBS_SoundReq 0 " No Request " 1 " Request " ;
VAL_ 543 VolUpReq_SC 0 " Released " 1 " Pressed " 2 " Error " 3 " Invalid " ;
VAL_ 543 VolDwnReq_SC 0 " Released " 1 " Pressed " 2 " Error " 3 " Invalid " ;
VAL_ 543 DispTODReq_SC 0 " Released " 1 " Pressed " 2 " Error " 3 " Invalid " ;
VAL_ 545 CurrentGearValid 0 " Invalid  " 1 " Valid " ;
VAL_ 545 CURRENT_GEAR 0 " Current gear -N- or -P- " 1 " Current gear -1- " 2 " Current gear -2- " 3 " Current gear -3- " 4 " Current gear -4- " 5 " Current gear -5- " 6 " Current gear -6- " 7 " Current gear -7- " 8 " Current gear -R- " 9 " Reserved " ;
VAL_ 545 TGS_LEVER 0 " Select lever in position -P- " 1 " Reserved " 2 " Reserved " 3 " Reserved " 4 " Reserved " 5 " Select lever in position -D- " 6 " Select lever in position -N- " 7 " Select lever in position -R- " 8 " Select lever in position -M- " 9 " Reserved " 14 " Intermediate position " 15 " Invalid  " ;
VAL_ 545 SHIFT_IN_PROGRESS 0 " Gear Shift NOT in progress. " 1 " Gear Shif is in progress " ;
VAL_ 545 ShiftInPrgValid 0 " Invalid  " 1 " Valid " ;
VAL_ 551 Checksum_AEB2 0 " Valid value " ;
VAL_ 551 AEB_PedResp 0 " OFF " 1 " ON " ;
VAL_ 551 AEB_VehResp 0 " OFF " 1 " ON " ;
VAL_ 551 FCW_Snvty 0 " Normal " 1 " High sensitivity " 2 " Low sensitivity " 3 " Reserved " ;
VAL_ 551 AEB_JA_Resp 0 " OFF " 1 " ON " ;
VAL_ 551 RollingCounter_AEB2 0 " Valid value " 15 " Invalid value " ;
VAL_ 551 Checksum_AEB3 0 " Valid value " ;
VAL_ 551 AEB_VehTrig 0 " not tirggered " 1 " triggered " ;
VAL_ 551 AEB_PedTrig 0 " not tirggered " 1 " triggered " ;
VAL_ 551 FCW_AEB_VehFctSts 0 " No display  " 1 " error  " 2 " FCW/AEB_V temporarily unavailable " 3 " FCW/AEB_V Performance degradation " ;
VAL_ 551 FCW_AEB_PedFctSts 0 " No display " 1 " error " 2 " FCW/AEB_P temporarily unavailable " 3 " FCW/AEB_P Performance degradation " ;
VAL_ 551 FCW_Warn 0 " No warning " 1 " Latent warning  " 2 " warning Level 1   " 3 " warning Level 2 " ;
VAL_ 551 AEB_JAFuncSts 0 " No display " 1 " error " 2 " FCW/AEB_JA temporarily unavailable " 3 " FCW/AEB_JA Performance degradation " ;
VAL_ 551 AEB_JA_Warn 0 " No warning " 1 " Warning  for vehicle " 2 " Warning for pedestrian " 3 " reverse " ;
VAL_ 551 AEB_JABrkTrig 0 " Not tirggered " 1 " AEB_JA Function Triggered for vehicle " 2 " AEB_JA Function Triggered for pedestrian " 3 " reverse " ;
VAL_ 551 RollingCounter_AEB3 0 " Valid value " 15 " Invalid value " ;
VAL_ 561 FLWheelSpdVld 0 " Invalid " 1 " Valid " ;
VAL_ 561 FLWheelSpd 0 " Valid values " 5334 " Reserved " ;
VAL_ 561 FRWheelSpdVld 0 " Invalid " 1 " Valid " ;
VAL_ 561 FRWheelSpd 0 " Valid values " 5334 " Reserved " ;
VAL_ 565 CheckSum_DCT7 0 " Valid values " ;
VAL_ 565 DCT_RaceModeSts 0 " Inactive                           " 1 " Active                                   " 2 " Turn Off                                            " 3 " Forbidden                                                                                  " 4 " Reserved (treat as 0x0 inactive) " ;
VAL_ 565 DCT_PrsBrk_Warn 0 " No warning " 1 " Press brake and Unlock-button to shift " 2 " Press Unlock-button to shift " 3 " Press brake to shift " ;
VAL_ 565 DCT_ShftNotAlwd_Warn 0 " No warning " 1 " Vehicle speed too high, shift not allowed " 2 " Engage P not allowed due to high vehicle speed " 3 " Transmission is in N, park-lock is not locked " ;
VAL_ 565 DCT_ShftRecom_M 0 " No Recommendation " 1 " Up Shift " 2 " Down Shift " 3 " Reserved " ;
VAL_ 565 DrvWarnMsg 0 " No Text  " 1 " PressBrake " 2 " TransToo_Hot " 3 " Reserved " ;
VAL_ 565 DrvFaiMsg 0 " No Message " 1 " Transmission Malfunction  " 2 " Transmission P engagement fault " 3 " Transmission P disengagement fault " 4 " Authentication failure " 5 " Reserved  " 15 " transmission limit function " ;
VAL_ 565 DrvModDisp 0 " P " 1 " R " 2 " N " 3 " D " 4 " M " 5 " Reserved  " ;
VAL_ 565 DrvModDispSts 0 " Blank/No Display " 1 " On " 2 " Flashing " 3 " Reserved(treat as Blank/No Display) " ;
VAL_ 565 DrvAutoGearDisp 0 " Neutral " 1 " 1st Gear " 2 " 2nd Gear " 3 " 3rd Gear " 4 " 4th Gear " 5 " 5th Gear " 6 " 6th Gear " 7 " 7th Gear " 8 " Reserved  " ;
VAL_ 565 DrvGearDispSts 0 " Blank / No display " 1 " On " 2 " Flashing " 3 " Reserved (treat as Blank/No display) " ;
VAL_ 565 RollingCounter_DCT7 0 " Valid value " 15 " Invalid value " ;
VAL_ 568 SrAntiPinch 0 " Not active " 1 " Active " ;
VAL_ 568 SsPosn_VR_APP 0 " Fully close " 1 " reserved " 10 " 10% " 11 " reserved " 20 " 20% " 21 " reserved " 30 " 30% " 31 " reserved " 40 " 40% " 41 " reserved " 50 " 50% " 51 " reserved " 60 " 60% " 61 " reserved " 70 " 70% " 71 " reserved " 80 " 80% " 81 " reserved " 90 " 90% " 91 " reserved " 100 " Fully open " 101 " Reserved " ;
VAL_ 568 SsAntiPinch 0 " Not active " 1 " Active " ;
VAL_ 568 SrPosn_VR_APP 0 " Tilt up " 1 " reserved " 10 " 10% " 11 " reserved " 20 " 20% " 21 " reserved " 30 " 30% " 31 " reserved " 40 " 40% " 41 " reserved " 50 " 50% " 51 " reserved " 60 " 60% " 61 " reserved " 70 " 70% " 71 " reserved " 80 " 80% " 81 " reserved " 90 " 90% " 91 " reserved " 100 " Fully open " 101 " Fully close " 102 " Vent area " 103 " reserved " ;
VAL_ 573 Checksum_IFC3 0 " Valid value " ;
VAL_ 573 LDWResp 0 " OFF " 1 " ON " ;
VAL_ 573 LKAResp 0 " OFF " 1 " ON " ;
VAL_ 573 LCKResp 0 " OFF " 1 " ON " ;
VAL_ 573 ELKResp 0 " OFF " 1 " ON " ;
VAL_ 573 LDW_LKA_Snvty 0 " Normal " 1 " High sensitivity " 2 " Low sensitivity " 3 " Reserved " ;
VAL_ 573 IFCHUTInterface 0 " No response " 1 " Response " ;
VAL_ 573 LSSWarnFormResp 0 " Voice " 1 " Haptic " 2 " Voice+Haptic " 3 " Reserved " ;
VAL_ 573 LSSResp 0 " OFF " 1 " ON " ;
VAL_ 573 IntelligentEvaResp 0 " OFF " 1 " ON " ;
VAL_ 573 ESS_Pedresp 0 " OFF " 1 " ON " ;
VAL_ 573 ESS_Vehresp 0 " OFF " 1 " ON " ;
VAL_ 573 RollingCounter_IFC3 0 " Valid value " 15 " Invalid value " ;
VAL_ 573 Checksum_IFC4 0 " Valid value " ;
VAL_ 573 IFCCalibrationSts 0 " Calibration Success " 1 " Calibration In Process " 2 " Calibration Failed " 3 " Reserved " ;
VAL_ 573 CameraBlockageSts 0 " Camera Not Blocked " 1 " Camera Blocked " ;
VAL_ 573 LDW_LKAWarn 0 " No LDW_LKA warning " 1 " LDW_LKA left warning " 2 " LDW_LKA right warning " 3 " Reserved " ;
VAL_ 573 LSSIntervention 0 " No warning and Intervention  " 1 " Left warning  " 2 " Right warning " 3 " Left Intervention  " 4 " Right Intervention  " 5 " Both Intervention  " 6 " Left warn only reminder " 7 " Right warn only reminder " ;
VAL_ 573 LSSFuncSts 0 " OFF " 1 " LDW on " 2 " LKA on " 3 " LCK ON " 4 " Reserved " ;
VAL_ 573 ELKMainState 0 " ELK-OFF(关闭) " 1 " ELK-Standby(开启) " 2 " ELK-Enable(已使能，不满足扭矩介入条件) " 3 " ELK-Road edge Active(道路边缘扭矩介入) " 4 " ELK-Oncoming Active（oncoming扭矩介入） " 5 " ELK-Overtaking Active（overtaking扭矩介入） " 6 " ELK-Failure " 7 " Reserved " ;
VAL_ 573 LaneAvailability 0 " Not Avaliable " 1 " Left Lane Marker Available " 2 " Right Lane Marker Available " 3 " Both Lane Markers Available " ;
VAL_ 573 TJA_FollowSts 0 " No Follow " 1 " Follow Vehicle " 2 " Reserved " ;
VAL_ 573 LSSErrSts 0 " No error " 1 " LDW error " 2 " LKA error " 3 " LCK error " 4 " ELK error " 5 " ESS error " 6 " Reserved  " ;
VAL_ 573 IFC_Handsoffwarn 0 " no warning " 1 " Level1 warning " 2 " Level2 warning " 3 " Level3 warning " 4 " Level4 warning " 5 " Level5 warning " 6 " Reserved " ;
VAL_ 573 RollingCounter_IFC4 0 " Valid value " 15 " Invalid value " ;
VAL_ 573 Checksum_IFC5 0 " Valid value " ;
VAL_ 573 IFC_LaneCurve 0 " Valid value " 4095 " Reserved " ;
VAL_ 573 IFC_LeLaneTyp 0 " No display " 1 " Solid lane " 2 " Dashed lane " 3 " Rode edge " 4 " Reserved " ;
VAL_ 573 IFC_RiLaneTyp 0 " No display " 1 " Solid lane " 2 " Dashed lane " 3 " Rode edge " 4 " Reserved " ;
VAL_ 573 IFC_NextLeLaneTyp 0 " No display " 1 " Solid lane " 2 " Dashed lane " 3 " Rode edge " 4 " Reserved " ;
VAL_ 573 IFC_NextRiLaneTyp 0 " No display " 1 " Solid lane " 2 " Dashed lane " 3 " Rode edge " 4 " Reserved " ;
VAL_ 573 IFC_LeLane_dy 0 " Valid value " 4095 " Invalid value " ;
VAL_ 573 IFC_RiLane_dy 0 " Valid value " 4095 " Invalid value " ;
VAL_ 573 RollingCounter_IFC5 0 " Valid value " 15 " Invalid value " ;
VAL_ 573 Checksum_IFC6 0 " Valid value " ;
VAL_ 573 IFC_NextLeLane_dy 0 " Valid value " 4095 " Invalid value " ;
VAL_ 573 IFC_NextRiLane_dy 0 " Valid value " 4095 " Invalid value " ;
VAL_ 573 RollingCounter_IFC6 0 " Valid value " 15 " Invalid value " ;
VAL_ 580 MenuReturnSwtSts 0 " Released " 1 " Pressed " 2 " error " 3 " invalidation " ;
VAL_ 580 HomeSwtSts 0 " Released " 1 " Pressed " 2 " error " 3 " invalidation " ;
VAL_ 580 MuteSwtSts 0 " Released " 1 " Pressed " 2 " Error " 3 " invalidation " ;
VAL_ 580 CustomSwtSts 0 " Released " 1 " Pressed " 2 " error " 3 " invalidation " ;
VAL_ 580 SteerWheelHeatdSts 0 " Not active " 1 " Active " ;
VAL_ 580 PageUpSwtSts 0 " Released " 1 " Pressed " 2 " error " 3 " invalid " ;
VAL_ 580 PageDwnSwtSts 0 " Released " 1 " Pressed " 2 " error " 3 " invalidation " ;
VAL_ 580 PageLSwtSts 0 " Released " 1 " Pressed " 2 " error " 3 " invalidation " ;
VAL_ 580 PageRSwtSts 0 " Released " 1 " Pressed " 2 " error " 3 " invalidation " ;
VAL_ 580 SeekUpSwtSts 0 " Released " 1 " Pressed " 2 " error " 3 " invalidation " ;
VAL_ 580 SeekDwnSwtSts 0 " Released " 1 " Pressed " 2 " error " 3 " invalidation " ;
VAL_ 580 AdjVolUpSwtSts 0 " Released " 1 " Pressed " 2 " error " 3 " invalidation " ;
VAL_ 580 AdjVolDwnSwtSts 0 " Released " 1 " Pressed " 2 " error " 3 " invalidation " ;
VAL_ 580 VRSwtSts 0 " Released " 1 " Pressed " 2 " error " 3 " invalidation " ;
VAL_ 580 PhoneSwtSts 0 " Released " 1 " Pressed " 2 " error " 3 " invalidation " ;
VAL_ 580 SoundSourceModSwtSts 0 " Released " 1 " Pressed " 2 " error " 3 " invalidation " ;
VAL_ 580 EnterSwtSts 0 " Released " 1 " Pressed " 2 " error " 3 " invalidation " ;
VAL_ 580 EnterSwtSts_Mmed 0 " Released " 1 " Pressed " 2 " error " 3 " invalidation " ;
VAL_ 580 CustomSwtSts_Mmed 0 " Released " 1 " Pressed " 2 " error " 3 " invalidation " ;
VAL_ 581 VehLgtAccel 0 " Valid Value " 44067 " Reserved " ;
VAL_ 582 RLWheelSpdVld 0 " Invalid " 1 " Valid " ;
VAL_ 582 RLWheelSpd 0 " Valid values " 5334 " Reserved " ;
VAL_ 582 RRWheelSpdVld 0 " Invalid " 1 " Valid " ;
VAL_ 582 RRWheelSpd 0 " Valid values " 5334 " Reserved " ;
VAL_ 584 HCU_HybSysErr_1 0 " Not indicate " 1 " Indicate " ;
VAL_ 584 HCU_HybSysErr_2 0 " Not indicate " 1 " Indicate " ;
VAL_ 584 HCU_HybSysErr_3 0 " Not indicate " 1 " Indicate " ;
VAL_ 584 HCU_HybSysErr_4 0 " Not indicate " 1 " Indicate " ;
VAL_ 584 HCU_HybSysErr_5 0 " Not indicate " 1 " Indicate " ;
VAL_ 584 HCU_HybSysErr_6 0 " Not indicate " 1 " Indicate " ;
VAL_ 584 HCU_HybSysErr_7 0 " Not indicate " 1 " Indicate " ;
VAL_ 584 HCU_12VSysErrLmpSts 0 " OFF " 1 " ON " ;
VAL_ 584 HCU_HybSysErrLmpSts 0 " OFF " 1 " Yellow Light ON " 2 " Red Light ON " 3 " Reserved " ;
VAL_ 584 HCU_PowerRedWarnLmpCmd 0 " Lamp off " 1 " Lamp on " ;
VAL_ 584 HCU_12VSysErr_1 0 " Not indicate " 1 " Indicate " ;
VAL_ 584 HCU_12VSysErr_2 0 " Not indicate " 1 " Indicate " ;
VAL_ 584 HCU_RdyLmpSts 0 " OFF " 1 " ON " ;
VAL_ 584 HCU_ModSwtFail 15 " ECO Mode not available " 0 " Default  " 1 " EV not available due to low battery charge  " 2 " EV not available due to temporary hybrid system limitations " 3 " SAVE not available due to temporary hybrid system limitations " 4 " AWD not available due to temporary hybrid system limitations " 5 " SPORT not available due to temporary hybrid system limitations " 6 " Manual gear change ,drive mode goes SPORT  " 7 " Manual gear change,only SPORT available " 8 " EV mode available " 9 " Snow not available due to temporary hybrid system limitations " 10 " Muddy not available due to temporary hybrid system limitations " 11 " Sand not available due to temporary hybrid system limitations " 12 " SPORT Plus Mode not available due to temporary hybrid system limitations " 13 " ECO Mode not available " 14 " 0x0F " ;
VAL_ 584 HCU_EnrgFlowInd 0 " Mode 0 Vehicle standstill " 1 " Engine running and BSG is a conventional generator " 2 " Engine Auto-stopped " 3 " Boost " 4 " Energy Recovery " 5 " E-Creep " 6 " pure engine drive " 7 " Reserved " ;
VAL_ 584 HCU_OPDSts 0 " Not active " 1 " Active " 2 " Abnormal quit " 3 " Cannot active " 4 " Have no OPD function " 5 " Reserved " ;
VAL_ 584 HCU_OPDLmpSts 0 " Off " 1 " On " ;
VAL_ 589 DrowsnsLvl 0 " No Drowsiness " 1 " Low level Drowsiness " 2 " Middle level Drowsiness " 3 " High level Drowsiness " 4 " Reserved " 7 " Invalid " ;
VAL_ 589 DrowsnsLvlQlty 0 " Valid value " 101 " Reserved " 127 " Invalid " ;
VAL_ 589 DMSProc 0 " FaceIdentification  " 1 " FaceEnrollment  " 2 " VoiceIdentification  " 3 " VoiceEnrollment  " 4 " DeleteFaceData  " 5 " DeleteVoiceDate  " 6 " Reserved " 7 " Invalid " ;
VAL_ 589 DMSProcResult 0 " Unknow " 1 " User ID1 " 2 " User ID2 " 3 " User ID3 " 4 " User ID4 " 5 " User ID5 " 6 " User ID6 " 7 " Reserved " 11 " Failed " 12 " Reserved " 15 " Invalid " ;
VAL_ 589 DMSProcSts 0 " OK " 1 " InProgress " 2 " NOK " 3 " Start " 4 " End " 5 " Moving head left and right " 6 " Reserved " 15 " Invalid " ;
VAL_ 589 DMSIdnResult 0 " Unknow " 1 " User ID1 " 2 " User ID2 " 3 " User ID3 " 4 " User ID4 " 5 " User ID5 " 6 " User ID6 " 7 " Reserved " 11 " Failed " 12 " Reserved " 15 " Invalid " ;
VAL_ 589 GenderSts 0 " Male " 1 " Female " 2 " Reserved " 3 " Invalid " ;
VAL_ 589 ExprsnSts 0 " No expression " 1 " Smile " 2 " Angry " 3 " Surprise " 4 " Sad " 5 " Reserved " 7 " Invalid " ;
VAL_ 589 GenderStsQlty 0 " Valid value " 101 " Reserved " 127 " Invalid " ;
VAL_ 589 ExprsnStsQlty 0 " Valid value " 101 " Reserved " 127 " Invalid " ;
VAL_ 589 DistrctnLvl_ACC 0 " No distraction " 1 " Low level distraction " 2 " Middle level distraction " 3 " Hi level distraction " 4 " Reserved " 7 " Invalid " ;
VAL_ 589 DistrctnLvlQlty_ACC 0 " Valid value " 101 " Reserved " 127 " Invalid " ;
VAL_ 589 DrowsnsLvl_ACC 0 " No Drowsiness " 1 " Low level Drowsiness " 2 " Middle level Drowsiness " 3 " Hi level Drowsiness " 4 " Reserved " 7 " Invalid " ;
VAL_ 589 DrowsnsLvlQlty_ACC 0 " Valid value " 101 " Reserved " 127 " Invalid " ;
VAL_ 589 DistrctnLvl 0 " No distraction " 1 " Low level distraction " 2 " Middle level distraction " 3 " High level distraction " 4 " Reserved " 7 " Invalid " ;
VAL_ 589 DistrctnLvlQlty 0 " Valid value " 101 " Reserved " 127 " Invalid " ;
VAL_ 589 HeadPosnX 0 " Valid value " 1501 " Reserved " 2047 " Invalid " ;
VAL_ 589 HeadPosnY 0 " Valid value " 1001 " Reserved " 2047 " Invalid " ;
VAL_ 589 HeadPosnZ 0 " Valid value " 1001 " Reserved " 2047 " Invalid " ;
VAL_ 589 HeadPosQlty 0 " Valid value " 101 " Reserved " 127 " Invalid " ;
VAL_ 589 GazePosnX 0 " Valid value " 1501 " Reserved " 2047 " Invalid " ;
VAL_ 589 GazePosnY 0 " Valid value " 1001 " Reserved " 2047 " Invalid " ;
VAL_ 589 GazePosnZ 0 " Valid value " 1001 " Reserved " 2047 " Invalid " ;
VAL_ 589 DMSSts 0 " Blindness " 1 " Error " 2 " Active " 3 " Not active " 4 " Reserved " 7 " Invalid " ;
VAL_ 589 HeadDetn 0 " No " 1 " Yes " ;
VAL_ 589 HeadYawAng 0 " Valid value " 151 " Reserved " 255 " Invalid " ;
VAL_ 589 HeadPitchAng 0 " Valid value " 71 " Reserved " 255 " Invalid " ;
VAL_ 589 HeadRollAng 0 " Valid value " 91 " Reserved " 255 " Invalid " ;
VAL_ 589 HeadRotAngQlty 0 " Valid value " 101 " Reserved " 127 " Invalid " ;
VAL_ 589 LEyeOpenSts 0 " No " 1 " Yes " 2 " Loss left eye " 3 " Invalid " ;
VAL_ 589 LEyeOpenStsQlty 0 " Valid value " 101 " Reserved " 127 " Invalid " ;
VAL_ 589 REyeOpenSts 0 " No " 1 " Yes " 2 " Loss right eye " 3 " Invalid " ;
VAL_ 589 REyeOpenStsQlty 0 " Valid value " 101 " Reserved " 127 " Invalid " ;
VAL_ 589 RobustGazeYawAng 0 " Valid value " 181 " Reserved " 255 " Invalid " ;
VAL_ 589 RobustGazePitchAng 0 " Valid value " 181 " Reserved " 255 " Invalid " ;
VAL_ 589 RobustGazeAngQlty 0 " Valid value " 101 " Reserved " 127 " Invalid " ;
VAL_ 593 DiagLmpReq 0 " Lamp is not being requested " 1 " Lamp is being requested " ;
VAL_ 593 CouplingThermWarning 0 " No coupling thermal failsafe " 1 " coupling thermal failsafe " ;
VAL_ 593 CouplingFaultSts 0 " Normal Operating Mode " 1 " Reduced coupling functionality " 2 " Temporary coupling failure " 3 " Permanent coupling failure " ;
VAL_ 593 EstimatedTorque 0 " Valid value " 12001 " Reserved " 65535 " Invalid " ;
VAL_ 613 CheckSum_ABS3_ 0 " Valid values " ;
VAL_ 613 ABSFailSts_ 0 " No failure " 1 " Failure " ;
VAL_ 613 EBDFailSts_ 0 " No failure " 1 " Failure " ;
VAL_ 613 VehSpdVld_ 0 " Invalid " 1 " Valid " ;
VAL_ 613 VehSpd_ 0 " Valid values " 5334 " Reserved " ;
VAL_ 613 VehOdoInfoSts_ 0 " Invalid " 1 " Valid " ;
VAL_ 613 VehOdoInfo_ 0 " Valid values " 1000 " Reserved " ;
VAL_ 613 ABSActv_ 0 " Not active " 1 " Active " ;
VAL_ 613 RollingCounter_ABS3_ 0 " Valid value " 15 " Invalid value " ;
VAL_ 616 HCU_ChrgDchrgSts 0 " Charging " 1 " Discharging " 2 " Invalid " 3 " Reserved " ;
VAL_ 616 HCU_BattLowTemWarn 0 " Normal " 1 " Battery temperature is too low, plug in heating  " 2 " Battery temperature is low, vehicle cannot start normal; Please wait, battery is being heating  " 3 " Reserved " ;
VAL_ 616 HCU_BattLowHeatSts 0 " No Display " 1 " PTC heating is complete " 2 " Plug in heating is complete " 3 " Reserved " ;
VAL_ 616 HCU_EnrgFlowInd_DHT 0 " Mode 1 Vehicle standstill " 1 " mode 2 Vehicle standstill,engine start " 2 " mode 3 BSG generate electricity when engine idling " 3 " mode 4 Engine idling,brake recuperation of the front wheels " 4 " mode 5 Generate electricity and TM generates electricity " 5 " mode 6 TM drive the vehicle,only " 6 " mode 7 Engine drives the vehicle only " 7 " mode 8 Engine and battery generate electricity to TM driving vehicle at the same time " 8 " mode 9 engine generates electricity to TM-driven vehicles " 9 " mode 10 engine drive and BSG generate electricity " 10 " mode 11 plug-in-charging " 11 " mode 12 plug-in-warming " 12 " mode 13 plug-in-charging&warming " 13 " Reserved " ;
VAL_ 621 FPAS_ObjFLCornrAr1_ 0 " No object " 1 " Object in zone 1, 0~10cm " 2 " Object in zone 2, 11~20cm " 3 " Object in zone 3, 21~30cm " 4 " Object in zone 4, 31~40cm " 5 " Object in zone 5, 41~50cm " 6 " Object in zone 6, 51~60cm " 7 " Reserved " ;
VAL_ 621 FPAS_ObjFLCornrAr2_ 0 " No object " 1 " Object in zone 1, 0~10cm " 2 " Object in zone 2, 11~20cm " 3 " Object in zone 3, 21~30cm " 4 " Object in zone 4, 31~40cm " 5 " Object in zone 5, 41~50cm " 6 " Object in zone 6, 51~60cm " 7 " Reserved " ;
VAL_ 621 FPAS_ObjFLMidlAr1_ 0 " No object " 1 " Object in zone 1, 0~10cm " 2 " Object in zone 2, 11~20cm " 3 " Object in zone 3, 21~30cm " 4 " Object in zone 4, 31~40cm " 5 " Object in zone 5, 41~50cm " 6 " Object in zone 6, 51~60cm " 7 " Object in zone 7, 61~70cm " 8 " Object in zone 8, 71~80cm " 9 " Object in zone 9, 81~90cm " 10 " Object in zone 10, 91~100cm " 11 " Reserved " ;
VAL_ 621 FPAS_ObjFLMidlAr2_ 0 " No object " 1 " Object in zone 1, 0~10cm " 2 " Object in zone 2, 11~20cm " 3 " Object in zone 3, 21~30cm " 4 " Object in zone 4, 31~40cm " 5 " Object in zone 5, 41~50cm " 6 " Object in zone 6, 51~60cm " 7 " Object in zone 7, 61~70cm " 8 " Object in zone 8, 71~80cm " 9 " Object in zone 9, 81~90cm " 10 " Object in zone 10, 91~100cm " 11 " Reserved " ;
VAL_ 621 FPAS_ObjFRMidlAr1_ 0 " No object " 1 " Object in zone 1, 0~10cm " 2 " Object in zone 2, 11~20cm " 3 " Object in zone 3, 21~30cm " 4 " Object in zone 4, 31~40cm " 5 " Object in zone 5, 41~50cm " 6 " Object in zone 6, 51~60cm " 7 " Object in zone 7, 61~70cm " 8 " Object in zone 8, 71~80cm " 9 " Object in zone 9, 81~90cm " 10 " Object in zone 10, 91~100cm " 11 " Reserved " ;
VAL_ 621 FPAS_ObjFRMidlAr2_ 0 " No object " 1 " Object in zone 1, 0~10cm " 2 " Object in zone 2, 11~20cm " 3 " Object in zone 3, 21~30cm " 4 " Object in zone 4, 31~40cm " 5 " Object in zone 5, 41~50cm " 6 " Object in zone 6, 51~60cm " 7 " Object in zone 7, 61~70cm " 8 " Object in zone 8, 71~80cm " 9 " Object in zone 9, 81~90cm " 10 " Object in zone 10, 91~100cm " 11 " Reserved " ;
VAL_ 621 FPAS_ObjFRCornrAr1_ 0 " No object " 1 " Object in zone 1, 0~10cm " 2 " Object in zone 2, 11~20cm " 3 " Object in zone 3, 21~30cm " 4 " Object in zone 4, 31~40cm " 5 " Object in zone 5, 41~50cm " 6 " Object in zone 6, 51~60cm " 7 " Reserved " ;
VAL_ 621 FPAS_ObjFRCornrAr2_ 0 " No object " 1 " Object in zone 1, 0~10cm " 2 " Object in zone 2, 11~20cm " 3 " Object in zone 3, 21~30cm " 4 " Object in zone 4, 31~40cm " 5 " Object in zone 5, 41~50cm " 6 " Object in zone 6, 51~60cm " 7 " Reserved " ;
VAL_ 621 FPAS_FLCornrSnsrFltSts 0 " no failure " 1 " failure " ;
VAL_ 621 FPAS_FLMiddlSnsrFltSts 0 " no failure " 1 " failure " ;
VAL_ 621 FPAS_FRMiddlSnsrFltSts 0 " no failure " 1 " failure " ;
VAL_ 621 FPAS_FRCornrSnsrFltSts 0 " no failure " 1 " failure " ;
VAL_ 621 FPAS_WorkSts_ 0 " Disable " 1 " Enable " 2 " Active " 3 " Failed " ;
VAL_ 621 FPAS_AutoModSts_ 0 " Not available " 1 " available " ;
VAL_ 621 FPAS_SoundIndcn_ 0 " Tone zero  No warning " 1 " Tone one  Long beep " 2 " Tone two 1.5 Hz " 3 " Tone three 3Hz " ;
VAL_ 621 FPAS_NearBrrdstn_ 0 " Valid value " 101 " Reserved " 127 " No Display " ;
VAL_ 622 RPAS_RLCornrSnsrFailSts_ 0 " Sensor normal " 1 " Sensor fault " ;
VAL_ 622 RPAS_RLMiddlSnsrFailSts_ 0 " Sensor normal " 1 " Sensor fault " ;
VAL_ 622 RPAS_RRMiddlSnsrFailSts_ 0 " Sensor normal " 1 " Sensor fault " ;
VAL_ 622 RPAS_RRCornrSnsrFailSts_ 0 " Sensor normal " 1 " Sensor fault " ;
VAL_ 622 RPAS_WorkSts_ 0 " Disable " 1 " Enable " 2 " Active " 3 " Failed " ;
VAL_ 622 RPAS_SoundIndcn_ 0 " Tone 0-No warning " 1 " Tone 1-Long beep " 2 " Tone 2-1.5 Hz " 3 " Tone 3-3Hz " ;
VAL_ 622 MEBWorkSts_ 0 " Off " 1 " Enable " 2 " Active " 3 " Failed " ;
VAL_ 622 MEB_EnableSts_ 0 " Disable " 1 " Enable " ;
VAL_ 622 RPAS_ObjRRCornrAr1_ 0 " No object " 1 " Object in zone 1, 0~10cm " 2 " Object in zone 2, 11~20cm " 3 " Object in zone 3, 21~30cm " 4 " Object in zone 4, 31~40cm " 5 " Object in zone 5, 41~50cm " 6 " Object in zone 6, 51~60cm " 7 " Reserved " ;
VAL_ 622 RPAS_ObjRRCornrAr2_ 0 " No object " 1 " Object in zone 1, 0~10cm " 2 " Object in zone 2, 11~20cm " 3 " Object in zone 3, 21~30cm " 4 " Object in zone 4, 31~40cm " 5 " Object in zone 5, 41~50cm " 6 " Object in zone 6, 51~60cm " 7 " Reserved " ;
VAL_ 622 RPAS_ObjRRMidlAr1_ 0 " No object " 1 " Object in zone 1, 0~10cm " 2 " Object in zone 2, 11~20cm " 3 " Object in zone 3, 21~30cm " 4 " Object in zone 4, 31~40cm " 5 " Object in zone 5, 41~50cm " 6 " Object in zone 6, 51~60cm " 7 " Object in zone 7, 61~70cm " 8 " Object in zone 8, 71~80cm " 9 " Object in zone 9, 81~90cm " 10 " Object in zone 10, 91~100cm " 11 " Object in zone 11, 101~110cm " 12 " Object in zone 12, 111~120cm " 13 " Object in zone 13, 121~130cm " 14 " Object in zone 14, 131~140cm " 15 " Object in zone 15, 141~150cm " ;
VAL_ 622 RPAS_ObjRRMidlAr2_ 0 " No object " 1 " Object in zone 1, 0~10cm " 2 " Object in zone 2, 11~20cm " 3 " Object in zone 3, 21~30cm " 4 " Object in zone 4, 31~40cm " 5 " Object in zone 5, 41~50cm " 6 " Object in zone 6, 51~60cm " 7 " Object in zone 7, 61~70cm " 8 " Object in zone 8, 71~80cm " 9 " Object in zone 9, 81~90cm " 10 " Object in zone 10, 91~100cm " 11 " Object in zone 11, 101~110cm " 12 " Object in zone 12, 111~120cm " 13 " Object in zone 13, 121~130cm " 14 " Object in zone 14, 131~140cm " 15 " Object in zone 15, 141~150cm " ;
VAL_ 622 RPAS_ObjRLMidlAr1_ 0 " No object " 1 " Object in zone 1, 0~10cm " 2 " Object in zone 2, 11~20cm " 3 " Object in zone 3, 21~30cm " 4 " Object in zone 4, 31~40cm " 5 " Object in zone 5, 41~50cm " 6 " Object in zone 6, 51~60cm " 7 " Object in zone 7, 61~70cm " 8 " Object in zone 8, 71~80cm " 9 " Object in zone 9, 81~90cm " 10 " Object in zone 10, 91~100cm " 11 " Object in zone 11, 101~110cm " 12 " Object in zone 12, 111~120cm " 13 " Object in zone 13, 121~130cm " 14 " Object in zone 14, 131~140cm " 15 " Object in zone 15, 141~150cm " ;
VAL_ 622 RPAS_ObjRLMidlAr2_ 0 " No object " 1 " Object in zone 1, 0~10cm " 2 " Object in zone 2, 11~20cm " 3 " Object in zone 3, 21~30cm " 4 " Object in zone 4, 31~40cm " 5 " Object in zone 5, 41~50cm " 6 " Object in zone 6, 51~60cm " 7 " Object in zone 7, 61~70cm " 8 " Object in zone 8, 71~80cm " 9 " Object in zone 9, 81~90cm " 10 " Object in zone 10, 91~100cm " 11 " Object in zone 11, 101~110cm " 12 " Object in zone 12, 111~120cm " 13 " Object in zone 13, 121~130cm " 14 " Object in zone 14, 131~140cm " 15 " Object in zone 15, 141~150cm " ;
VAL_ 622 RPAS_ObjRLCornrAr1_ 0 " No object " 1 " Object in zone 1, 0~10cm " 2 " Object in zone 2, 11~20cm " 3 " Object in zone 3, 21~30cm " 4 " Object in zone 4, 31~40cm " 5 " Object in zone 5, 41~50cm " 6 " Object in zone 6, 51~60cm " 7 " Reserved " ;
VAL_ 622 RPAS_ObjRLCornrAr2_ 0 " No object " 1 " Object in zone 1, 0~10cm " 2 " Object in zone 2, 11~20cm " 3 " Object in zone 3, 21~30cm " 4 " Object in zone 4, 31~40cm " 5 " Object in zone 5, 41~50cm " 6 " Object in zone 6, 51~60cm " 7 " Reserved " ;
VAL_ 623 CheckSum_HUT32 0 " Valid value " ;
VAL_ 623 ScrnOpSts 0 " Release " 1 " Pressed " 2 " Hold " 3 " Reserved " ;
VAL_ 623 XLvl 0 " Valid value " 1961 " Invalid " ;
VAL_ 623 YLvl 0 " Valid value " 721 " Invalid " ;
VAL_ 623 DetVideoLost 0 " Nomal " 1 " Video lost " ;
VAL_ 623 PrkgCtrlModReqValid 0 " valid " 1 " invalid " ;
VAL_ 623 PrkgCtrlModReq 0 " No action " 1 " Parking in car " 2 " Remote parking " 3 " Reserved " ;
VAL_ 623 ContnPrkgReqValid 0 " valid " 1 " invalid " ;
VAL_ 623 ContnPrkgReq 0 " 0x1 select continue parking " 2 " cancle parking " 3 " invalid " ;
VAL_ 623 VolLampDispSts 0 " Segment_0 " 1 " Segment_1 " 2 " Segment_2 " 3 " Segment_3 " 4 " Segment_4 " 5 " Segment_5 " 6 " Segment_6 " 7 " Segment_7 " 8 " Segment_8 " 9 " Error " 10 " Reserved " ;
VAL_ 623 RollingCounter_HUT32 0 " Valid value " 15 " Invalid value " ;
VAL_ 625 FuelConsumption 0 " Valid values  " ;
VAL_ 625 TgtCrsVehSpd 0 " Valid values  " ;
VAL_ 625 CruiseCtrlSts 0 " Inactive  " 1 " Active " 2 " Standby " 3 " Reserved " ;
VAL_ 625 AccelPedalPosnVldty 0 " Invalid " 1 " Valid " 2 " Init value " 3 " Reserved " ;
VAL_ 625 EngSVSSig 0 " SVS off " 1 " SVS on " ;
VAL_ 625 MILSts 0 " Off " 1 " On " ;
VAL_ 625 EngState 0 " Stopped " 1 " Cranking " 2 " Running " 3 " Stalling " ;
VAL_ 625 AccelPedalPosn 0 " Valid values  " ;
VAL_ 627 TrailerSts 0 " Trailer off " 1 " Trailer on " ;
VAL_ 628 AutoAVMSwtSet_Sts 0 " Off " 1 " ON " ;
VAL_ 628 AVM_CurrSts 0 " Off " 1 " ON " 2 " AVM no video（雷达模式） " 3 " Reserved " ;
VAL_ 628 GuidOvlSts 0 " Around View and Single View " 1 " Only Around View  " 2 " Only Single View  " 3 " No Guidance  " ;
VAL_ 628 FrntCamInpFailSts 0 " no failure " 1 " failure " ;
VAL_ 628 RearCamInpFailSts 0 " no failure " 1 " failure " ;
VAL_ 628 LeCamInpFailSts 0 " no failure " 1 " failure " ;
VAL_ 628 RiCamInpFailSts 0 " no failure " 1 " failure " ;
VAL_ 628 EolNotCmpltd 0 " Ccompleted " 1 " No completed " ;
VAL_ 628 OvlOpFailSts 0 " no failure " 1 " failure " ;
VAL_ 628 LaneCalSts 0 " No Commands " 1 " In Calibration process " 2 " Calibration success " 3 " Calibration failure " ;
VAL_ 628 RadarDispSts 0 " Both Around View and Single View Radar Display " 1 " Only Around View Radar Display " 2 " Only Single View Radar Display " 3 " No Radar Display " ;
VAL_ 628 LaneCalFltSts 0 " No fault " 1 " Front view Calibration abnormal " 2 " Rear view Calibration abnormal " 3 " left view Calibration abnormal " 4 " Right view Calibration abnormal " 5 " Calibration data storage failed " 6 " Reserved " ;
VAL_ 628 AutoViewChgFuncSts 0 " Off " 1 " ON " ;
VAL_ 628 CarMdlTrsprcySts 0 " Opaque " 1 " Translucent " 2 " Completely transparent " 3 " Reserved " ;
VAL_ 628 CarMdlDispSts 0 " 2D mode " 1 " 3D mode " ;
VAL_ 628 CurrCalResultSts 0 " Use Factory Calibration Result " 1 " Use Lane Calibration Result " ;
VAL_ 628 MdlColrSts 0 " Silvery " 1 " Red " 2 " Gray " 3 " White " 4 " Black " 5 " Brown " 6 " Blue " 7 " Orange " 8 " Green " 9 " Gold " 10 " Purple " 11 " Reserved " ;
VAL_ 628 SigViewIndcn 0 " No Commands " 1 " Front to Center View " 2 " Rear to Center View  " 3 " Left to Center View " 4 " Right to Center View " 5 " Left Front to Center View " 6 " Right Front to Center View " 7 " Left Rear to Center View " 8 " Right Rear to Center View " 9 " Front View " 10 " Rear View " 11 " Left View " 12 " Right View " 13 " Left Turn 3D View " 14 " Right Turn 3D View " 15 " Front Overlook View " 16 " Rear Overlook View " 17 " Front 180 Deg View " 18 " Rear 180 Deg View " 19 " Front Wheel View " 20 " Rear Wheel View " 21 " Front Wash View " 22 " Rear Wash View " 23 " Free_3D View " 24 " LeftRight View " 25 " Engine Room View " 26 " CCO View " 27 " Reserved " 63 " 3D Car Model Round View " ;
VAL_ 628 HAP_DispCmd 0 " OFF " 1 " ON " ;
VAL_ 628 AVM_3DAngSts 0 " Not active " 1 " 0~360° " 362 " reserved " 511 " invalid " ;
VAL_ 628 MOD_WorkSts 0 " OFF " 1 " ON " ;
VAL_ 628 HAP_Hmi_Index 0 " Reserved " 1 " Main Screen " 2 " EOL/Test " 3 " P2P Screen " 4 " Assist Screen " 5 " Reserved " ;
VAL_ 628 DVRWorkSts 0 " DVR_Standby " 1 " DVR_Active " 2 " DVR_InterFailed " 3 " DVR_NetFailed " ;
VAL_ 628 MOD_AlarmSts 0 " OFF " 1 " ON " ;
VAL_ 639 CheckSum_IP2 0 " Valid values " ;
VAL_ 639 IP_DrvSeatBeltWarnLmpFailSts 0 " No failure " 1 " Failure " 2 " Signal not available " 3 " Reserved " ;
VAL_ 639 IP_PassSeatBeltWarnLmpFailSts 0 " No failure " 1 " Failure " 2 " Signal not available " 3 " Reserved " ;
VAL_ 639 IP_VehTotDistance 0 " 0-9999999-km " 10000000 " Reserved " 16777215 " Invalid " ;
VAL_ 639 IP_FuelLvlInfo 0 " Valid Value " 201 " Reserved " 255 " Invalid Value " ;
VAL_ 639 IP_FuelLvlLowLmpSts 0 " OFF " 1 " ON " 2 " Internal Error " 3 " Reserved " ;
VAL_ 639 IP_BattChrgLmpSts 0 " OFF " 1 " ON " 2 " Internal Error " 3 " Reserved " ;
VAL_ 639 IP_EngOilPressLowLmpSts 0 " OFF " 1 " ON " 2 " Internal Error " 3 " Reserved " ;
VAL_ 639 IP_ABMWarnLmpFailrSts 0 " No failure " 1 " Failure " 2 " Signal not available " 3 " Reserved " ;
VAL_ 639 IP_Err 0 " No error " 1 " Error " ;
VAL_ 639 IP_ACCErr 0 " No error " 1 " Error " ;
VAL_ 639 IP_VehTotDistanceValid 0 " Invalid " 1 " Valid " ;
VAL_ 639 IP_VehSpdUnit 0 " kph " 1 " mph " ;
VAL_ 639 IP_VINcompr 0 " equality " 1 " inequality " ;
VAL_ 639 RollingCounter_IP2 0 " Valid value " 15 " Invalid value " ;
VAL_ 645 BMS_BattHeatRunaway 0 " inactive " 1 " running thermalrunaway " 2 " parking thermalrunaway " 3 " reserved " ;
VAL_ 647 Checksum_HC1 0 " Valid Value " ;
VAL_ 647 HighBeamSts_HC 0 " Off " 1 " On " ;
VAL_ 647 ADBstatus 0 " Off " 1 " ON " 2 " error " 3 " Reserved " ;
VAL_ 647 LeftLowBeamFailSts 0 " No failure " 1 " Failure " ;
VAL_ 647 RightLowBeamFailSts 0 " No failure " 1 " Failure " ;
VAL_ 647 LeftHighBeamFailSts 0 " No failure " 1 " Failure " ;
VAL_ 647 RightHighBeamFailSts 0 " No failure " 1 " Failure " ;
VAL_ 647 ALS_FailSts 0 " No failure " 1 " Failure " ;
VAL_ 647 RollingCounter_HC1 0 " Valid value " 15 " Invalid value " ;
VAL_ 652 VolSwtReq 0 " No request " 1 " Request " ;
VAL_ 652 VolSwtErrSts 0 " No Error " 1 " Error " ;
VAL_ 656 PressReliProgs 0 " value " 100 " Finish " 101 " reserved " ;
VAL_ 656 FTIVFault 0 " No warning " 1 " Warning " ;
VAL_ 656 FuelTankCapWarning 0 " No warning " 1 " Warning(Fuel tank cap did not close) " 2 " Reserved " 3 " Fault(Fuel tank cap did not open) " ;
VAL_ 659 IP_CurrTheme 0 " Valid Value " 4 " Initial value " 5 " Reserved " ;
VAL_ 659 IP_VehSpdDisp 0 " Valid " 511 " Invalid " ;
VAL_ 659 IP_FuelMainTankR 0 " Invalid value " 1 " Reserved " 10 " Valid value " 1001 " Reserved " 1023 " Invalid value " ;
VAL_ 659 IP_FuelAuxTankR 0 " Invalid value " 1 " Reserved " 10 " Valid value " 1001 " Reserved " 1023 " Invalid value " ;
VAL_ 659 IP_VelSpdDisp_Mile 0 " Valid " 255 " Invalid " ;
VAL_ 659 IP_LagueSet 0 " Chinese " 1 " English " 2 " Russian " 3 " Spaish " 4 " Portuguese " 5 " German " 6 " French " 7 " Italian " 8 " Arabic " 9 " Thai " 10 " Ukrainian " 11 " Indonesian  " 12 " Reserve " 15 " Invalid value  " ;
VAL_ 661 SysPowerMod 0 " OFF " 1 " ACC (reserved) " 2 " ON " 3 " Crank " ;
VAL_ 661 SysPowerModVld 0 " Invalid " 1 " Valid " ;
VAL_ 664 RPAS_NearBrrdstn_ 0 " Valid value " 151 " Reserved " 255 " No Display " ;
VAL_ 664 APS_ObjRiSideAr1 0 " No object " 1 " Object in zone 1, 0~10cm " 2 " Object in zone 2, 11~20cm " 3 " Object in zone 3, 21~30cm " 4 " Object in zone 4, 31~40cm " 5 " Object in zone 5, 41~50cm " 6 " Object in zone 6, 51~60cm " 7 " Reserved " ;
VAL_ 664 APS_ObjRiSideAr2 0 " No object " 1 " Object in zone 1, 0~10cm " 2 " Object in zone 2, 11~20cm " 3 " Object in zone 3, 21~30cm " 4 " Object in zone 4, 31~40cm " 5 " Object in zone 5, 41~50cm " 6 " Object in zone 6, 51~60cm " 7 " Reserved " ;
VAL_ 664 APS_ObjRiSideAr3 0 " No object " 1 " Object in zone 1, 0~10cm " 2 " Object in zone 2, 11~20cm " 3 " Object in zone 3, 21~30cm " 4 " Object in zone 4, 31~40cm " 5 " Object in zone 5, 41~50cm " 6 " Object in zone 6, 51~60cm " 7 " Reserved " ;
VAL_ 664 APS_ObjRiSideAr4 0 " No object " 1 " Object in zone 1, 0~10cm " 2 " Object in zone 2, 11~20cm " 3 " Object in zone 3, 21~30cm " 4 " Object in zone 4, 31~40cm " 5 " Object in zone 5, 41~50cm " 6 " Object in zone 6, 51~60cm " 7 " Reserved " ;
VAL_ 664 APS_ObjRiSideAr5 0 " No object " 1 " Object in zone 1, 0~10cm " 2 " Object in zone 2, 11~20cm " 3 " Object in zone 3, 21~30cm " 4 " Object in zone 4, 31~40cm " 5 " Object in zone 5, 41~50cm " 6 " Object in zone 6, 51~60cm " 7 " Reserved " ;
VAL_ 664 APS_ObjLeSideAr1 0 " No object " 1 " Object in zone 1, 0~10cm " 2 " Object in zone 2, 11~20cm " 3 " Object in zone 3, 21~30cm " 4 " Object in zone 4, 31~40cm " 5 " Object in zone 5, 41~50cm " 6 " Object in zone 6, 51~60cm " 7 " Reserved " ;
VAL_ 664 APS_ObjLeSideAr2 0 " No object " 1 " Object in zone 1, 0~10cm " 2 " Object in zone 2, 11~20cm " 3 " Object in zone 3, 21~30cm " 4 " Object in zone 4, 31~40cm " 5 " Object in zone 5, 41~50cm " 6 " Object in zone 6, 51~60cm " 7 " Reserved " ;
VAL_ 664 APS_ObjLeSideAr3 0 " No object " 1 " Object in zone 1, 0~10cm " 2 " Object in zone 2, 11~20cm " 3 " Object in zone 3, 21~30cm " 4 " Object in zone 4, 31~40cm " 5 " Object in zone 5, 41~50cm " 6 " Object in zone 6, 51~60cm " 7 " Reserved " ;
VAL_ 664 APS_ObjLeSideAr4 0 " No object " 1 " Object in zone 1, 0~10cm " 2 " Object in zone 2, 11~20cm " 3 " Object in zone 3, 21~30cm " 4 " Object in zone 4, 31~40cm " 5 " Object in zone 5, 41~50cm " 6 " Object in zone 6, 51~60cm " 7 " Reserved " ;
VAL_ 664 APS_ObjLeSideAr5 0 " No object " 1 " Object in zone 1, 0~10cm " 2 " Object in zone 2, 11~20cm " 3 " Object in zone 3, 21~30cm " 4 " Object in zone 4, 31~40cm " 5 " Object in zone 5, 41~50cm " 6 " Object in zone 6, 51~60cm " 7 " Reserved " ;
VAL_ 664 APS_FRSideSnsrFailSts 0 " no failure " 1 " failure " ;
VAL_ 664 APS_FLSideSnsrFailSts 0 " no failure " 1 " failure " ;
VAL_ 664 APS_RRSideSnsrFailSts 0 " no failure " 1 " failure " ;
VAL_ 664 APS_RLSideSnsrFailSts 0 " no failure " 1 " failure " ;
VAL_ 664 SDW_SoundIndcn 0 " Tone 0 - No warning " 1 " Tone 1 - Long beep " 2 " Tone 2 - 1.5 Hz " 3 " Tone 3 - 3Hz " ;
VAL_ 664 SDWActiveSts 0 " Not active " 1 " Active " ;
VAL_ 664 RPAS_ObjRRCornrAr1 0 " No object " 1 " Object in zone 1, 0~10cm " 2 " Object in zone 2, 11~20cm " 3 " Object in zone 3, 21~30cm " 4 " Object in zone 4, 31~40cm " 5 " Object in zone 5, 41~50cm " 6 " Object in zone 6, 51~60cm " 7 " Reserved " ;
VAL_ 664 RPAS_ObjRRCornrAr2 0 " No object " 1 " Object in zone 1, 0~10cm " 2 " Object in zone 2, 11~20cm " 3 " Object in zone 3, 21~30cm " 4 " Object in zone 4, 31~40cm " 5 " Object in zone 5, 41~50cm " 6 " Object in zone 6, 51~60cm " 7 " Reserved " ;
VAL_ 664 RPAS_ObjRRMidlAr1 0 " No object " 1 " Object in zone 1, 0~10cm " 2 " Object in zone 2, 11~20cm " 3 " Object in zone 3, 21~30cm " 4 " Object in zone 4, 31~40cm " 5 " Object in zone 5, 41~50cm " 6 " Object in zone 6, 51~60cm " 7 " Object in zone 7, 61~70cm " 8 " Object in zone 8, 71~80cm " 9 " Object in zone 9, 81~90cm " 10 " Object in zone 10, 91~100cm " 11 " Object in zone 11, 101~110cm " 12 " Object in zone 12, 111~120cm " 13 " Object in zone 13, 121~130cm " 14 " Object in zone 14, 131~140cm " 15 " Object in zone 15, 141~150cm " ;
VAL_ 664 RPAS_ObjRRMidlAr2 0 " No object " 1 " Object in zone 1, 0~10cm " 2 " Object in zone 2, 11~20cm " 3 " Object in zone 3, 21~30cm " 4 " Object in zone 4, 31~40cm " 5 " Object in zone 5, 41~50cm " 6 " Object in zone 6, 51~60cm " 7 " Object in zone 7, 61~70cm " 8 " Object in zone 8, 71~80cm " 9 " Object in zone 9, 81~90cm " 10 " Object in zone 10, 91~100cm " 11 " Object in zone 11, 101~110cm " 12 " Object in zone 12, 111~120cm " 13 " Object in zone 13, 121~130cm " 14 " Object in zone 14, 131~140cm " 15 " Object in zone 15, 141~150cm " ;
VAL_ 664 RPAS_ObjRLMidlAr1 0 " No object " 1 " Object in zone 1, 0~10cm " 2 " Object in zone 2, 11~20cm " 3 " Object in zone 3, 21~30cm " 4 " Object in zone 4, 31~40cm " 5 " Object in zone 5, 41~50cm " 6 " Object in zone 6, 51~60cm " 7 " Object in zone 7, 61~70cm " 8 " Object in zone 8, 71~80cm " 9 " Object in zone 9, 81~90cm " 10 " Object in zone 10, 91~100cm " 11 " Object in zone 11, 101~110cm " 12 " Object in zone 12, 111~120cm " 13 " Object in zone 13, 121~130cm " 14 " Object in zone 14, 131~140cm " 15 " Object in zone 15, 141~150cm " ;
VAL_ 664 RPAS_ObjRLMidlAr2 0 " No object " 1 " Object in zone 1, 0~10cm " 2 " Object in zone 2, 11~20cm " 3 " Object in zone 3, 21~30cm " 4 " Object in zone 4, 31~40cm " 5 " Object in zone 5, 41~50cm " 6 " Object in zone 6, 51~60cm " 7 " Object in zone 7, 61~70cm " 8 " Object in zone 8, 71~80cm " 9 " Object in zone 9, 81~90cm " 10 " Object in zone 10, 91~100cm " 11 " Object in zone 11, 101~110cm " 12 " Object in zone 12, 111~120cm " 13 " Object in zone 13, 121~130cm " 14 " Object in zone 14, 131~140cm " 15 " Object in zone 15, 141~150cm " ;
VAL_ 664 RPAS_ObjRLCornrAr1 0 " No object " 1 " Object in zone 1, 0~10cm " 2 " Object in zone 2, 11~20cm " 3 " Object in zone 3, 21~30cm " 4 " Object in zone 4, 31~40cm " 5 " Object in zone 5, 41~50cm " 6 " Object in zone 6, 51~60cm " 7 " Reserved " ;
VAL_ 664 RPAS_ObjRLCornrAr2 0 " No object " 1 " Object in zone 1, 0~10cm " 2 " Object in zone 2, 11~20cm " 3 " Object in zone 3, 21~30cm " 4 " Object in zone 4, 31~40cm " 5 " Object in zone 5, 41~50cm " 6 " Object in zone 6, 51~60cm " 7 " Reserved " ;
VAL_ 664 RPAS_RLCornrSnsrFailSts 0 " no failure " 1 " failure " ;
VAL_ 664 RPAS_RLMiddlSnsrFailSts 0 " no failure " 1 " failure " ;
VAL_ 664 RPAS_RRMiddlSnsrFailSts 0 " no failure " 1 " failure " ;
VAL_ 664 RPAS_RRCornrSnsrFailSts 0 " no failure " 1 " failure " ;
VAL_ 664 RPAS_WorkSts 0 " Disable " 1 " Enable " 2 " Active " 3 " Failed " ;
VAL_ 664 RPAS_SoundIndcn 0 " Tone zero No warning " 1 " Tone one  Long beep " 2 " Tone two 1.5 Hz " 3 " Tone three  3Hz " ;
VAL_ 664 MEBWorkSts 0 " Off " 1 " Enable " 2 " Active " 3 " Failed " ;
VAL_ 664 MEB_EnableSts 0 " Disable " 1 " Enable " ;
VAL_ 664 FPAS_ObjFLCornrAr1 0 " No object " 1 " Object in zone 1, 0~10cm " 2 " Object in zone 2, 11~20cm " 3 " Object in zone 3, 21~30cm " 4 " Object in zone 4, 31~40cm " 5 " Object in zone 5, 41~50cm " 6 " Object in zone 6, 51~60cm " 7 " Reserved " ;
VAL_ 664 FPAS_ObjFLCornrAr2 0 " No object " 1 " Object in zone 1, 0~10cm " 2 " Object in zone 2, 11~20cm " 3 " Object in zone 3, 21~30cm " 4 " Object in zone 4, 31~40cm " 5 " Object in zone 5, 41~50cm " 6 " Object in zone 6, 51~60cm " 7 " Reserved " ;
VAL_ 664 FPAS_ObjFLMidlAr1 0 " No object " 1 " Object in zone 1, 0~10cm " 2 " Object in zone 2, 11~20cm " 3 " Object in zone 3, 21~30cm " 4 " Object in zone 4, 31~40cm " 5 " Object in zone 5, 41~50cm " 6 " Object in zone 6, 51~60cm " 7 " Object in zone 7, 61~70cm " 8 " Object in zone 8, 71~80cm " 9 " Object in zone 9, 81~90cm " 10 " Object in zone 10, 91~100cm " 11 " Reserved " ;
VAL_ 664 FPAS_ObjFLMidlAr2 0 " No object " 1 " Object in zone 1, 0~10cm " 2 " Object in zone 2, 11~20cm " 3 " Object in zone 3, 21~30cm " 4 " Object in zone 4, 31~40cm " 5 " Object in zone 5, 41~50cm " 6 " Object in zone 6, 51~60cm " 7 " Object in zone 7, 61~70cm " 8 " Object in zone 8, 71~80cm " 9 " Object in zone 9, 81~90cm " 10 " Object in zone 10, 91~100cm " 11 " Reserved " ;
VAL_ 664 FPAS_ObjFRMidlAr1 0 " No object " 1 " Object in zone 1, 0~10cm " 2 " Object in zone 2, 11~20cm " 3 " Object in zone 3, 21~30cm " 4 " Object in zone 4, 31~40cm " 5 " Object in zone 5, 41~50cm " 6 " Object in zone 6, 51~60cm " 7 " Object in zone 7, 61~70cm " 8 " Object in zone 8, 71~80cm " 9 " Object in zone 9, 81~90cm " 10 " Object in zone 10, 91~100cm " 11 " Reserved " ;
VAL_ 664 FPAS_ObjFRMidlAr2 0 " No object " 1 " Object in zone 1, 0~10cm " 2 " Object in zone 2, 11~20cm " 3 " Object in zone 3, 21~30cm " 4 " Object in zone 4, 31~40cm " 5 " Object in zone 5, 41~50cm " 6 " Object in zone 6, 51~60cm " 7 " Object in zone 7, 61~70cm " 8 " Object in zone 8, 71~80cm " 9 " Object in zone 9, 81~90cm " 10 " Object in zone 10, 91~100cm " 11 " Reserved " ;
VAL_ 664 FPAS_ObjFRCornrAr1 0 " No object " 1 " Object in zone 1, 0~10cm " 2 " Object in zone 2, 11~20cm " 3 " Object in zone 3, 21~30cm " 4 " Object in zone 4, 31~40cm " 5 " Object in zone 5, 41~50cm " 6 " Object in zone 6, 51~60cm " 7 " Reserved " ;
VAL_ 664 FPAS_ObjFRCornrAr2 0 " No object " 1 " Object in zone 1, 0~10cm " 2 " Object in zone 2, 11~20cm " 3 " Object in zone 3, 21~30cm " 4 " Object in zone 4, 31~40cm " 5 " Object in zone 5, 41~50cm " 6 " Object in zone 6, 51~60cm " 7 " Reserved " ;
VAL_ 664 FPAS_FLCornrSnsrFailSts 0 " no failure " 1 " failure " ;
VAL_ 664 FPAS_FLMiddlSnsrFailSts 0 " no failure " 1 " failure " ;
VAL_ 664 FPAS_FRMiddlSnsrFailSts 0 " no failure " 1 " failure " ;
VAL_ 664 FPAS_FRCornrSnsrFailSts 0 " no failure " 1 " failure " ;
VAL_ 664 FPAS_WorkSts 0 " Disable " 1 " Enable " 2 " Active " 3 " Failed " ;
VAL_ 664 FPAS_AutoModSts 0 " Not available " 1 " available " ;
VAL_ 664 FPAS_SoundIndcn 0 " Tone zero  No warning " 1 " Tone one  Long beep " 2 " Tone two 1.5 Hz " 3 " Tone three 3Hz " ;
VAL_ 664 FPAS_NearBrrdstn 0 " Valid value " 101 " Reserved " 127 " No Display " ;
VAL_ 664 APA_MenuDispCtrlCmd 0 " No_Disp_avm_menu " 1 " park_in_indicate_menu " 2 " park_in_select_slot_menu " 3 " park_in_mode_select_menu " 4 " park_in_process " 5 " remote_park_in_process " 6 " park_out_confirm_menu " 7 " park_out_process " 8 " park_in_indicate_menu_NoRPA " 9 " park_in_select_slot_menu_NoRPA " 10 " park_in_mode_select_menu_NoRPA " 11 " park_out _indicate_menu " 12 " Reversed " ;
VAL_ 664 APA_FuncSts 0 " APA Function standby " 1 " APA Function active " 2 " APA Function disable " 3 " Reserved " ;
VAL_ 664 P2P_FuncSts 0 " P2P Functionstandby " 1 " P2P Function active " 2 " P2P Function disable " 3 " Reserved " ;
VAL_ 664 RADS_FuncSts 0 " Reverse Asist Function standby " 1 " Reverse Asist Function active " 2 " Reverse Asist Function disable " 3 " Reserved " ;
VAL_ 664 FADS_FuncSts 0 " FADS Function standby " 1 " FADS Function active " 2 " FADS Function disable " 3 " Reserved " ;
VAL_ 664 HAP_TextIconDispCtrl 0 " No display " 1 " Display according to text info " 2 " Display parking mode  " 3 " Reserved " ;
VAL_ 669 InCarTemp 0 " Valid value " 254 " Initial value " 255 " Invalid value " ;
VAL_ 669 ACAQSEnaSts 0 " Disable " 1 " Enable " ;
VAL_ 669 ACOperMod 0 " Economy Mode " 1 " Standard Mode " 2 " Strong Mode " 3 " Reserved " ;
VAL_ 669 ACAIUEnaSts 0 " Disable " 1 " Enable " ;
VAL_ 669 ACDrvAirDistriMod 0 " Face " 1 " Face & Foot " 2 " Foot " 3 " Foot & Defrost " 4 " Defrost " 5 " Reserved " 7 " Auto air distribution mode " ;
VAL_ 669 ACSteplessSpdSetEnaSts 0 " Disable " 1 " Enable " ;
VAL_ 669 ACFrntPassTempSteplessSetEnaSts 0 " Disable " 1 " Enable " ;
VAL_ 669 ACDrvTempSteplessSetEnaSts 0 " Disable " 1 " Enable " ;
VAL_ 669 ACEEMSts 0 " Normal mode " 1 " Transport_static mode " 2 " Transport_Dynamic mode " 3 " Static_power saving level 1 " 4 " Static_power saving level 2 " 5 " Dynamic_power saving level 4 " 6 " Dynamic_power saving level 5 " 7 " Power system error " 8 " Reserved " ;
VAL_ 669 ACCbnClnEnasts 0 " Disable " 1 " Enable " ;
VAL_ 669 ACCbnClnOffCode 0 " No offcode " 1 " Any door is open " 2 " SystemPowerMode is not off " 3 " Status of Battery is not ok " 4 " Any door is open and SystemPowerMode is not off " 5 " Status of Battery is not ok and Any door is open " 6 " Status of Battery is not ok and SystemPowerMode is not off " 7 " Status of Battery is not ok and SystemPowerMode is not off and  Any door is open " ;
VAL_ 671 RemoteModSts 0 " Normal mode " 1 " Remote mode " ;
VAL_ 671 PASWorkCmd 0 " OFF " 1 " ON " ;
VAL_ 671 WhistleSts 0 " Off " 1 " On " ;
VAL_ 671 WiprReq_F_Pbox 0 " Wiper Off " 1 " Wiper action once " 2 " Speed1 (Lo) " 3 " Speed2 (Hi) " 4 " Reserved " 7 " Invalid " ;
VAL_ 671 KL30BRelaySts 0 " Off " 1 " On " ;
VAL_ 680 TranPMode_Sts 0 " Normal Mode " 1 " Transport Mode " ;
VAL_ 680 Stat_PwrSv_Lvl 0 " Normal " 1 " Level 1 " 2 " Level 2 " 3 " Reserved " ;
VAL_ 680 DeepSlpCmd 0 " Normal " 1 " Sleep Commend " 2 " Deep Sleep Commend " 3 " Reserved " ;
VAL_ 680 Dyn_PwrSv_Lvl 0 " Normal " 1 " Level 1 " 2 " Level 2 " 3 " Level 3 " 4 " Level 4 " 5 " Level 5 " 6 " Reserved " ;
VAL_ 680 LvPwrSysErr 0 " No error " 1 " error " 2 " Reservrd " ;
VAL_ 683 Checksum_ACC3 0 " Valid value " ;
VAL_ 683 ISL_Resp 0 " OFF " 1 " ON " ;
VAL_ 683 ICA_HandsOffResp 0 " OFF " 1 " ON " ;
VAL_ 683 RollingCounter_ACC3 0 " Valid value " 15 " Invalid value " ;
VAL_ 683 Checksum_ACC4 0 " Valid value " ;
VAL_ 683 ACC_ObjDetecte 0 " No object " 1 " Target object detected " ;
VAL_ 683 ACC_TakeOverReq 0 " No TakeOver request " 1 " Valid TakeOver request " ;
VAL_ 683 ACC_InterSysInfoDisp 0 " No display " 1 " Unable to activate ACC due to speed not achive " 2 " ACC active control is cancelled " 3 " Resvered " 4 " ACC and PEBS temporary unavailable " 5 " Unable to activate ACC due to other limitation(except speed not achive) " 6 " ACC and PEBS error " 7 " ACC temporary unavailable " 8 " Resvered " 9 " Blindness " 10 " Resvered " ;
VAL_ 683 ACC_ModDisp 0 " OFF Mode " 1 " Passive Mode " 2 " StandBy Mode " 3 " Active-Control Mode " 4 " Brake-Only Mode " 5 " Override " 6 " Reserved " 7 " ACC and PEBS Failure mode " 8 " ACC Failure mode  " 9 " Reserved " ;
VAL_ 683 ACC_FctSts 0 " Fuction Not  Available " 1 " Fuction Available  " 2 " Performance degradation " 3 " Reserved " ;
VAL_ 683 ACC_TgtObjBarDisp 0 " No display " 1 " Distance_1 one bar " 2 " Distance_2 two bars " 3 " Distance_3 three bars " 4 " Distance_4 four bars " 5 " Resvered " ;
VAL_ 683 ACC_TimeGapSet 0 " No display " 1 " TimeGap_1 1s " 2 " TimeGap_2 1.4s " 3 " TimeGap_3 1.8s " 4 " TimeGap_4 2.1s " 5 " Reserved " ;
VAL_ 683 ACC_SpdSetValue 0 " Valid value " 255 " No display " ;
VAL_ 683 TJA_ACC_SelSts 0 " off " 1 " ACC selected " 2 " TJA/ICA selected " 3 " Off selected " 4 " ACC on " 5 " TJA/ICA on " 6 " Reserved " ;
VAL_ 683 ISL_InterSysInfoDisp 0 " No display " 1 " Speed Limit Confirm Request " 2 " Speed Limit Take Over Request " 3 " Resvered " ;
VAL_ 683 TJA_ICA_ModDisp 0 " OFF mode " 1 " Passive mode " 2 " Active mode " 3 " Ready mode " 4 " Failure " 5 " Reserved   " ;
VAL_ 683 TJA_ICA_InterSysInfoDisp 0 " No display " 1 " Unable to activate TJA/ICA due to other limitation " 2 " TJA/ICA active control is cancelled " 3 " TJA/ICA   temporarily unavailable    " 4 " Current IGN Cycle Function Inhibit " 5 " Resvered  " ;
VAL_ 683 RollingCounter_ACC4 0 " Valid value " 15 " Invalid value " ;
VAL_ 683 Checksum_ACC6 0 " Valid value " ;
VAL_ 683 ACC_PotentialTgtDy 0 " Valid value " 161 " Reserved " ;
VAL_ 683 ACC_PotentialTgtDx 0 " Valid value " 301 " Reserved " ;
VAL_ 683 ACC_RlvTgtDetn 0 " Not dectected " 1 " Dectected " 2 " Reserved " 3 " Invalid " ;
VAL_ 683 ACC_EgoStatus 0 " No Display " 1 " Override " 2 " Deceleration " 3 " Reserved " ;
VAL_ 683 ACC_RlvTgtDy 0 " Valid value " 161 " Reserved " ;
VAL_ 683 ACC_RlvTgtDx 0 " Valid value " 301 " Reserved " ;
VAL_ 683 ACC_PotentialTgtDetn 0 " Not dectected " 1 " Dectected " 2 " Reserved " 3 " Invalid " ;
VAL_ 683 ACC_PotentialTgtTyp 0 " Unkown " 1 " Sedan " 2 " Truck " 3 " Motorcycle " 4 " Pedestrian " 5 " Bicycle " 6 " Reserved " 7 " Invalid " ;
VAL_ 683 ACC_RlvTgtTyp 0 " Unkown " 1 " Sedan " 2 " Truck " 3 " Motorcycle " 4 " Pedestrian " 5 " Bicycle " 6 " Reserved " 7 " Invalid " ;
VAL_ 683 Request_driveoff 0 " no request " 1 " request " ;
VAL_ 683 RollingCounter_ACC6 0 " Valid value " 15 " Invalid value " ;
VAL_ 683 Checksum_ACC7 0 " Valid value " ;
VAL_ 683 ACC_LeTgtDy 0 " Valid value " 161 " Reserved " ;
VAL_ 683 ACC_LeTgtDx 0 " Valid value " 301 " Reserved " ;
VAL_ 683 ACC_LeTgtTyp 0 " Unkown " 1 " Sedan " 2 " Truck " 3 " Motorcycle " 4 " Pedestrian " 5 " Bicycle " 6 " Reserved " 7 " Invalid " ;
VAL_ 683 ACC_LeTargrtDection 0 " Not dectected " 1 " Dectected " 2 " Reserved " 3 " Invalid " ;
VAL_ 683 ACC_RiTargrtDetn 0 " Not dectected " 1 " Dectected " 2 " Reserved " 3 " Invalid " ;
VAL_ 683 ACC_RiTgtDy 0 " Valid value " 161 " Reserved " ;
VAL_ 683 ACC_RiTgtDx 0 " Valid value " 301 " Reserved " ;
VAL_ 683 ACC_RiTgtTyp 0 " Unkown " 1 " Sedan " 2 " Truck " 3 " Motorcycle " 4 " Pedestrian " 5 " Bicycle " 6 " Reserved " 7 " Invalid " ;
VAL_ 683 RollingCounter_ACC7 0 " Valid value " 15 " Invalid value " ;
